VERSION "Mid5CANFD"

NS_ :

BS_:

BU_: ETC SSM VIM

BO_ 1285 SsmMid5CanFdCanNmFr: 8 SSM
 SG_ Body_SSM : 21|1@0+ (1,0) [0|0] ""  VIM
 SG_ Brake_SSM : 33|1@0+ (1,0) [0|0] ""  VIM
 SG_ Diesel_SSM : 32|1@0+ (1,0) [0|0] ""  VIM
 SG_ Hazard_SSM : 18|1@0+ (1,0) [0|0] ""  VIM
 SG_ InfotainmentAndHMI_SSM : 22|1@0+ (1,0) [0|0] ""  VIM
 SG_ PNCCharging_SSM : 25|1@0+ (1,0) [0|0] ""  VIM
 SG_ PNCDriverinfo_SSM : 16|1@0+ (1,0) [0|0] ""  VIM
 SG_ PNCDriverinfoPoll_SSM : 31|1@0+ (1,0) [0|0] ""  VIM
 SG_ PNCDriving_SSM : 27|1@0+ (1,0) [0|0] ""  VIM
 SG_ PNCEntrance_SSM : 23|1@0+ (1,0) [0|0] ""  VIM
 SG_ PNCGlobal_SSM : 29|1@0+ (1,0) [0|0] ""  VIM
 SG_ PNCGSD_SSM : 30|1@0+ (1,0) [0|0] ""  VIM
 SG_ PNCHVEnergyStorage_SSM : 35|1@0+ (1,0) [0|0] ""  VIM
 SG_ PNCLocking_SSM : 17|1@0+ (1,0) [0|0] ""  VIM
 SG_ PNCPreClimatization_SSM : 26|1@0+ (1,0) [0|0] ""  VIM
 SG_ PNCSpare1_SSM : 39|1@0+ (1,0) [0|0] ""  VIM
 SG_ PNCSpare2_SSM : 38|1@0+ (1,0) [0|0] ""  VIM
 SG_ PNCSpare3_SSM : 37|1@0+ (1,0) [0|0] ""  VIM
 SG_ PNCSpare4_SSM : 36|1@0+ (1,0) [0|0] ""  VIM
 SG_ PNCStart_SSM : 24|1@0+ (1,0) [0|0] ""  VIM
 SG_ PNCTrailerCaravan_SSM : 28|1@0+ (1,0) [0|0] ""  VIM
 SG_ VehicleAPI_SSM : 34|1@0+ (1,0) [0|0] ""  VIM
 SG_ Visibility_SSM : 20|1@0+ (1,0) [0|0] ""  VIM
 SG_ WarningSounds_SSM : 19|1@0+ (1,0) [0|0] ""  VIM
 SG_ NM_PNI_SSM : 14|1@0+ (1,0) [0|0] ""  VIM
 SG_ NM_AW_SSM : 12|1@0+ (1,0) [0|0] ""  VIM
 SG_ NM_CS_SSM : 11|1@0+ (1,0) [0|0] ""  VIM
 SG_ NM_RMR_SSM : 8|1@0+ (1,0) [0|0] ""  VIM
 SG_ NM_NodeID_SSM : 7|8@0+ (1,0) [0|0] ""  VIM

BO_ 20 SSMMid5CanFdFr01: 20 SSM
 SG_ PinionSteerAg1 : 14|15@0- (0.0009765625,0) [-14.5|14.5] "rad"  VIM
 SG_ PinionSteerAg1Group_UB : 2|1@0+ (1,0) [0|1] ""  VIM
 SG_ PinionSteerAg1Qf : 1|2@0+ (1,0) [0|3] ""  VIM
 SG_ PinionSteerAgSpd1 : 29|14@0- (0.0078125,0) [-50|50] "rad/s"  VIM
 SG_ PinionSteerAgSpd1Group_UB : 3|1@0+ (1,0) [0|1] ""  VIM
 SG_ PinionSteerAgSpd1Qf : 31|2@0+ (1,0) [0|3] ""  VIM

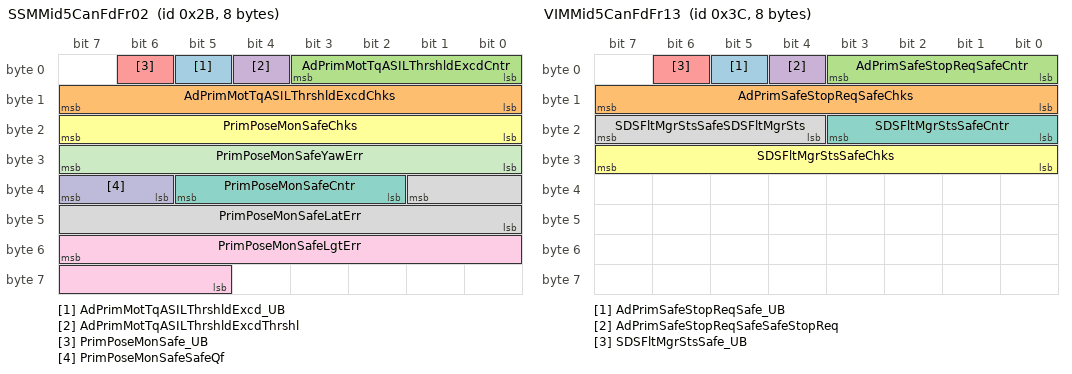
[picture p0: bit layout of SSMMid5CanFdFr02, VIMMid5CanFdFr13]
BO_ 43 SSMMid5CanFdFr02: 8 SSM
 SG_ AdPrimMotTqASILThrshldExcd_UB : 5|1@0+ (1,0) [0|1] ""  VIM
 SG_ AdPrimMotTqASILThrshldExcdChks : 15|8@0+ (1,0) [0|255] "Unitless"  VIM
 SG_ AdPrimMotTqASILThrshldExcdCntr : 3|4@0+ (1,0) [0|15] "Unitless"  VIM
 SG_ AdPrimMotTqASILThrshldExcdThrshl : 4|1@0+ (1,0) [0|1] ""  VIM
 SG_ PrimPoseMonSafe_UB : 6|1@0+ (1,0) [0|1] ""  VIM
 SG_ PrimPoseMonSafeChks : 23|8@0+ (1,0) [0|255] "Unitless"  VIM
 SG_ PrimPoseMonSafeCntr : 37|4@0+ (1,0) [0|15] "Unitless"  VIM
 SG_ PrimPoseMonSafeLatErr : 33|10@0- (0.005,0) [-2.56|2.555] "m"  VIM
 SG_ PrimPoseMonSafeLgtErr : 55|11@0- (0.005,0) [-5.12|5.115] "m"  VIM
 SG_ PrimPoseMonSafeSafeQf : 39|2@0+ (1,0) [0|3] ""  VIM
 SG_ PrimPoseMonSafeYawErr : 31|8@0- (0.001,0) [-0.128|0.127] "rad"  VIM

BO_ 32 SSMMid5CanFdFr03: 64 SSM
 SG_ AdPrimWhlAgEstimdGroupSafe_UB : 4|1@0+ (1,0) [0|1] ""  VIM
 SG_ AdPrimWhlAgEstimdGroupSafeChks : 15|8@0+ (1,0) [0|255] "Unitless"  VIM
 SG_ AdPrimWhlAgEstimdGroupSafeCntr : 3|4@0+ (1,0) [0|15] "Unitless"  VIM
 SG_ AdPrimWhlAgEstimdGroupSafeQf1 : 55|2@0+ (1,0) [0|3] ""  VIM
 SG_ AdPrimWhlAgEstimdGroupSafeWhlAg : 22|15@0+ (5.249E-005,-0.85) [-0.85|0.85004612] "rad"  VIM
 SG_ AdPrimWhlAgEstimdGroupSafeWhlAgR : 38|15@0+ (5E-005,-0.7) [-0.7|0.7] "rad/s"  VIM
 SG_ PrimALatDataRawSafe_UB : 5|1@0+ (1,0) [0|1] ""  VIM
 SG_ PrimALatDataRawSafeChks : 63|8@0+ (1,0) [0|255] "Unitless"  VIM
 SG_ PrimALatDataRawSafeCntr : 51|4@0+ (1,0) [0|15] "Unitless"  VIM
 SG_ PrimALatDataRawSafeMax : 71|15@0+ (0.001,-16.384) [-16.384|16.383] "m/s^2"  VIM
 SG_ PrimALatDataRawSafeMin : 87|15@0+ (0.001,-16.384) [-16.384|16.383] "m/s^2"  VIM
 SG_ PrimALatDataRawSafeMinMaxQf : 119|2@0+ (1,0) [0|3] ""  VIM
 SG_ PrimALatDataRawSafeNom : 103|15@0+ (0.001,-16.384) [-16.384|16.383] "m/s^2"  VIM
 SG_ PrimALatDataRawSafeNomQf : 53|2@0+ (1,0) [0|3] ""  VIM
 SG_ PrimAxleSlipStsAndRelAg_UB : 116|1@0+ (1,0) [0|1] ""  VIM
 SG_ PrimAxleSlipStsAndRelAgFrntAxle : 183|2@0+ (1,0) [0|3] ""  VIM
 SG_ PrimAxleSlipStsAndRelAgIntvSts : 223|2@0+ (1,0) [0|3] ""  VIM
 SG_ PrimAxleSlipStsAndRelAgReAxle : 181|2@0+ (1,0) [0|3] ""  VIM
 SG_ PrimAxleSlipStsAndRelAgRelPitch : 191|16@0- (5E-005,0) [-1.6384|1.6383] "rad"  VIM
 SG_ PrimAxleSlipStsAndRelAgRelPitchQ : 179|2@0+ (1,0) [0|3] ""  VIM
 SG_ PrimAxleSlipStsAndRelAgRelRoll : 207|16@0- (5E-005,0) [-1.6384|1.6383] "rad"  VIM
 SG_ PrimAxleSlipStsAndRelAgRelRolQf : 177|2@0+ (1,0) [0|3] ""  VIM
 SG_ PrimVLatSafe_UB : 396|1@0+ (1,0) [0|1] ""  VIM
 SG_ PrimVLatSafeChks : 415|8@0+ (1,0) [0|255] "Unitless"  VIM
 SG_ PrimVLatSafeCntr : 395|4@0+ (1,0) [0|15] "Unitless"  VIM
 SG_ PrimVLatSafeMax : 422|15@0- (0.001,0) [-16.384|16.383] "m/s"  VIM
 SG_ PrimVLatSafeMin : 438|15@0- (0.001,0) [-16.384|16.383] "m/s"  VIM
 SG_ PrimVLatSafeMinMaxQf : 402|2@0+ (1,0) [0|3] ""  VIM
 SG_ PrimVLatSafeNom : 454|15@0- (0.001,0) [-16.384|16.383] "m/s"  VIM
 SG_ PrimVLatSafeNomQf : 404|2@0+ (1,0) [0|3] ""  VIM
 SG_ PrimWhlRotDirReSafe1_UB : 300|1@0+ (1,0) [0|1] ""  VIM
 SG_ PrimWhlRotDirReSafe1Chks : 319|8@0+ (1,0) [0|255] "Unitless"  VIM
 SG_ PrimWhlRotDirReSafe1Cntr : 299|4@0+ (1,0) [0|15] "Unitless"  VIM
 SG_ PrimWhlRotDirReSafe1Le : 311|2@0+ (1,0) [0|3] ""  VIM
 SG_ PrimWhlRotDirReSafe1LeQf : 309|2@0+ (1,0) [0|3] ""  VIM
 SG_ PrimWhlRotDirReSafe1Ri : 307|2@0+ (1,0) [0|3] ""  VIM
 SG_ PrimWhlRotDirReSafe1RiQf : 305|2@0+ (1,0) [0|3] ""  VIM
 SG_ PrimWhlRotToothCntr_UB : 301|1@0+ (1,0) [0|1] ""  VIM
 SG_ PrimWhlRotToothCntrChks : 335|8@0+ (1,0) [0|255] "Unitless"  VIM
 SG_ PrimWhlRotToothCntrCntr : 323|4@0+ (1,0) [0|15] "Unitless"  VIM
 SG_ PrimWhlRotToothCntrWhlRotToothCn : 343|8@0+ (1,0) [0|255] "Unitless"  VIM
 SG_ PrimWhlRotToothCntrWhlRotTo_0000 : 351|2@0+ (1,0) [0|3] ""  VIM
 SG_ PrimWhlRotToothCntrWhlRotTo_0001 : 359|8@0+ (1,0) [0|255] "Unitless"  VIM
 SG_ PrimWhlRotToothCntrWhlRotTo_0002 : 349|2@0+ (1,0) [0|3] ""  VIM
 SG_ PrimWhlRotToothCntrWhlRotTo_0003 : 367|8@0+ (1,0) [0|255] "Unitless"  VIM
 SG_ PrimWhlRotToothCntrWhlRotTo_0004 : 347|2@0+ (1,0) [0|3] ""  VIM
 SG_ PrimWhlRotToothCntrWhlRotTo_0005 : 375|8@0+ (1,0) [0|255] "Unitless"  VIM
 SG_ PrimWhlRotToothCntrWhlRotTo_0006 : 345|2@0+ (1,0) [0|3] ""  VIM
 SG_ PrimYawRateSafe_UB : 302|1@0+ (1,0) [0|1] ""  VIM
 SG_ PrimYawRateSafeChks : 239|8@0+ (1,0) [0|255] "Unitless"  VIM
 SG_ PrimYawRateSafeCntr : 219|4@0+ (1,0) [0|15] "Unitless"  VIM
 SG_ PrimYawRateSafeMax : 246|15@0- (0.0002,0) [-3.2768|3.2766] "rad/s"  VIM
 SG_ PrimYawRateSafeMin : 262|15@0- (0.0002,0) [-3.2768|3.2766] "rad/s"  VIM
 SG_ PrimYawRateSafeMinMaxQf : 228|2@0+ (1,0) [0|3] ""  VIM
 SG_ PrimYawRateSafeNom : 278|15@0- (0.0002,0) [-3.2768|3.2766] "rad/s"  VIM
 SG_ PrimYawRateSafeNomQf : 225|2@0+ (1,0) [0|3] ""  VIM

BO_ 21 SSMMid5CanFdFr04: 20 SSM
 SG_ PrimVehMSafe_UB : 141|1@0+ (1,0) [0|1] ""  VIM
 SG_ PrimVehMSafeChks : 111|8@0+ (1,0) [0|255] "Unitless"  VIM
 SG_ PrimVehMSafeCntr : 99|4@0+ (1,0) [0|15] "Unitless"  VIM
 SG_ PrimVehMSafeNomQf : 101|2@0+ (1,0) [0|3] ""  VIM
 SG_ PrimVehMSafeSafeQf : 143|2@0+ (1,0) [0|3] ""  VIM
 SG_ PrimVehMSafeVehMMax : 119|8@0+ (5,2400) [2400|3675] "kg"  VIM
 SG_ PrimVehMSafeVehMMin : 127|8@0+ (5,2400) [2400|3675] "kg"  VIM
 SG_ PrimVehMSafeVehMNom : 135|8@0+ (5,2400) [2400|3675] "kg"  VIM
 SG_ PrimWhlAgSpdFrntSafe_UB : 103|1@0+ (1,0) [0|1] ""  VIM
 SG_ PrimWhlAgSpdFrntSafeChks : 15|8@0+ (1,0) [0|255] "Unitless"  VIM
 SG_ PrimWhlAgSpdFrntSafeCntr : 3|4@0+ (1,0) [0|15] "Unitless"  VIM
 SG_ PrimWhlAgSpdFrntSafeLe : 23|16@0- (0.0078125,0) [-255|255] "rad/s"  VIM
 SG_ PrimWhlAgSpdFrntSafeLeQf : 5|2@0+ (1,0) [0|3] ""  VIM
 SG_ PrimWhlAgSpdFrntSafeRi : 39|16@0- (0.0078125,0) [-255|255] "rad/s"  VIM
 SG_ PrimWhlAgSpdFrntSafeRiQf : 7|2@0+ (1,0) [0|3] ""  VIM
 SG_ PrimWhlAgSpdReSafe_UB : 102|1@0+ (1,0) [0|1] ""  VIM
 SG_ PrimWhlAgSpdReSafeChks : 63|8@0+ (1,0) [0|255] "Unitless"  VIM
 SG_ PrimWhlAgSpdReSafeCntr : 51|4@0+ (1,0) [0|15] "Unitless"  VIM
 SG_ PrimWhlAgSpdReSafeLe : 71|16@0- (0.0078125,0) [-255|255] "rad/s"  VIM
 SG_ PrimWhlAgSpdReSafeLeQf : 53|2@0+ (1,0) [0|3] ""  VIM
 SG_ PrimWhlAgSpdReSafeRi : 87|16@0- (0.0078125,0) [-255|255] "rad/s"  VIM
 SG_ PrimWhlAgSpdReSafeRiQf : 55|2@0+ (1,0) [0|3] ""  VIM

BO_ 52 SSMMid5CanFdFr05: 16 SSM
 SG_ AdPrimWhlAgRateLimEstimdSafe_UB : 52|1@0+ (1,0) [0|1] ""  VIM
 SG_ AdPrimWhlAgRateLimEstimdSafeAdWh : 70|15@0+ (5E-005,-0.7) [-0.7|0.7] "rad/s"  VIM
 SG_ AdPrimWhlAgRateLimEstimdSafeChks : 63|8@0+ (1,0) [0|255] "Unitless"  VIM
 SG_ AdPrimWhlAgRateLimEstimdSafeCntr : 51|4@0+ (1,0) [0|15] "Unitless"  VIM
 SG_ PrimMaxALatEstimdGroup_UB : 23|1@0+ (1,0) [0|1] ""  VIM
 SG_ PrimMaxALatEstimdGroupAccelerati : 22|15@0- (0.0085,0) [-138.992|139.0005] "m/s^2"  VIM
 SG_ PrimMaxALatEstimdGroupJerk : 38|15@0- (0.000244140625,0) [-4|3.999755859375] "Unitless"  VIM

BO_ 58 SSMMid5CanFdFr06: 20 SSM
 SG_ AdPrimSafeStopActvGroupSafe_UB : 5|1@0+ (1,0) [0|1] ""  VIM
 SG_ AdPrimSafeStopActvGroupSafeChks : 15|8@0+ (1,0) [0|255] "Unitless"  VIM
 SG_ AdPrimSafeStopActvGroupSafeCntr : 3|4@0+ (1,0) [0|15] "Unitless"  VIM
 SG_ AdPrimSafeStopActvGroupSafePlatf : 4|1@0+ (1,0) [0|1] ""  VIM
 SG_ SSMDegraded_UB : 7|1@0+ (1,0) [0|1] ""  VIM
 SG_ SSMDegradedchks : 79|8@0+ (1,0) [0|255] "Unitless"  VIM
 SG_ SSMDegradedcntr : 67|4@0+ (1,0) [0|15] "Unitless"  VIM
 SG_ SSMDegradedssmdegraded : 71|4@0+ (1,0) [0|15] ""  VIM

BO_ 257 SSMMid5CanFdFr07: 8 SSM
 SG_ SteerMechMonSts : 6|2@0+ (1,0) [0|3] ""  VIM
 SG_ SteerMechMonSts_UB : 7|1@0+ (1,0) [0|1] ""  VIM

BO_ 1286 VimMid5CanFdCanNmFr: 8 VIM
 SG_ Body_VIM : 21|1@0+ (1,0) [0|0] ""  SSM
 SG_ Brake_VIM : 33|1@0+ (1,0) [0|0] ""  SSM
 SG_ Diesel_VIM : 32|1@0+ (1,0) [0|0] ""  SSM
 SG_ Hazard_VIM : 18|1@0+ (1,0) [0|0] ""  SSM
 SG_ InfotainmentAndHMI_VIM : 22|1@0+ (1,0) [0|0] ""  SSM
 SG_ PNCCharging_VIM : 25|1@0+ (1,0) [0|0] ""  SSM
 SG_ PNCDriverinfo_VIM : 16|1@0+ (1,0) [0|0] ""  SSM
 SG_ PNCDriverinfoPoll_VIM : 31|1@0+ (1,0) [0|0] ""  SSM
 SG_ PNCDriving_VIM : 27|1@0+ (1,0) [0|0] ""  SSM
 SG_ PNCEntrance_VIM : 23|1@0+ (1,0) [0|0] ""  SSM
 SG_ PNCGlobal_VIM : 29|1@0+ (1,0) [0|0] ""  SSM
 SG_ PNCGSD_VIM : 30|1@0+ (1,0) [0|0] ""  SSM
 SG_ PNCHVEnergyStorage_VIM : 35|1@0+ (1,0) [0|0] ""  SSM
 SG_ PNCLocking_VIM : 17|1@0+ (1,0) [0|0] ""  SSM
 SG_ PNCPreClimatization_VIM : 26|1@0+ (1,0) [0|0] ""  SSM
 SG_ PNCSpare1_VIM : 39|1@0+ (1,0) [0|0] ""  SSM
 SG_ PNCSpare2_VIM : 38|1@0+ (1,0) [0|0] ""  SSM
 SG_ PNCSpare3_VIM : 37|1@0+ (1,0) [0|0] ""  SSM
 SG_ PNCSpare4_VIM : 36|1@0+ (1,0) [0|0] ""  SSM
 SG_ PNCStart_VIM : 24|1@0+ (1,0) [0|0] ""  SSM
 SG_ PNCTrailerCaravan_VIM : 28|1@0+ (1,0) [0|0] ""  SSM
 SG_ VehicleAPI_VIM : 34|1@0+ (1,0) [0|0] ""  SSM
 SG_ Visibility_VIM : 20|1@0+ (1,0) [0|0] ""  SSM
 SG_ WarningSounds_VIM : 19|1@0+ (1,0) [0|0] ""  SSM
 SG_ NM_PNI_VIM : 14|1@0+ (1,0) [0|0] ""  SSM
 SG_ NM_AW_VIM : 12|1@0+ (1,0) [0|0] ""  SSM
 SG_ NM_CS_VIM : 11|1@0+ (1,0) [0|0] ""  SSM
 SG_ NM_RMR_VIM : 8|1@0+ (1,0) [0|0] ""  SSM
 SG_ NM_NodeID_VIM : 7|8@0+ (1,0) [0|0] ""  SSM

BO_ 33 VIMMid5CanFdFr02: 64 VIM
 SG_ AdPrimPose_UB : 511|1@0+ (1,0) [0|1] ""  SSM
 SG_ AdPrimPoseAX : 24|20@1+ (0.0001,-52.429) [-52.429|52.4285] "m/s^2"  SSM
 SG_ AdPrimPoseAXConf : 400|3@1+ (1,0) [0|7] "Unitless"  SSM
 SG_ AdPrimPoseAY : 48|20@1+ (0.0001,-52.429) [-52.429|52.4285] "m/s^2"  SSM
 SG_ AdPrimPoseAYConf : 408|3@1+ (1,0) [0|7] "Unitless"  SSM
 SG_ AdPrimPoseAZ : 72|20@1+ (0.0001,-52.429) [-52.429|52.4285] "m/s^2"  SSM
 SG_ AdPrimPoseAZConf : 416|3@1+ (1,0) [0|7] "Unitless"  SSM
 SG_ AdPrimPoseChks : 0|16@1+ (1,0) [0|65535] "Unitless"  SSM
 SG_ AdPrimPoseCntr : 16|8@1+ (1,0) [0|255] "Unitless"  SSM
 SG_ AdPrimPoseDataID : 96|16@1+ (1,0) [0|65535] "Unitless"  SSM
 SG_ AdPrimPosePitch : 112|16@1+ (5E-005,-1.638) [-1.638|1.638] "rad"  SSM
 SG_ AdPrimPosePitchConf : 424|3@1+ (1,0) [0|7] "Unitless"  SSM
 SG_ AdPrimPosePitchRate : 128|20@1+ (1E-005,-5.243) [-5.243|5.24275] "rad/s"  SSM
 SG_ AdPrimPosePitchRateConf : 432|3@1+ (1,0) [0|7] "Unitless"  SSM
 SG_ AdPrimPosePosX : 152|32@1- (1,0) [-2147483648|2147483647] "5mm"  SSM
 SG_ AdPrimPosePosXConf : 440|3@1+ (1,0) [0|7] "Unitless"  SSM
 SG_ AdPrimPosePosY : 184|32@1- (1,0) [-2147483648|2147483647] "5mm"  SSM
 SG_ AdPrimPosePosYConf : 448|3@1+ (1,0) [0|7] "Unitless"  SSM
 SG_ AdPrimPoseRoll : 216|16@1+ (5E-005,-1.638) [-1.638|1.638] "rad"  SSM
 SG_ AdPrimPoseRollConf : 456|3@1+ (1,0) [0|7] "Unitless"  SSM
 SG_ AdPrimPoseRollRate : 232|20@1+ (1E-005,-5.243) [-5.243|5.24275] "rad/s"  SSM
 SG_ AdPrimPoseRollRateConf : 464|3@1+ (1,0) [0|7] "Unitless"  SSM
 SG_ AdPrimPoseTiStampNanoSec : 256|32@1+ (1,0) [0|4294967295] "ns"  SSM
 SG_ AdPrimPoseTiStampSec : 288|32@1+ (1,0) [0|4294967295] "s"  SSM
 SG_ AdPrimPoseVX : 320|16@1+ (0.001,-12.768) [-12.768|52.767] "m/s"  SSM
 SG_ AdPrimPoseVXConf : 472|3@1+ (1,0) [0|7] "Unitless"  SSM
 SG_ AdPrimPoseVY : 336|14@1+ (0.001,-8.192) [-8.192|8.191] "m/s"  SSM
 SG_ AdPrimPoseVYConf : 480|3@1+ (1,0) [0|7] "Unitless"  SSM
 SG_ AdPrimPoseYaw : 352|24@1+ (5E-007,-4.194) [-4.194|4.194] "rad"  SSM
 SG_ AdPrimPoseYawConf : 488|3@1+ (1,0) [0|7] "Unitless"  SSM
 SG_ AdPrimPoseYawRate : 376|22@1+ (1E-006,-2.097) [-2.097|2.097] "rad/s"  SSM
 SG_ AdPrimPoseYawRateConf : 496|3@1+ (1,0) [0|7] "Unitless"  SSM

BO_ 65 VIMMid5CanFdFr03: 48 VIM
 SG_ AdPrimPSSGroupSafe0_UB : 375|1@0+ (1,0) [0|1] ""  SSM
 SG_ AdPrimPSSGroupSafe0Chks : 0|16@1+ (1,0) [0|65535] "Unitless"  SSM
 SG_ AdPrimPSSGroupSafe0Cntr : 16|8@1+ (1,0) [0|255] "Unitless"  SSM
 SG_ AdPrimPSSGroupSafe0DataID : 24|16@1+ (1,0) [0|65535] "Unitless"  SSM
 SG_ AdPrimPSSGroupSafe0DeltaTPos1 : 48|18@1+ (1E-006,0) [0|0.262] "s"  SSM
 SG_ AdPrimPSSGroupSafe0DeltaTPos2 : 72|18@1+ (1E-006,0) [0|0.262] "s"  SSM
 SG_ AdPrimPSSGroupSafe0DeltaXPos1 : 96|18@1+ (0.0001,-13.107) [-13.107|13.107] "m"  SSM
 SG_ AdPrimPSSGroupSafe0DeltaXPos2 : 120|18@1+ (0.0001,-13.107) [-13.107|13.107] "m"  SSM
 SG_ AdPrimPSSGroupSafe0DeltaYPos1 : 144|18@1+ (0.0001,-13.107) [-13.107|13.107] "m"  SSM
 SG_ AdPrimPSSGroupSafe0DeltaYPos2 : 168|18@1+ (0.0001,-13.107) [-13.107|13.107] "m"  SSM
 SG_ AdPrimPSSGroupSafe0HeadingPos1 : 192|16@1+ (0.0001,-3.2767) [-3.2767|3.2768] "rad"  SSM
 SG_ AdPrimPSSGroupSafe0HeadingPos2 : 208|16@1+ (0.0001,-3.2767) [-3.2767|3.2768] "rad"  SSM
 SG_ AdPrimPSSGroupSafe0InitHeading : 224|16@1+ (0.0001,-3.2767) [-3.2767|3.2768] "rad"  SSM
 SG_ AdPrimPSSGroupSafe0InitPosX : 240|32@1- (1,0) [-2147483648|2147483647] "m"  SSM
 SG_ AdPrimPSSGroupSafe0InitPosY : 272|32@1- (1,0) [-2147483648|2147483647] "m"  SSM
 SG_ AdPrimPSSGroupSafe0TiStampNanoSe : 304|32@1+ (1,0) [0|4294967295] "Unitless"  SSM
 SG_ AdPrimPSSGroupSafe0TiStampSec : 336|32@1+ (1,0) [0|4294967295] "Unitless"  SSM
 SG_ AdPrimPSSGroupSafe0TrajectID : 40|4@1+ (1,0) [0|15] "Unitless"  SSM

BO_ 68 VIMMid5CanFdFr04: 64 VIM
 SG_ AdPrimPSSGroupSafe1_UB : 511|1@0+ (1,0) [0|1] ""  SSM
 SG_ AdPrimPSSGroupSafe1Chks : 0|16@1+ (1,0) [0|65535] "Unitless"  SSM
 SG_ AdPrimPSSGroupSafe1Cntr : 16|8@1+ (1,0) [0|255] "Unitless"  SSM
 SG_ AdPrimPSSGroupSafe1DataID : 24|16@1+ (1,0) [0|65535] "Unitless"  SSM
 SG_ AdPrimPSSGroupSafe1DeltaTPos1 : 40|18@1+ (1E-006,0) [0|0.262] "s"  SSM
 SG_ AdPrimPSSGroupSafe1DeltaTPos2 : 64|18@1+ (1E-006,0) [0|0.262] "s"  SSM
 SG_ AdPrimPSSGroupSafe1DeltaTPos3 : 88|18@1+ (1E-006,0) [0|0.262] "s"  SSM
 SG_ AdPrimPSSGroupSafe1DeltaTPos4 : 112|18@1+ (1E-006,0) [0|0.262] "s"  SSM
 SG_ AdPrimPSSGroupSafe1DeltaTPos5 : 136|18@1+ (1E-006,0) [0|0.262] "s"  SSM
 SG_ AdPrimPSSGroupSafe1DeltaTPos6 : 160|18@1+ (1E-006,0) [0|0.262] "s"  SSM
 SG_ AdPrimPSSGroupSafe1DeltaXPos1 : 184|18@1+ (0.0001,-13.107) [-13.107|13.107] "m"  SSM
 SG_ AdPrimPSSGroupSafe1DeltaXPos2 : 202|18@1+ (0.0001,-13.107) [-13.107|13.107] "m"  SSM
 SG_ AdPrimPSSGroupSafe1DeltaXPos3 : 220|18@1+ (0.0001,-13.107) [-13.107|13.107] "m"  SSM
 SG_ AdPrimPSSGroupSafe1DeltaXPos4 : 238|18@1+ (0.0001,-13.107) [-13.107|13.107] "m"  SSM
 SG_ AdPrimPSSGroupSafe1DeltaXPos5 : 256|18@1+ (0.0001,-13.107) [-13.107|13.107] "m"  SSM
 SG_ AdPrimPSSGroupSafe1DeltaXPos6 : 274|18@1+ (0.0001,-13.107) [-13.107|13.107] "m"  SSM
 SG_ AdPrimPSSGroupSafe1DeltaYPos1 : 292|18@1+ (0.0001,-13.107) [-13.107|13.107] "m"  SSM
 SG_ AdPrimPSSGroupSafe1DeltaYPos2 : 310|18@1+ (0.0001,-13.107) [-13.107|13.107] "m"  SSM
 SG_ AdPrimPSSGroupSafe1DeltaYPos3 : 328|18@1+ (0.0001,-13.107) [-13.107|13.107] "m"  SSM
 SG_ AdPrimPSSGroupSafe1DeltaYPos4 : 346|18@1+ (0.0001,-13.107) [-13.107|13.107] "m"  SSM
 SG_ AdPrimPSSGroupSafe1DeltaYPos5 : 364|18@1+ (0.0001,-13.107) [-13.107|13.107] "m"  SSM
 SG_ AdPrimPSSGroupSafe1DeltaYPos6 : 382|18@1+ (0.0001,-13.107) [-13.107|13.107] "m"  SSM
 SG_ AdPrimPSSGroupSafe1HeadingPos1 : 400|16@1+ (0.0001,-3.2767) [-3.2767|3.2768] "rad"  SSM
 SG_ AdPrimPSSGroupSafe1HeadingPos2 : 416|16@1+ (0.0001,-3.2767) [-3.2767|3.2768] "rad"  SSM
 SG_ AdPrimPSSGroupSafe1HeadingPos3 : 432|16@1+ (0.0001,-3.2767) [-3.2767|3.2768] "rad"  SSM
 SG_ AdPrimPSSGroupSafe1HeadingPos4 : 448|16@1+ (0.0001,-3.2767) [-3.2767|3.2768] "rad"  SSM
 SG_ AdPrimPSSGroupSafe1HeadingPos5 : 464|16@1+ (0.0001,-3.2767) [-3.2767|3.2768] "rad"  SSM
 SG_ AdPrimPSSGroupSafe1HeadingPos6 : 480|16@1+ (0.0001,-3.2767) [-3.2767|3.2768] "rad"  SSM
 SG_ AdPrimPSSGroupSafe1TrajectID : 496|4@1+ (1,0) [0|15] "Unitless"  SSM

BO_ 72 VIMMid5CanFdFr05: 64 VIM
 SG_ AdPrimPSSGroupSafe2_UB : 511|1@0+ (1,0) [0|1] ""  SSM
 SG_ AdPrimPSSGroupSafe2Chks : 0|16@1+ (1,0) [0|65535] "Unitless"  SSM
 SG_ AdPrimPSSGroupSafe2Cntr : 16|8@1+ (1,0) [0|255] "Unitless"  SSM
 SG_ AdPrimPSSGroupSafe2DataID : 24|16@1+ (1,0) [0|65535] "Unitless"  SSM
 SG_ AdPrimPSSGroupSafe2DeltaTPos1 : 40|18@1+ (1E-006,0) [0|0.262] "s"  SSM
 SG_ AdPrimPSSGroupSafe2DeltaTPos2 : 64|18@1+ (1E-006,0) [0|0.262] "s"  SSM
 SG_ AdPrimPSSGroupSafe2DeltaTPos3 : 88|18@1+ (1E-006,0) [0|0.262] "s"  SSM
 SG_ AdPrimPSSGroupSafe2DeltaTPos4 : 112|18@1+ (1E-006,0) [0|0.262] "s"  SSM
 SG_ AdPrimPSSGroupSafe2DeltaTPos5 : 136|18@1+ (1E-006,0) [0|0.262] "s"  SSM
 SG_ AdPrimPSSGroupSafe2DeltaTPos6 : 160|18@1+ (1E-006,0) [0|0.262] "s"  SSM
 SG_ AdPrimPSSGroupSafe2DeltaXPos1 : 184|18@1+ (0.0001,-13.107) [-13.107|13.107] "m"  SSM
 SG_ AdPrimPSSGroupSafe2DeltaXPos2 : 202|18@1+ (0.0001,-13.107) [-13.107|13.107] "m"  SSM
 SG_ AdPrimPSSGroupSafe2DeltaXPos3 : 220|18@1+ (0.0001,-13.107) [-13.107|13.107] "m"  SSM
 SG_ AdPrimPSSGroupSafe2DeltaXPos4 : 238|18@1+ (0.0001,-13.107) [-13.107|13.107] "m"  SSM
 SG_ AdPrimPSSGroupSafe2DeltaXPos5 : 256|18@1+ (0.0001,-13.107) [-13.107|13.107] "m"  SSM
 SG_ AdPrimPSSGroupSafe2DeltaXPos6 : 274|18@1+ (0.0001,-13.107) [-13.107|13.107] "m"  SSM
 SG_ AdPrimPSSGroupSafe2DeltaYPos1 : 292|18@1+ (0.0001,-13.107) [-13.107|13.107] "m"  SSM
 SG_ AdPrimPSSGroupSafe2DeltaYPos2 : 310|18@1+ (0.0001,-13.107) [-13.107|13.107] "m"  SSM
 SG_ AdPrimPSSGroupSafe2DeltaYPos3 : 328|18@1+ (0.0001,-13.107) [-13.107|13.107] "m"  SSM
 SG_ AdPrimPSSGroupSafe2DeltaYPos4 : 346|18@1+ (0.0001,-13.107) [-13.107|13.107] "m"  SSM
 SG_ AdPrimPSSGroupSafe2DeltaYPos5 : 364|18@1+ (0.0001,-13.107) [-13.107|13.107] "m"  SSM
 SG_ AdPrimPSSGroupSafe2DeltaYPos6 : 382|18@1+ (0.0001,-13.107) [-13.107|13.107] "m"  SSM
 SG_ AdPrimPSSGroupSafe2HeadingPos1 : 400|16@1+ (0.0001,-3.2767) [-3.2767|3.2768] "rad"  SSM
 SG_ AdPrimPSSGroupSafe2HeadingPos2 : 416|16@1+ (0.0001,-3.2767) [-3.2767|3.2768] "rad"  SSM
 SG_ AdPrimPSSGroupSafe2HeadingPos3 : 432|16@1+ (0.0001,-3.2767) [-3.2767|3.2768] "rad"  SSM
 SG_ AdPrimPSSGroupSafe2HeadingPos4 : 448|16@1+ (0.0001,-3.2767) [-3.2767|3.2768] "rad"  SSM
 SG_ AdPrimPSSGroupSafe2HeadingPos5 : 464|16@1+ (0.0001,-3.2767) [-3.2767|3.2768] "rad"  SSM
 SG_ AdPrimPSSGroupSafe2HeadingPos6 : 480|16@1+ (0.0001,-3.2767) [-3.2767|3.2768] "rad"  SSM
 SG_ AdPrimPSSGroupSafe2TrajectID : 496|4@1+ (1,0) [0|15] "Unitless"  SSM

BO_ 82 VIMMid5CanFdFr06: 64 VIM
 SG_ AdPrimPSSGroupSafe3_UB : 511|1@0+ (1,0) [0|1] ""  SSM
 SG_ AdPrimPSSGroupSafe3Chks : 0|16@1+ (1,0) [0|65535] "Unitless"  SSM
 SG_ AdPrimPSSGroupSafe3Cntr : 16|8@1+ (1,0) [0|255] "Unitless"  SSM
 SG_ AdPrimPSSGroupSafe3DataID : 24|16@1+ (1,0) [0|65535] "Unitless"  SSM
 SG_ AdPrimPSSGroupSafe3DeltaTPos1 : 40|18@1+ (1E-006,0) [0|0.262] "s"  SSM
 SG_ AdPrimPSSGroupSafe3DeltaTPos2 : 64|18@1+ (1E-006,0) [0|0.262] "s"  SSM
 SG_ AdPrimPSSGroupSafe3DeltaTPos3 : 88|18@1+ (1E-006,0) [0|0.262] "s"  SSM
 SG_ AdPrimPSSGroupSafe3DeltaTPos4 : 112|18@1+ (1E-006,0) [0|0.262] "s"  SSM
 SG_ AdPrimPSSGroupSafe3DeltaTPos5 : 136|18@1+ (1E-006,0) [0|0.262] "s"  SSM
 SG_ AdPrimPSSGroupSafe3DeltaTPos6 : 160|18@1+ (1E-006,0) [0|0.262] "s"  SSM
 SG_ AdPrimPSSGroupSafe3DeltaXPos1 : 184|18@1+ (0.0001,-13.107) [-13.107|13.107] "m"  SSM
 SG_ AdPrimPSSGroupSafe3DeltaXPos2 : 202|18@1+ (0.0001,-13.107) [-13.107|13.107] "m"  SSM
 SG_ AdPrimPSSGroupSafe3DeltaXPos3 : 220|18@1+ (0.0001,-13.107) [-13.107|13.107] "m"  SSM
 SG_ AdPrimPSSGroupSafe3DeltaXPos4 : 238|18@1+ (0.0001,-13.107) [-13.107|13.107] "m"  SSM
 SG_ AdPrimPSSGroupSafe3DeltaXPos5 : 256|18@1+ (0.0001,-13.107) [-13.107|13.107] "m"  SSM
 SG_ AdPrimPSSGroupSafe3DeltaXPos6 : 274|18@1+ (0.0001,-13.107) [-13.107|13.107] "m"  SSM
 SG_ AdPrimPSSGroupSafe3DeltaYPos1 : 292|18@1+ (0.0001,-13.107) [-13.107|13.107] "m"  SSM
 SG_ AdPrimPSSGroupSafe3DeltaYPos2 : 310|18@1+ (0.0001,-13.107) [-13.107|13.107] "m"  SSM
 SG_ AdPrimPSSGroupSafe3DeltaYPos3 : 328|18@1+ (0.0001,-13.107) [-13.107|13.107] "m"  SSM
 SG_ AdPrimPSSGroupSafe3DeltaYPos4 : 346|18@1+ (0.0001,-13.107) [-13.107|13.107] "m"  SSM
 SG_ AdPrimPSSGroupSafe3DeltaYPos5 : 364|18@1+ (0.0001,-13.107) [-13.107|13.107] "m"  SSM
 SG_ AdPrimPSSGroupSafe3DeltaYPos6 : 382|18@1+ (0.0001,-13.107) [-13.107|13.107] "m"  SSM
 SG_ AdPrimPSSGroupSafe3HeadingPos1 : 400|16@1+ (0.0001,-3.2767) [-3.2767|3.2768] "rad"  SSM
 SG_ AdPrimPSSGroupSafe3HeadingPos2 : 416|16@1+ (0.0001,-3.2767) [-3.2767|3.2768] "rad"  SSM
 SG_ AdPrimPSSGroupSafe3HeadingPos3 : 432|16@1+ (0.0001,-3.2767) [-3.2767|3.2768] "rad"  SSM
 SG_ AdPrimPSSGroupSafe3HeadingPos4 : 448|16@1+ (0.0001,-3.2767) [-3.2767|3.2768] "rad"  SSM
 SG_ AdPrimPSSGroupSafe3HeadingPos5 : 464|16@1+ (0.0001,-3.2767) [-3.2767|3.2768] "rad"  SSM
 SG_ AdPrimPSSGroupSafe3HeadingPos6 : 480|16@1+ (0.0001,-3.2767) [-3.2767|3.2768] "rad"  SSM
 SG_ AdPrimPSSGroupSafe3TrajectID : 496|4@1+ (1,0) [0|15] "Unitless"  SSM

BO_ 84 VIMMid5CanFdFr07: 64 VIM
 SG_ AdPrimPSSGroupSafe4_UB : 511|1@0+ (1,0) [0|1] ""  SSM
 SG_ AdPrimPSSGroupSafe4Chks : 0|16@1+ (1,0) [0|65535] "Unitless"  SSM
 SG_ AdPrimPSSGroupSafe4Cntr : 16|8@1+ (1,0) [0|255] "Unitless"  SSM
 SG_ AdPrimPSSGroupSafe4DataID : 24|16@1+ (1,0) [0|65535] "Unitless"  SSM
 SG_ AdPrimPSSGroupSafe4DeltaTPos1 : 40|18@1+ (1E-006,0) [0|0.262] "s"  SSM
 SG_ AdPrimPSSGroupSafe4DeltaTPos2 : 64|18@1+ (1E-006,0) [0|0.262] "s"  SSM
 SG_ AdPrimPSSGroupSafe4DeltaTPos3 : 88|18@1+ (1E-006,0) [0|0.262] "s"  SSM
 SG_ AdPrimPSSGroupSafe4DeltaTPos4 : 112|18@1+ (1E-006,0) [0|0.262] "s"  SSM
 SG_ AdPrimPSSGroupSafe4DeltaTPos5 : 136|18@1+ (1E-006,0) [0|0.262] "s"  SSM
 SG_ AdPrimPSSGroupSafe4DeltaTPos6 : 160|18@1+ (1E-006,0) [0|0.262] "s"  SSM
 SG_ AdPrimPSSGroupSafe4DeltaXPos1 : 184|18@1+ (0.0001,-13.107) [-13.107|13.107] "m"  SSM
 SG_ AdPrimPSSGroupSafe4DeltaXPos2 : 202|18@1+ (0.0001,-13.107) [-13.107|13.107] "m"  SSM
 SG_ AdPrimPSSGroupSafe4DeltaXPos3 : 220|18@1+ (0.0001,-13.107) [-13.107|13.107] "m"  SSM
 SG_ AdPrimPSSGroupSafe4DeltaXPos4 : 238|18@1+ (0.0001,-13.107) [-13.107|13.107] "m"  SSM
 SG_ AdPrimPSSGroupSafe4DeltaXPos5 : 256|18@1+ (0.0001,-13.107) [-13.107|13.107] "m"  SSM
 SG_ AdPrimPSSGroupSafe4DeltaXPos6 : 274|18@1+ (0.0001,-13.107) [-13.107|13.107] "m"  SSM
 SG_ AdPrimPSSGroupSafe4DeltaYPos1 : 292|18@1+ (0.0001,-13.107) [-13.107|13.107] "m"  SSM
 SG_ AdPrimPSSGroupSafe4DeltaYPos2 : 310|18@1+ (0.0001,-13.107) [-13.107|13.107] "m"  SSM
 SG_ AdPrimPSSGroupSafe4DeltaYPos3 : 328|18@1+ (0.0001,-13.107) [-13.107|13.107] "m"  SSM
 SG_ AdPrimPSSGroupSafe4DeltaYPos4 : 346|18@1+ (0.0001,-13.107) [-13.107|13.107] "m"  SSM
 SG_ AdPrimPSSGroupSafe4DeltaYPos5 : 364|18@1+ (0.0001,-13.107) [-13.107|13.107] "m"  SSM
 SG_ AdPrimPSSGroupSafe4DeltaYPos6 : 382|18@1+ (0.0001,-13.107) [-13.107|13.107] "m"  SSM
 SG_ AdPrimPSSGroupSafe4HeadingPos1 : 400|16@1+ (0.0001,-3.2767) [-3.2767|3.2768] "rad"  SSM
 SG_ AdPrimPSSGroupSafe4HeadingPos2 : 416|16@1+ (0.0001,-3.2767) [-3.2767|3.2768] "rad"  SSM
 SG_ AdPrimPSSGroupSafe4HeadingPos3 : 432|16@1+ (0.0001,-3.2767) [-3.2767|3.2768] "rad"  SSM
 SG_ AdPrimPSSGroupSafe4HeadingPos4 : 448|16@1+ (0.0001,-3.2767) [-3.2767|3.2768] "rad"  SSM
 SG_ AdPrimPSSGroupSafe4HeadingPos5 : 464|16@1+ (0.0001,-3.2767) [-3.2767|3.2768] "rad"  SSM
 SG_ AdPrimPSSGroupSafe4HeadingPos6 : 480|16@1+ (0.0001,-3.2767) [-3.2767|3.2768] "rad"  SSM
 SG_ AdPrimPSSGroupSafe4TrajectID : 496|4@1+ (1,0) [0|15] "Unitless"  SSM

BO_ 88 VIMMid5CanFdFr08: 64 VIM
 SG_ AdPrimPSSGroupSafe5_UB : 511|1@0+ (1,0) [0|1] ""  SSM
 SG_ AdPrimPSSGroupSafe5Chks : 0|16@1+ (1,0) [0|65535] "Unitless"  SSM
 SG_ AdPrimPSSGroupSafe5Cntr : 16|8@1+ (1,0) [0|255] "Unitless"  SSM
 SG_ AdPrimPSSGroupSafe5DataID : 24|16@1+ (1,0) [0|65535] "Unitless"  SSM
 SG_ AdPrimPSSGroupSafe5DeltaTPos1 : 40|18@1+ (1E-006,0) [0|0.262] "s"  SSM
 SG_ AdPrimPSSGroupSafe5DeltaTPos2 : 64|18@1+ (1E-006,0) [0|0.262] "s"  SSM
 SG_ AdPrimPSSGroupSafe5DeltaTPos3 : 88|18@1+ (1E-006,0) [0|0.262] "s"  SSM
 SG_ AdPrimPSSGroupSafe5DeltaTPos4 : 112|18@1+ (1E-006,0) [0|0.262] "s"  SSM
 SG_ AdPrimPSSGroupSafe5DeltaTPos5 : 136|18@1+ (1E-006,0) [0|0.262] "s"  SSM
 SG_ AdPrimPSSGroupSafe5DeltaTPos6 : 160|18@1+ (1E-006,0) [0|0.262] "s"  SSM
 SG_ AdPrimPSSGroupSafe5DeltaXPos1 : 184|18@1+ (0.0001,-13.107) [-13.107|13.107] "m"  SSM
 SG_ AdPrimPSSGroupSafe5DeltaXPos2 : 202|18@1+ (0.0001,-13.107) [-13.107|13.107] "m"  SSM
 SG_ AdPrimPSSGroupSafe5DeltaXPos3 : 220|18@1+ (0.0001,-13.107) [-13.107|13.107] "m"  SSM
 SG_ AdPrimPSSGroupSafe5DeltaXPos4 : 238|18@1+ (0.0001,-13.107) [-13.107|13.107] "m"  SSM
 SG_ AdPrimPSSGroupSafe5DeltaXPos5 : 256|18@1+ (0.0001,-13.107) [-13.107|13.107] "m"  SSM
 SG_ AdPrimPSSGroupSafe5DeltaXPos6 : 274|18@1+ (0.0001,-13.107) [-13.107|13.107] "m"  SSM
 SG_ AdPrimPSSGroupSafe5DeltaYPos1 : 292|18@1+ (0.0001,-13.107) [-13.107|13.107] "m"  SSM
 SG_ AdPrimPSSGroupSafe5DeltaYPos2 : 310|18@1+ (0.0001,-13.107) [-13.107|13.107] "m"  SSM
 SG_ AdPrimPSSGroupSafe5DeltaYPos3 : 328|18@1+ (0.0001,-13.107) [-13.107|13.107] "m"  SSM
 SG_ AdPrimPSSGroupSafe5DeltaYPos4 : 346|18@1+ (0.0001,-13.107) [-13.107|13.107] "m"  SSM
 SG_ AdPrimPSSGroupSafe5DeltaYPos5 : 364|18@1+ (0.0001,-13.107) [-13.107|13.107] "m"  SSM
 SG_ AdPrimPSSGroupSafe5DeltaYPos6 : 382|18@1+ (0.0001,-13.107) [-13.107|13.107] "m"  SSM
 SG_ AdPrimPSSGroupSafe5HeadingPos1 : 400|16@1+ (0.0001,-3.2767) [-3.2767|3.2768] "rad"  SSM
 SG_ AdPrimPSSGroupSafe5HeadingPos2 : 416|16@1+ (0.0001,-3.2767) [-3.2767|3.2768] "rad"  SSM
 SG_ AdPrimPSSGroupSafe5HeadingPos3 : 432|16@1+ (0.0001,-3.2767) [-3.2767|3.2768] "rad"  SSM
 SG_ AdPrimPSSGroupSafe5HeadingPos4 : 448|16@1+ (0.0001,-3.2767) [-3.2767|3.2768] "rad"  SSM
 SG_ AdPrimPSSGroupSafe5HeadingPos5 : 464|16@1+ (0.0001,-3.2767) [-3.2767|3.2768] "rad"  SSM
 SG_ AdPrimPSSGroupSafe5HeadingPos6 : 480|16@1+ (0.0001,-3.2767) [-3.2767|3.2768] "rad"  SSM
 SG_ AdPrimPSSGroupSafe5TrajectID : 496|4@1+ (1,0) [0|15] "Unitless"  SSM

BO_ 98 VIMMid5CanFdFr09: 64 VIM
 SG_ AdPrimPSSGroupSafe6_UB : 511|1@0+ (1,0) [0|1] ""  SSM
 SG_ AdPrimPSSGroupSafe6Chks : 0|16@1+ (1,0) [0|65535] "Unitless"  SSM
 SG_ AdPrimPSSGroupSafe6Cntr : 16|8@1+ (1,0) [0|255] "Unitless"  SSM
 SG_ AdPrimPSSGroupSafe6DataID : 24|16@1+ (1,0) [0|65535] "Unitless"  SSM
 SG_ AdPrimPSSGroupSafe6DeltaTPos1 : 40|18@1+ (1E-006,0) [0|0.262] "s"  SSM
 SG_ AdPrimPSSGroupSafe6DeltaTPos2 : 64|18@1+ (1E-006,0) [0|0.262] "s"  SSM
 SG_ AdPrimPSSGroupSafe6DeltaTPos3 : 88|18@1+ (1E-006,0) [0|0.262] "s"  SSM
 SG_ AdPrimPSSGroupSafe6DeltaTPos4 : 112|18@1+ (1E-006,0) [0|0.262] "s"  SSM
 SG_ AdPrimPSSGroupSafe6DeltaTPos5 : 136|18@1+ (1E-006,0) [0|0.262] "s"  SSM
 SG_ AdPrimPSSGroupSafe6DeltaTPos6 : 160|18@1+ (1E-006,0) [0|0.262] "s"  SSM
 SG_ AdPrimPSSGroupSafe6DeltaXPos1 : 184|18@1+ (0.0001,-13.107) [-13.107|13.107] "m"  SSM
 SG_ AdPrimPSSGroupSafe6DeltaXPos2 : 202|18@1+ (0.0001,-13.107) [-13.107|13.107] "m"  SSM
 SG_ AdPrimPSSGroupSafe6DeltaXPos3 : 220|18@1+ (0.0001,-13.107) [-13.107|13.107] "m"  SSM
 SG_ AdPrimPSSGroupSafe6DeltaXPos4 : 238|18@1+ (0.0001,-13.107) [-13.107|13.107] "m"  SSM
 SG_ AdPrimPSSGroupSafe6DeltaXPos5 : 256|18@1+ (0.0001,-13.107) [-13.107|13.107] "m"  SSM
 SG_ AdPrimPSSGroupSafe6DeltaXPos6 : 274|18@1+ (0.0001,-13.107) [-13.107|13.107] "m"  SSM
 SG_ AdPrimPSSGroupSafe6DeltaYPos1 : 292|18@1+ (0.0001,-13.107) [-13.107|13.107] "m"  SSM
 SG_ AdPrimPSSGroupSafe6DeltaYPos2 : 310|18@1+ (0.0001,-13.107) [-13.107|13.107] "m"  SSM
 SG_ AdPrimPSSGroupSafe6DeltaYPos3 : 328|18@1+ (0.0001,-13.107) [-13.107|13.107] "m"  SSM
 SG_ AdPrimPSSGroupSafe6DeltaYPos4 : 346|18@1+ (0.0001,-13.107) [-13.107|13.107] "m"  SSM
 SG_ AdPrimPSSGroupSafe6DeltaYPos5 : 364|18@1+ (0.0001,-13.107) [-13.107|13.107] "m"  SSM
 SG_ AdPrimPSSGroupSafe6DeltaYPos6 : 382|18@1+ (0.0001,-13.107) [-13.107|13.107] "m"  SSM
 SG_ AdPrimPSSGroupSafe6HeadingPos1 : 400|16@1+ (0.0001,-3.2767) [-3.2767|3.2768] "rad"  SSM
 SG_ AdPrimPSSGroupSafe6HeadingPos2 : 416|16@1+ (0.0001,-3.2767) [-3.2767|3.2768] "rad"  SSM
 SG_ AdPrimPSSGroupSafe6HeadingPos3 : 432|16@1+ (0.0001,-3.2767) [-3.2767|3.2768] "rad"  SSM
 SG_ AdPrimPSSGroupSafe6HeadingPos4 : 448|16@1+ (0.0001,-3.2767) [-3.2767|3.2768] "rad"  SSM
 SG_ AdPrimPSSGroupSafe6HeadingPos5 : 464|16@1+ (0.0001,-3.2767) [-3.2767|3.2768] "rad"  SSM
 SG_ AdPrimPSSGroupSafe6HeadingPos6 : 480|16@1+ (0.0001,-3.2767) [-3.2767|3.2768] "rad"  SSM
 SG_ AdPrimPSSGroupSafe6TrajectID : 496|4@1+ (1,0) [0|15] "Unitless"  SSM

BO_ 100 VIMMid5CanFdFr10: 64 VIM
 SG_ AdPrimPSSGroupSafe7_UB : 511|1@0+ (1,0) [0|1] ""  SSM
 SG_ AdPrimPSSGroupSafe7Chks : 0|16@1+ (1,0) [0|65535] "Unitless"  SSM
 SG_ AdPrimPSSGroupSafe7Cntr : 16|8@1+ (1,0) [0|255] "Unitless"  SSM
 SG_ AdPrimPSSGroupSafe7DataID : 24|16@1+ (1,0) [0|65535] "Unitless"  SSM
 SG_ AdPrimPSSGroupSafe7DeltaTPos1 : 40|18@1+ (1E-006,0) [0|0.262] "s"  SSM
 SG_ AdPrimPSSGroupSafe7DeltaTPos2 : 64|18@1+ (1E-006,0) [0|0.262] "s"  SSM
 SG_ AdPrimPSSGroupSafe7DeltaTPos3 : 88|18@1+ (1E-006,0) [0|0.262] "s"  SSM
 SG_ AdPrimPSSGroupSafe7DeltaTPos4 : 112|18@1+ (1E-006,0) [0|0.262] "s"  SSM
 SG_ AdPrimPSSGroupSafe7DeltaTPos5 : 136|18@1+ (1E-006,0) [0|0.262] "s"  SSM
 SG_ AdPrimPSSGroupSafe7DeltaTPos6 : 160|18@1+ (1E-006,0) [0|0.262] "s"  SSM
 SG_ AdPrimPSSGroupSafe7DeltaXPos1 : 184|18@1+ (0.0001,-13.107) [-13.107|13.107] "m"  SSM
 SG_ AdPrimPSSGroupSafe7DeltaXPos2 : 202|18@1+ (0.0001,-13.107) [-13.107|13.107] "m"  SSM
 SG_ AdPrimPSSGroupSafe7DeltaXPos3 : 220|18@1+ (0.0001,-13.107) [-13.107|13.107] "m"  SSM
 SG_ AdPrimPSSGroupSafe7DeltaXPos4 : 238|18@1+ (0.0001,-13.107) [-13.107|13.107] "m"  SSM
 SG_ AdPrimPSSGroupSafe7DeltaXPos5 : 256|18@1+ (0.0001,-13.107) [-13.107|13.107] "m"  SSM
 SG_ AdPrimPSSGroupSafe7DeltaXPos6 : 274|18@1+ (0.0001,-13.107) [-13.107|13.107] "m"  SSM
 SG_ AdPrimPSSGroupSafe7DeltaYPos1 : 292|18@1+ (0.0001,-13.107) [-13.107|13.107] "m"  SSM
 SG_ AdPrimPSSGroupSafe7DeltaYPos2 : 310|18@1+ (0.0001,-13.107) [-13.107|13.107] "m"  SSM
 SG_ AdPrimPSSGroupSafe7DeltaYPos3 : 328|18@1+ (0.0001,-13.107) [-13.107|13.107] "m"  SSM
 SG_ AdPrimPSSGroupSafe7DeltaYPos4 : 346|18@1+ (0.0001,-13.107) [-13.107|13.107] "m"  SSM
 SG_ AdPrimPSSGroupSafe7DeltaYPos5 : 364|18@1+ (0.0001,-13.107) [-13.107|13.107] "m"  SSM
 SG_ AdPrimPSSGroupSafe7DeltaYPos6 : 382|18@1+ (0.0001,-13.107) [-13.107|13.107] "m"  SSM
 SG_ AdPrimPSSGroupSafe7HeadingPos1 : 400|16@1+ (0.0001,-3.2767) [-3.2767|3.2768] "rad"  SSM
 SG_ AdPrimPSSGroupSafe7HeadingPos2 : 416|16@1+ (0.0001,-3.2767) [-3.2767|3.2768] "rad"  SSM
 SG_ AdPrimPSSGroupSafe7HeadingPos3 : 432|16@1+ (0.0001,-3.2767) [-3.2767|3.2768] "rad"  SSM
 SG_ AdPrimPSSGroupSafe7HeadingPos4 : 448|16@1+ (0.0001,-3.2767) [-3.2767|3.2768] "rad"  SSM
 SG_ AdPrimPSSGroupSafe7HeadingPos5 : 464|16@1+ (0.0001,-3.2767) [-3.2767|3.2768] "rad"  SSM
 SG_ AdPrimPSSGroupSafe7HeadingPos6 : 480|16@1+ (0.0001,-3.2767) [-3.2767|3.2768] "rad"  SSM
 SG_ AdPrimPSSGroupSafe7TrajectID : 496|4@1+ (1,0) [0|15] "Unitless"  SSM

BO_ 104 VIMMid5CanFdFr11: 64 VIM
 SG_ AdPrimPSSGroupSafe8_UB : 511|1@0+ (1,0) [0|1] ""  SSM
 SG_ AdPrimPSSGroupSafe8Chks : 0|16@1+ (1,0) [0|65535] "Unitless"  SSM
 SG_ AdPrimPSSGroupSafe8Cntr : 16|8@1+ (1,0) [0|255] "Unitless"  SSM
 SG_ AdPrimPSSGroupSafe8DataID : 24|16@1+ (1,0) [0|65535] "Unitless"  SSM
 SG_ AdPrimPSSGroupSafe8DeltaTPos1 : 40|18@1+ (1E-006,0) [0|0.262] "s"  SSM
 SG_ AdPrimPSSGroupSafe8DeltaTPos2 : 64|18@1+ (1E-006,0) [0|0.262] "s"  SSM
 SG_ AdPrimPSSGroupSafe8DeltaTPos3 : 88|18@1+ (1E-006,0) [0|0.262] "s"  SSM
 SG_ AdPrimPSSGroupSafe8DeltaTPos4 : 112|18@1+ (1E-006,0) [0|0.262] "s"  SSM
 SG_ AdPrimPSSGroupSafe8DeltaTPos5 : 136|18@1+ (1E-006,0) [0|0.262] "s"  SSM
 SG_ AdPrimPSSGroupSafe8DeltaTPos6 : 160|18@1+ (1E-006,0) [0|0.262] "s"  SSM
 SG_ AdPrimPSSGroupSafe8DeltaXPos1 : 184|18@1+ (0.0001,-13.107) [-13.107|13.107] "m"  SSM
 SG_ AdPrimPSSGroupSafe8DeltaXPos2 : 202|18@1+ (0.0001,-13.107) [-13.107|13.107] "m"  SSM
 SG_ AdPrimPSSGroupSafe8DeltaXPos3 : 220|18@1+ (0.0001,-13.107) [-13.107|13.107] "m"  SSM
 SG_ AdPrimPSSGroupSafe8DeltaXPos4 : 238|18@1+ (0.0001,-13.107) [-13.107|13.107] "m"  SSM
 SG_ AdPrimPSSGroupSafe8DeltaXPos5 : 256|18@1+ (0.0001,-13.107) [-13.107|13.107] "m"  SSM
 SG_ AdPrimPSSGroupSafe8DeltaXPos6 : 274|18@1+ (0.0001,-13.107) [-13.107|13.107] "m"  SSM
 SG_ AdPrimPSSGroupSafe8DeltaYPos1 : 292|18@1+ (0.0001,-13.107) [-13.107|13.107] "m"  SSM
 SG_ AdPrimPSSGroupSafe8DeltaYPos2 : 310|18@1+ (0.0001,-13.107) [-13.107|13.107] "m"  SSM
 SG_ AdPrimPSSGroupSafe8DeltaYPos3 : 328|18@1+ (0.0001,-13.107) [-13.107|13.107] "m"  SSM
 SG_ AdPrimPSSGroupSafe8DeltaYPos4 : 346|18@1+ (0.0001,-13.107) [-13.107|13.107] "m"  SSM
 SG_ AdPrimPSSGroupSafe8DeltaYPos5 : 364|18@1+ (0.0001,-13.107) [-13.107|13.107] "m"  SSM
 SG_ AdPrimPSSGroupSafe8DeltaYPos6 : 382|18@1+ (0.0001,-13.107) [-13.107|13.107] "m"  SSM
 SG_ AdPrimPSSGroupSafe8HeadingPos1 : 400|16@1+ (0.0001,-3.2767) [-3.2767|3.2768] "rad"  SSM
 SG_ AdPrimPSSGroupSafe8HeadingPos2 : 416|16@1+ (0.0001,-3.2767) [-3.2767|3.2768] "rad"  SSM
 SG_ AdPrimPSSGroupSafe8HeadingPos3 : 432|16@1+ (0.0001,-3.2767) [-3.2767|3.2768] "rad"  SSM
 SG_ AdPrimPSSGroupSafe8HeadingPos4 : 448|16@1+ (0.0001,-3.2767) [-3.2767|3.2768] "rad"  SSM
 SG_ AdPrimPSSGroupSafe8HeadingPos5 : 464|16@1+ (0.0001,-3.2767) [-3.2767|3.2768] "rad"  SSM
 SG_ AdPrimPSSGroupSafe8HeadingPos6 : 480|16@1+ (0.0001,-3.2767) [-3.2767|3.2768] "rad"  SSM
 SG_ AdPrimPSSGroupSafe8TrajectID : 496|4@1+ (1,0) [0|15] "Unitless"  SSM

BO_ 34 VIMMid5CanFdFr12: 20 VIM
 SG_ AdPrimWhlAgReqGroupSafe_UB : 7|1@0+ (1,0) [0|1] ""  SSM
 SG_ AdPrimWhlAgReqGroupSafeChks : 15|8@0+ (1,0) [0|255] "Unitless"  SSM
 SG_ AdPrimWhlAgReqGroupSafeCntr : 3|4@0+ (1,0) [0|15] "Unitless"  SSM
 SG_ AdPrimWhlAgReqGroupSafeWhlAgReq : 22|15@0+ (5.249E-005,-0.85) [-0.85|0.85004612] "rad"  SSM

BO_ 60 VIMMid5CanFdFr13: 8 VIM
 SG_ AdPrimSafeStopReqSafe_UB : 5|1@0+ (1,0) [0|1] ""  SSM
 SG_ AdPrimSafeStopReqSafeChks : 15|8@0+ (1,0) [0|255] "Unitless"  SSM
 SG_ AdPrimSafeStopReqSafeCntr : 3|4@0+ (1,0) [0|15] "Unitless"  SSM
 SG_ AdPrimSafeStopReqSafeSafeStopReq : 4|1@0+ (1,0) [0|1] ""  SSM
 SG_ SDSFltMgrStsSafe_UB : 6|1@0+ (1,0) [0|1] ""  SSM
 SG_ SDSFltMgrStsSafeChks : 31|8@0+ (1,0) [0|255] "Unitless"  SSM
 SG_ SDSFltMgrStsSafeCntr : 19|4@0+ (1,0) [0|15] "Unitless"  SSM
 SG_ SDSFltMgrStsSafeSDSFltMgrSts : 23|4@0+ (1,0) [0|15] ""  SSM

BO_ 53 VimMid5CanFdTimeSynchFr: 8 VIM

BO_ 40 VIMPrototypeMid5CanFdFr13: 12 VIM
 SG_ PrimMonTiSyncMsg_UB : 75|1@0+ (1,0) [0|1] ""  SSM
 SG_ PrimMonTiSyncMsgChks : 71|8@0+ (1,0) [0|255] "Unitless"  SSM
 SG_ PrimMonTiSyncMsgCntr : 79|4@0+ (1,0) [0|15] "Unitless"  SSM
 SG_ PrimMonTiSyncMsgTiStampNanoSec : 7|32@0+ (1,0) [0|4294967295] "Unitless"  SSM
 SG_ PrimMonTiSyncMsgTiStampSec : 39|32@0+ (1,0) [0|4294967295] "Unitless"  SSM

CM_ BU_ ETC "External Tester Connector";
CM_ SG_ 20 PinionSteerAg1 "Calculated pinion steer angle at the front steering device Calculated pinion steer angle at the front steering device";
CM_ SG_ 20 PinionSteerAg1Qf "Calculated pinion steer angle at the front steering device Quality factor for PinionSteerAg1";
CM_ SG_ 20 PinionSteerAgSpd1 "Calculated pinion steer angle speed at the front steering device Calculated pinion steer angle speed at the front steering device";
CM_ SG_ 20 PinionSteerAgSpd1Qf "Calculated pinion steer angle speed at the front steering device Quality factor for PinionSteerAgSpd1";
CM_ SG_ 43 AdPrimMotTqASILThrshldExcdChks " E2E protection";
CM_ SG_ 43 AdPrimMotTqASILThrshldExcdCntr " E2E protection";
CM_ SG_ 43 AdPrimMotTqASILThrshldExcdThrshl " Boolean stating if the current operation is within the ASIL-D area of the steering system.";
CM_ SG_ 43 PrimPoseMonSafeChks "Primary Pose monitoring Checksum";
CM_ SG_ 43 PrimPoseMonSafeCntr "Primary Pose monitoring Counter";
CM_ SG_ 43 PrimPoseMonSafeLatErr "Primary Pose monitoring Lateral Error";
CM_ SG_ 43 PrimPoseMonSafeLgtErr "Primary Pose monitoring Longitudinal Error";
CM_ SG_ 43 PrimPoseMonSafeSafeQf "Primary Pose monitoring Quality factor for Longitudinal, Lateral and Yaw Error";
CM_ SG_ 43 PrimPoseMonSafeYawErr "Primary Pose monitoring Yaw Error";
CM_ SG_ 32 AdPrimWhlAgEstimdGroupSafeChks "AD Wheel angle feedback E2E Checksum";
CM_ SG_ 32 AdPrimWhlAgEstimdGroupSafeCntr "AD Wheel angle feedback E2E Counter";
CM_ SG_ 32 AdPrimWhlAgEstimdGroupSafeQf1 "AD Wheel angle feedback Quality Factor of the rack position¨";
CM_ SG_ 32 AdPrimWhlAgEstimdGroupSafeWhlAg "AD Wheel angle feedback Wheel angle estimate";
CM_ SG_ 32 AdPrimWhlAgEstimdGroupSafeWhlAgR "AD Wheel angle feedback Wheel angle rate estimate.";
CM_ SG_ 32 PrimALatDataRawSafeChks "Lateral acceleration estimation (Primary) Checksum";
CM_ SG_ 32 PrimALatDataRawSafeCntr "Lateral acceleration estimation (Primary) Counter";
CM_ SG_ 32 PrimALatDataRawSafeMax "Lateral acceleration estimation (Primary) Maximum Lateral Acceleration";
CM_ SG_ 32 PrimALatDataRawSafeMin "Lateral acceleration estimation (Primary) Minimum Lateral Acceleration";
CM_ SG_ 32 PrimALatDataRawSafeMinMaxQf "Lateral acceleration estimation (Primary) Quality factor for Min and Max signals";
CM_ SG_ 32 PrimALatDataRawSafeNom "Lateral acceleration estimation (Primary) Nominal Lateral Acceleration";
CM_ SG_ 32 PrimALatDataRawSafeNomQf "Lateral acceleration estimation (Primary) Quality factor for Nom signal";
CM_ SG_ 32 PrimAxleSlipStsAndRelAgFrntAxle "Primary:
---------
It contains Front and Rear Axle Slip status, Intervention Status and Relative Roll & Pitch informations. Front axle slip status";
CM_ SG_ 32 PrimAxleSlipStsAndRelAgIntvSts "Primary:
---------
It contains Front and Rear Axle Slip status, Intervention Status and Relative Roll & Pitch informations. Intervention status";
CM_ SG_ 32 PrimAxleSlipStsAndRelAgReAxle "Primary:
---------
It contains Front and Rear Axle Slip status, Intervention Status and Relative Roll & Pitch informations. Rear axle slip status";
CM_ SG_ 32 PrimAxleSlipStsAndRelAgRelPitch "Primary:
---------
It contains Front and Rear Axle Slip status, Intervention Status and Relative Roll & Pitch informations. Relative Pitch";
CM_ SG_ 32 PrimAxleSlipStsAndRelAgRelPitchQ "Primary:
---------
It contains Front and Rear Axle Slip status, Intervention Status and Relative Roll & Pitch informations. Qulality Factor of Relative Pitch";
CM_ SG_ 32 PrimAxleSlipStsAndRelAgRelRoll "Primary:
---------
It contains Front and Rear Axle Slip status, Intervention Status and Relative Roll & Pitch informations. Relative Roll";
CM_ SG_ 32 PrimAxleSlipStsAndRelAgRelRolQf "Primary:
---------
It contains Front and Rear Axle Slip status, Intervention Status and Relative Roll & Pitch informations. Qulality Factor of Relative Roll";
CM_ SG_ 32 PrimVLatSafeChks "Lateral Velocity estimation (Primary) Checksum";
CM_ SG_ 32 PrimVLatSafeCntr "Lateral Velocity estimation (Primary) Counter";
CM_ SG_ 32 PrimVLatSafeMax "Lateral Velocity estimation (Primary) Maximum Lateral Velocity";
CM_ SG_ 32 PrimVLatSafeMin "Lateral Velocity estimation (Primary) Minimum Lateral Velocity";
CM_ SG_ 32 PrimVLatSafeMinMaxQf "Lateral Velocity estimation (Primary) Quality factor for Min and Max signals";
CM_ SG_ 32 PrimVLatSafeNom "Lateral Velocity estimation (Primary) Nominal Lateral Velocity";
CM_ SG_ 32 PrimVLatSafeNomQf "Lateral Velocity estimation (Primary) Quality Factor for Nom signal";
CM_ SG_ 32 PrimWhlRotDirReSafe1Chks "Wheel rotation rear wheel. E2E checksum";
CM_ SG_ 32 PrimWhlRotDirReSafe1Cntr "Wheel rotation rear wheel. E2E Counter";
CM_ SG_ 32 PrimWhlRotDirReSafe1Le "Wheel rotation rear wheel. Left wheel";
CM_ SG_ 32 PrimWhlRotDirReSafe1LeQf "Wheel rotation rear wheel. Qualilty factor of left wheel rotation";
CM_ SG_ 32 PrimWhlRotDirReSafe1Ri "Wheel rotation rear wheel. Right wheel";
CM_ SG_ 32 PrimWhlRotDirReSafe1RiQf "Wheel rotation rear wheel. Quality factor of right wheel rotation";
CM_ SG_ 32 PrimWhlRotToothCntrChks "Added with SCR 515, Vehicle State 519G

WhlRotToothCntrRec signal with Qf. E2E Checksum";
CM_ SG_ 32 PrimWhlRotToothCntrCntr "Added with SCR 515, Vehicle State 519G

WhlRotToothCntrRec signal with Qf. E2E Counter";
CM_ SG_ 32 PrimWhlRotToothCntrWhlRotToothCn "Added with SCR 515, Vehicle State 519G

WhlRotToothCntrRec signal with Qf. Wheel rotation impulse counter front left. For one complete wheel revolution the counter will increase by 96 (with 48 magnetic pole-pairs)";
CM_ SG_ 32 PrimWhlRotToothCntrWhlRotTo_0000 "Added with SCR 515, Vehicle State 519G

WhlRotToothCntrRec signal with Qf. Quality factor for front left wheel";
CM_ SG_ 32 PrimWhlRotToothCntrWhlRotTo_0001 "Added with SCR 515, Vehicle State 519G

WhlRotToothCntrRec signal with Qf. Wheel rotation impulse counter front right. For one complete wheel revolution the counter will increase by 96 (with 48 magnetic pole-pairs)";
CM_ SG_ 32 PrimWhlRotToothCntrWhlRotTo_0002 "Added with SCR 515, Vehicle State 519G

WhlRotToothCntrRec signal with Qf. Quality factor for front right wheel";
CM_ SG_ 32 PrimWhlRotToothCntrWhlRotTo_0003 "Added with SCR 515, Vehicle State 519G

WhlRotToothCntrRec signal with Qf. Wheel rotation impulse counter rear left. For one complete wheel revolution the counter will increase by 96 (with 48 magnetic pole-pairs)";
CM_ SG_ 32 PrimWhlRotToothCntrWhlRotTo_0004 "Added with SCR 515, Vehicle State 519G

WhlRotToothCntrRec signal with Qf. Quality factor for rear left wheel";
CM_ SG_ 32 PrimWhlRotToothCntrWhlRotTo_0005 "Added with SCR 515, Vehicle State 519G

WhlRotToothCntrRec signal with Qf. Wheel rotation impulse counter Rear right. For one complete wheel revolution the counter will increase by 96 (with 48 magnetic pole-pairs)";
CM_ SG_ 32 PrimWhlRotToothCntrWhlRotTo_0006 "Added with SCR 515, Vehicle State 519G

WhlRotToothCntrRec signal with Qf. Quality factor for rear right wheel";
CM_ SG_ 32 PrimYawRateSafeChks "Yaw Rate Estimation (Primary) Checksum";
CM_ SG_ 32 PrimYawRateSafeCntr "Yaw Rate Estimation (Primary) Counter";
CM_ SG_ 32 PrimYawRateSafeMax "Yaw Rate Estimation (Primary) Maximum Yaw Rate";
CM_ SG_ 32 PrimYawRateSafeMin "Yaw Rate Estimation (Primary) Minimum Yaw Rate";
CM_ SG_ 32 PrimYawRateSafeMinMaxQf "Yaw Rate Estimation (Primary) Quality factor for Min and Max signals";
CM_ SG_ 32 PrimYawRateSafeNom "Yaw Rate Estimation (Primary) Nominal Yaw Rate";
CM_ SG_ 32 PrimYawRateSafeNomQf "Yaw Rate Estimation (Primary) Quality factor for Nom signal";
CM_ SG_ 21 PrimVehMSafeChks "Vehicle Mass estimation E2E Checksum";
CM_ SG_ 21 PrimVehMSafeCntr "Vehicle Mass estimation E2E Conter";
CM_ SG_ 21 PrimVehMSafeNomQf "Vehicle Mass estimation Vehicle Mass Nominal Quality factor ";
CM_ SG_ 21 PrimVehMSafeSafeQf "Vehicle Mass estimation Vehicle Mass Min Max Quality factor ";
CM_ SG_ 21 PrimVehMSafeVehMMax "Vehicle Mass estimation Vehicle Mass Maximum Value";
CM_ SG_ 21 PrimVehMSafeVehMMin "Vehicle Mass estimation Vehicle Mass Minimum Value";
CM_ SG_ 21 PrimVehMSafeVehMNom "Vehicle Mass estimation Vehicle Mass Nominal Value";
CM_ SG_ 21 PrimWhlAgSpdFrntSafeChks "Wheel angle speed front wheels, primary channel

Added with SCR 1972, Vehicle State 519G Checksum";
CM_ SG_ 21 PrimWhlAgSpdFrntSafeCntr "Wheel angle speed front wheels, primary channel

Added with SCR 1972, Vehicle State 519G Counter";
CM_ SG_ 21 PrimWhlAgSpdFrntSafeLe "Wheel angle speed front wheels, primary channel

Added with SCR 1972, Vehicle State 519G Angular velocity of left wheel.";
CM_ SG_ 21 PrimWhlAgSpdFrntSafeLeQf "Wheel angle speed front wheels, primary channel

Added with SCR 1972, Vehicle State 519G Qf for wheel speed sensor";
CM_ SG_ 21 PrimWhlAgSpdFrntSafeRi "Wheel angle speed front wheels, primary channel

Added with SCR 1972, Vehicle State 519G Angular velocity of right wheel.";
CM_ SG_ 21 PrimWhlAgSpdFrntSafeRiQf "Wheel angle speed front wheels, primary channel

Added with SCR 1972, Vehicle State 519G Qf for wheel speed sensor";
CM_ SG_ 21 PrimWhlAgSpdReSafeChks "Wheel angle speed rear wheels, primary channel

Added with SCR 1972, Vehicle State 519G Checksum";
CM_ SG_ 21 PrimWhlAgSpdReSafeCntr "Wheel angle speed rear wheels, primary channel

Added with SCR 1972, Vehicle State 519G Counter";
CM_ SG_ 21 PrimWhlAgSpdReSafeLe "Wheel angle speed rear wheels, primary channel

Added with SCR 1972, Vehicle State 519G Angular velocity of left wheel.";
CM_ SG_ 21 PrimWhlAgSpdReSafeLeQf "Wheel angle speed rear wheels, primary channel

Added with SCR 1972, Vehicle State 519G Qf for wheel speed sensor";
CM_ SG_ 21 PrimWhlAgSpdReSafeRi "Wheel angle speed rear wheels, primary channel

Added with SCR 1972, Vehicle State 519G Angular velocity of right wheel.";
CM_ SG_ 21 PrimWhlAgSpdReSafeRiQf "Wheel angle speed rear wheels, primary channel

Added with SCR 1972, Vehicle State 519G Qf for wheel speed sensor";
CM_ SG_ 52 AdPrimWhlAgRateLimEstimdSafeAdWh " Maximum wheel angle rate calculated from limited rack position rate";
CM_ SG_ 52 AdPrimWhlAgRateLimEstimdSafeChks " Checksum";
CM_ SG_ 52 AdPrimWhlAgRateLimEstimdSafeCntr " Counter";
CM_ SG_ 52 PrimMaxALatEstimdGroupAccelerati " Maximum lateral acceleration";
CM_ SG_ 52 PrimMaxALatEstimdGroupJerk " Maximum lateral acceleration rate";
CM_ SG_ 58 AdPrimSafeStopActvGroupSafeChks "Safe stop active E2E checksum";
CM_ SG_ 58 AdPrimSafeStopActvGroupSafeCntr "Safe stop active E2E counter";
CM_ SG_ 58 AdPrimSafeStopActvGroupSafePlatf "Safe stop active Safe stop active";
CM_ SG_ 58 SSMDegradedchks "The signal shall introduce the SSM Status Message via CAN FD 5/6 to the VIM.  checksome";
CM_ SG_ 58 SSMDegradedcntr "The signal shall introduce the SSM Status Message via CAN FD 5/6 to the VIM.  Counter";
CM_ SG_ 58 SSMDegradedssmdegraded "The signal shall introduce the SSM Status Message via CAN FD 5/6 to the VIM.  degradedsignal";
CM_ SG_ 257 SteerMechMonSts "The DATA-ELEM aims to inform relevant system information about the mechnical status of the steering system.
This is done by detecting different levels of offset of the nominal performance.";
CM_ SG_ 33 AdPrimPoseAX "AD POSE information Acceleration X";
CM_ SG_ 33 AdPrimPoseAXConf "AD POSE information Confidence for acceleration X";
CM_ SG_ 33 AdPrimPoseAY "AD POSE information Acceleration Y";
CM_ SG_ 33 AdPrimPoseAYConf "AD POSE information Confidence for acceleration Y";
CM_ SG_ 33 AdPrimPoseAZ "AD POSE information Acceleration Z";
CM_ SG_ 33 AdPrimPoseAZConf "AD POSE information Confidence for acceleration Z";
CM_ SG_ 33 AdPrimPoseChks "AD POSE information E2E profile 5 Check Sum";
CM_ SG_ 33 AdPrimPoseCntr "AD POSE information E2E profile 5 counter";
CM_ SG_ 33 AdPrimPoseDataID "AD POSE information E2E profile 5 Data ID";
CM_ SG_ 33 AdPrimPosePitch "AD POSE information Pitch";
CM_ SG_ 33 AdPrimPosePitchConf "AD POSE information Confidence for pitch";
CM_ SG_ 33 AdPrimPosePitchRate "AD POSE information Pitch rate";
CM_ SG_ 33 AdPrimPosePitchRateConf "AD POSE information Confidence for Pitch rate";
CM_ SG_ 33 AdPrimPosePosX "AD POSE information Position X";
CM_ SG_ 33 AdPrimPosePosXConf "AD POSE information Confidence for position X";
CM_ SG_ 33 AdPrimPosePosY "AD POSE information Position Y";
CM_ SG_ 33 AdPrimPosePosYConf "AD POSE information Confidence for position Y";
CM_ SG_ 33 AdPrimPoseRoll "AD POSE information Roll";
CM_ SG_ 33 AdPrimPoseRollConf "AD POSE information Confidence for Roll";
CM_ SG_ 33 AdPrimPoseRollRate "AD POSE information Roll rate";
CM_ SG_ 33 AdPrimPoseRollRateConf "AD POSE information Confidence for roll rate";
CM_ SG_ 33 AdPrimPoseTiStampNanoSec "AD POSE information Time Stamp Nano Second";
CM_ SG_ 33 AdPrimPoseTiStampSec "AD POSE information Time stampSecond";
CM_ SG_ 33 AdPrimPoseVX "AD POSE information Velocity X";
CM_ SG_ 33 AdPrimPoseVXConf "AD POSE information Confidence for velocity X";
CM_ SG_ 33 AdPrimPoseVY "AD POSE information Velocity Y";
CM_ SG_ 33 AdPrimPoseVYConf "AD POSE information Confidence for velocity Y";
CM_ SG_ 33 AdPrimPoseYaw "AD POSE information Yaw";
CM_ SG_ 33 AdPrimPoseYawConf "AD POSE information Confidence for yaw";
CM_ SG_ 33 AdPrimPoseYawRate "AD POSE information Yaw rate";
CM_ SG_ 33 AdPrimPoseYawRateConf "AD POSE information Confidence for yaw rate";
CM_ SG_ 65 AdPrimPSSGroupSafe0Chks "Platform Safe Stop buffer paths. 

All signalgroups cover 50 points + 1 initial point. Each point has delta X, Y, time and heading. All signal groups are tied together with a trajectory id. 
All signalgroups include signals for E2E protection using profile 5 according to Autosar 4.2.2.

Signal group 0 includes:
* Initial point
* PSS point 1 and 2 E2E checksum, profile 5";
CM_ SG_ 65 AdPrimPSSGroupSafe0Cntr "Platform Safe Stop buffer paths. 

All signalgroups cover 50 points + 1 initial point. Each point has delta X, Y, time and heading. All signal groups are tied together with a trajectory id. 
All signalgroups include signals for E2E protection using profile 5 according to Autosar 4.2.2.

Signal group 0 includes:
* Initial point
* PSS point 1 and 2 E2E Counter, profile 5";
CM_ SG_ 65 AdPrimPSSGroupSafe0DataID "Platform Safe Stop buffer paths. 

All signalgroups cover 50 points + 1 initial point. Each point has delta X, Y, time and heading. All signal groups are tied together with a trajectory id. 
All signalgroups include signals for E2E protection using profile 5 according to Autosar 4.2.2.

Signal group 0 includes:
* Initial point
* PSS point 1 and 2 E2E Data ID, profile 5";
CM_ SG_ 65 AdPrimPSSGroupSafe0DeltaTPos1 "Platform Safe Stop buffer paths. 

All signalgroups cover 50 points + 1 initial point. Each point has delta X, Y, time and heading. All signal groups are tied together with a trajectory id. 
All signalgroups include signals for E2E protection using profile 5 according to Autosar 4.2.2.

Signal group 0 includes:
* Initial point
* PSS point 1 and 2 Delta time position 1";
CM_ SG_ 65 AdPrimPSSGroupSafe0DeltaTPos2 "Platform Safe Stop buffer paths. 

All signalgroups cover 50 points + 1 initial point. Each point has delta X, Y, time and heading. All signal groups are tied together with a trajectory id. 
All signalgroups include signals for E2E protection using profile 5 according to Autosar 4.2.2.

Signal group 0 includes:
* Initial point
* PSS point 1 and 2 Delta time position 2";
CM_ SG_ 65 AdPrimPSSGroupSafe0DeltaXPos1 "Platform Safe Stop buffer paths. 

All signalgroups cover 50 points + 1 initial point. Each point has delta X, Y, time and heading. All signal groups are tied together with a trajectory id. 
All signalgroups include signals for E2E protection using profile 5 according to Autosar 4.2.2.

Signal group 0 includes:
* Initial point
* PSS point 1 and 2 Delta X position 1";
CM_ SG_ 65 AdPrimPSSGroupSafe0DeltaXPos2 "Platform Safe Stop buffer paths. 

All signalgroups cover 50 points + 1 initial point. Each point has delta X, Y, time and heading. All signal groups are tied together with a trajectory id. 
All signalgroups include signals for E2E protection using profile 5 according to Autosar 4.2.2.

Signal group 0 includes:
* Initial point
* PSS point 1 and 2 Delta X position 2";
CM_ SG_ 65 AdPrimPSSGroupSafe0DeltaYPos1 "Platform Safe Stop buffer paths. 

All signalgroups cover 50 points + 1 initial point. Each point has delta X, Y, time and heading. All signal groups are tied together with a trajectory id. 
All signalgroups include signals for E2E protection using profile 5 according to Autosar 4.2.2.

Signal group 0 includes:
* Initial point
* PSS point 1 and 2 Delta Y position 1";
CM_ SG_ 65 AdPrimPSSGroupSafe0DeltaYPos2 "Platform Safe Stop buffer paths. 

All signalgroups cover 50 points + 1 initial point. Each point has delta X, Y, time and heading. All signal groups are tied together with a trajectory id. 
All signalgroups include signals for E2E protection using profile 5 according to Autosar 4.2.2.

Signal group 0 includes:
* Initial point
* PSS point 1 and 2 Delta Y position 2";
CM_ SG_ 65 AdPrimPSSGroupSafe0HeadingPos1 "Platform Safe Stop buffer paths. 

All signalgroups cover 50 points + 1 initial point. Each point has delta X, Y, time and heading. All signal groups are tied together with a trajectory id. 
All signalgroups include signals for E2E protection using profile 5 according to Autosar 4.2.2.

Signal group 0 includes:
* Initial point
* PSS point 1 and 2 Heading position 1";
CM_ SG_ 65 AdPrimPSSGroupSafe0HeadingPos2 "Platform Safe Stop buffer paths. 

All signalgroups cover 50 points + 1 initial point. Each point has delta X, Y, time and heading. All signal groups are tied together with a trajectory id. 
All signalgroups include signals for E2E protection using profile 5 according to Autosar 4.2.2.

Signal group 0 includes:
* Initial point
* PSS point 1 and 2 Heading position 2";
CM_ SG_ 65 AdPrimPSSGroupSafe0InitHeading "Platform Safe Stop buffer paths. 

All signalgroups cover 50 points + 1 initial point. Each point has delta X, Y, time and heading. All signal groups are tied together with a trajectory id. 
All signalgroups include signals for E2E protection using profile 5 according to Autosar 4.2.2.

Signal group 0 includes:
* Initial point
* PSS point 1 and 2 Init heading";
CM_ SG_ 65 AdPrimPSSGroupSafe0InitPosX "Platform Safe Stop buffer paths. 

All signalgroups cover 50 points + 1 initial point. Each point has delta X, Y, time and heading. All signal groups are tied together with a trajectory id. 
All signalgroups include signals for E2E protection using profile 5 according to Autosar 4.2.2.

Signal group 0 includes:
* Initial point
* PSS point 1 and 2 Init position X";
CM_ SG_ 65 AdPrimPSSGroupSafe0InitPosY "Platform Safe Stop buffer paths. 

All signalgroups cover 50 points + 1 initial point. Each point has delta X, Y, time and heading. All signal groups are tied together with a trajectory id. 
All signalgroups include signals for E2E protection using profile 5 according to Autosar 4.2.2.

Signal group 0 includes:
* Initial point
* PSS point 1 and 2 Init position Y";
CM_ SG_ 65 AdPrimPSSGroupSafe0TiStampNanoSe "Platform Safe Stop buffer paths. 

All signalgroups cover 50 points + 1 initial point. Each point has delta X, Y, time and heading. All signal groups are tied together with a trajectory id. 
All signalgroups include signals for E2E protection using profile 5 according to Autosar 4.2.2.

Signal group 0 includes:
* Initial point
* PSS point 1 and 2 Time stamp, nano seconds";
CM_ SG_ 65 AdPrimPSSGroupSafe0TiStampSec "Platform Safe Stop buffer paths. 

All signalgroups cover 50 points + 1 initial point. Each point has delta X, Y, time and heading. All signal groups are tied together with a trajectory id. 
All signalgroups include signals for E2E protection using profile 5 according to Autosar 4.2.2.

Signal group 0 includes:
* Initial point
* PSS point 1 and 2 Time stamp, seconds";
CM_ SG_ 65 AdPrimPSSGroupSafe0TrajectID "Platform Safe Stop buffer paths. 

All signalgroups cover 50 points + 1 initial point. Each point has delta X, Y, time and heading. All signal groups are tied together with a trajectory id. 
All signalgroups include signals for E2E protection using profile 5 according to Autosar 4.2.2.

Signal group 0 includes:
* Initial point
* PSS point 1 and 2 Trajectory ID";
CM_ SG_ 68 AdPrimPSSGroupSafe1Chks "Platform Safe Stop buffer paths. 

All signalgroups cover 50 points + 1 initial point. Each point has delta X, Y, time and heading. All signal groups are tied together with a trajectory id. 
All signalgroups include signals for E2E protection using profile 5 according to Autosar 4.2.2.

Signal group 1 includes:
* 6 PSS points, with overall sequence 3-8
 E2E checksum, profile 5";
CM_ SG_ 68 AdPrimPSSGroupSafe1Cntr "Platform Safe Stop buffer paths. 

All signalgroups cover 50 points + 1 initial point. Each point has delta X, Y, time and heading. All signal groups are tied together with a trajectory id. 
All signalgroups include signals for E2E protection using profile 5 according to Autosar 4.2.2.

Signal group 1 includes:
* 6 PSS points, with overall sequence 3-8
 E2E counter, profile 5";
CM_ SG_ 68 AdPrimPSSGroupSafe1DataID "Platform Safe Stop buffer paths. 

All signalgroups cover 50 points + 1 initial point. Each point has delta X, Y, time and heading. All signal groups are tied together with a trajectory id. 
All signalgroups include signals for E2E protection using profile 5 according to Autosar 4.2.2.

Signal group 1 includes:
* 6 PSS points, with overall sequence 3-8
 E2E Data ID, profile 5";
CM_ SG_ 68 AdPrimPSSGroupSafe1DeltaTPos1 "Platform Safe Stop buffer paths. 

All signalgroups cover 50 points + 1 initial point. Each point has delta X, Y, time and heading. All signal groups are tied together with a trajectory id. 
All signalgroups include signals for E2E protection using profile 5 according to Autosar 4.2.2.

Signal group 1 includes:
* 6 PSS points, with overall sequence 3-8
 Delta time position 1";
CM_ SG_ 68 AdPrimPSSGroupSafe1DeltaTPos2 "Platform Safe Stop buffer paths. 

All signalgroups cover 50 points + 1 initial point. Each point has delta X, Y, time and heading. All signal groups are tied together with a trajectory id. 
All signalgroups include signals for E2E protection using profile 5 according to Autosar 4.2.2.

Signal group 1 includes:
* 6 PSS points, with overall sequence 3-8
 Delta time position 2";
CM_ SG_ 68 AdPrimPSSGroupSafe1DeltaTPos3 "Platform Safe Stop buffer paths. 

All signalgroups cover 50 points + 1 initial point. Each point has delta X, Y, time and heading. All signal groups are tied together with a trajectory id. 
All signalgroups include signals for E2E protection using profile 5 according to Autosar 4.2.2.

Signal group 1 includes:
* 6 PSS points, with overall sequence 3-8
 Delta time position 3";
CM_ SG_ 68 AdPrimPSSGroupSafe1DeltaTPos4 "Platform Safe Stop buffer paths. 

All signalgroups cover 50 points + 1 initial point. Each point has delta X, Y, time and heading. All signal groups are tied together with a trajectory id. 
All signalgroups include signals for E2E protection using profile 5 according to Autosar 4.2.2.

Signal group 1 includes:
* 6 PSS points, with overall sequence 3-8
 Delta time position 4";
CM_ SG_ 68 AdPrimPSSGroupSafe1DeltaTPos5 "Platform Safe Stop buffer paths. 

All signalgroups cover 50 points + 1 initial point. Each point has delta X, Y, time and heading. All signal groups are tied together with a trajectory id. 
All signalgroups include signals for E2E protection using profile 5 according to Autosar 4.2.2.

Signal group 1 includes:
* 6 PSS points, with overall sequence 3-8
 Delta time position 5";
CM_ SG_ 68 AdPrimPSSGroupSafe1DeltaTPos6 "Platform Safe Stop buffer paths. 

All signalgroups cover 50 points + 1 initial point. Each point has delta X, Y, time and heading. All signal groups are tied together with a trajectory id. 
All signalgroups include signals for E2E protection using profile 5 according to Autosar 4.2.2.

Signal group 1 includes:
* 6 PSS points, with overall sequence 3-8
 Delta time position 6";
CM_ SG_ 68 AdPrimPSSGroupSafe1DeltaXPos1 "Platform Safe Stop buffer paths. 

All signalgroups cover 50 points + 1 initial point. Each point has delta X, Y, time and heading. All signal groups are tied together with a trajectory id. 
All signalgroups include signals for E2E protection using profile 5 according to Autosar 4.2.2.

Signal group 1 includes:
* 6 PSS points, with overall sequence 3-8
 Delta X position 1";
CM_ SG_ 68 AdPrimPSSGroupSafe1DeltaXPos2 "Platform Safe Stop buffer paths. 

All signalgroups cover 50 points + 1 initial point. Each point has delta X, Y, time and heading. All signal groups are tied together with a trajectory id. 
All signalgroups include signals for E2E protection using profile 5 according to Autosar 4.2.2.

Signal group 1 includes:
* 6 PSS points, with overall sequence 3-8
 Delta X position 2";
CM_ SG_ 68 AdPrimPSSGroupSafe1DeltaXPos3 "Platform Safe Stop buffer paths. 

All signalgroups cover 50 points + 1 initial point. Each point has delta X, Y, time and heading. All signal groups are tied together with a trajectory id. 
All signalgroups include signals for E2E protection using profile 5 according to Autosar 4.2.2.

Signal group 1 includes:
* 6 PSS points, with overall sequence 3-8
 Delta X position 3";
CM_ SG_ 68 AdPrimPSSGroupSafe1DeltaXPos4 "Platform Safe Stop buffer paths. 

All signalgroups cover 50 points + 1 initial point. Each point has delta X, Y, time and heading. All signal groups are tied together with a trajectory id. 
All signalgroups include signals for E2E protection using profile 5 according to Autosar 4.2.2.

Signal group 1 includes:
* 6 PSS points, with overall sequence 3-8
 Delta X position 4";
CM_ SG_ 68 AdPrimPSSGroupSafe1DeltaXPos5 "Platform Safe Stop buffer paths. 

All signalgroups cover 50 points + 1 initial point. Each point has delta X, Y, time and heading. All signal groups are tied together with a trajectory id. 
All signalgroups include signals for E2E protection using profile 5 according to Autosar 4.2.2.

Signal group 1 includes:
* 6 PSS points, with overall sequence 3-8
 Delta X position 5";
CM_ SG_ 68 AdPrimPSSGroupSafe1DeltaXPos6 "Platform Safe Stop buffer paths. 

All signalgroups cover 50 points + 1 initial point. Each point has delta X, Y, time and heading. All signal groups are tied together with a trajectory id. 
All signalgroups include signals for E2E protection using profile 5 according to Autosar 4.2.2.

Signal group 1 includes:
* 6 PSS points, with overall sequence 3-8
 Delta X position 6";
CM_ SG_ 68 AdPrimPSSGroupSafe1DeltaYPos1 "Platform Safe Stop buffer paths. 

All signalgroups cover 50 points + 1 initial point. Each point has delta X, Y, time and heading. All signal groups are tied together with a trajectory id. 
All signalgroups include signals for E2E protection using profile 5 according to Autosar 4.2.2.

Signal group 1 includes:
* 6 PSS points, with overall sequence 3-8
 Delta Y position 1";
CM_ SG_ 68 AdPrimPSSGroupSafe1DeltaYPos2 "Platform Safe Stop buffer paths. 

All signalgroups cover 50 points + 1 initial point. Each point has delta X, Y, time and heading. All signal groups are tied together with a trajectory id. 
All signalgroups include signals for E2E protection using profile 5 according to Autosar 4.2.2.

Signal group 1 includes:
* 6 PSS points, with overall sequence 3-8
 Delta Y position 2";
CM_ SG_ 68 AdPrimPSSGroupSafe1DeltaYPos3 "Platform Safe Stop buffer paths. 

All signalgroups cover 50 points + 1 initial point. Each point has delta X, Y, time and heading. All signal groups are tied together with a trajectory id. 
All signalgroups include signals for E2E protection using profile 5 according to Autosar 4.2.2.

Signal group 1 includes:
* 6 PSS points, with overall sequence 3-8
 Delta Y position 3";
CM_ SG_ 68 AdPrimPSSGroupSafe1DeltaYPos4 "Platform Safe Stop buffer paths. 

All signalgroups cover 50 points + 1 initial point. Each point has delta X, Y, time and heading. All signal groups are tied together with a trajectory id. 
All signalgroups include signals for E2E protection using profile 5 according to Autosar 4.2.2.

Signal group 1 includes:
* 6 PSS points, with overall sequence 3-8
 Delta Y position 4";
CM_ SG_ 68 AdPrimPSSGroupSafe1DeltaYPos5 "Platform Safe Stop buffer paths. 

All signalgroups cover 50 points + 1 initial point. Each point has delta X, Y, time and heading. All signal groups are tied together with a trajectory id. 
All signalgroups include signals for E2E protection using profile 5 according to Autosar 4.2.2.

Signal group 1 includes:
* 6 PSS points, with overall sequence 3-8
 Delta Y position 5";
CM_ SG_ 68 AdPrimPSSGroupSafe1DeltaYPos6 "Platform Safe Stop buffer paths. 

All signalgroups cover 50 points + 1 initial point. Each point has delta X, Y, time and heading. All signal groups are tied together with a trajectory id. 
All signalgroups include signals for E2E protection using profile 5 according to Autosar 4.2.2.

Signal group 1 includes:
* 6 PSS points, with overall sequence 3-8
 Delta Y position 6";
CM_ SG_ 68 AdPrimPSSGroupSafe1HeadingPos1 "Platform Safe Stop buffer paths. 

All signalgroups cover 50 points + 1 initial point. Each point has delta X, Y, time and heading. All signal groups are tied together with a trajectory id. 
All signalgroups include signals for E2E protection using profile 5 according to Autosar 4.2.2.

Signal group 1 includes:
* 6 PSS points, with overall sequence 3-8
 Heading position 1";
CM_ SG_ 68 AdPrimPSSGroupSafe1HeadingPos2 "Platform Safe Stop buffer paths. 

All signalgroups cover 50 points + 1 initial point. Each point has delta X, Y, time and heading. All signal groups are tied together with a trajectory id. 
All signalgroups include signals for E2E protection using profile 5 according to Autosar 4.2.2.

Signal group 1 includes:
* 6 PSS points, with overall sequence 3-8
 Heading position 2";
CM_ SG_ 68 AdPrimPSSGroupSafe1HeadingPos3 "Platform Safe Stop buffer paths. 

All signalgroups cover 50 points + 1 initial point. Each point has delta X, Y, time and heading. All signal groups are tied together with a trajectory id. 
All signalgroups include signals for E2E protection using profile 5 according to Autosar 4.2.2.

Signal group 1 includes:
* 6 PSS points, with overall sequence 3-8
 Heading position 3";
CM_ SG_ 68 AdPrimPSSGroupSafe1HeadingPos4 "Platform Safe Stop buffer paths. 

All signalgroups cover 50 points + 1 initial point. Each point has delta X, Y, time and heading. All signal groups are tied together with a trajectory id. 
All signalgroups include signals for E2E protection using profile 5 according to Autosar 4.2.2.

Signal group 1 includes:
* 6 PSS points, with overall sequence 3-8
 Heading position 4";
CM_ SG_ 68 AdPrimPSSGroupSafe1HeadingPos5 "Platform Safe Stop buffer paths. 

All signalgroups cover 50 points + 1 initial point. Each point has delta X, Y, time and heading. All signal groups are tied together with a trajectory id. 
All signalgroups include signals for E2E protection using profile 5 according to Autosar 4.2.2.

Signal group 1 includes:
* 6 PSS points, with overall sequence 3-8
 Heading position 5";
CM_ SG_ 68 AdPrimPSSGroupSafe1HeadingPos6 "Platform Safe Stop buffer paths. 

All signalgroups cover 50 points + 1 initial point. Each point has delta X, Y, time and heading. All signal groups are tied together with a trajectory id. 
All signalgroups include signals for E2E protection using profile 5 according to Autosar 4.2.2.

Signal group 1 includes:
* 6 PSS points, with overall sequence 3-8
 Heading position 6";
CM_ SG_ 68 AdPrimPSSGroupSafe1TrajectID "Platform Safe Stop buffer paths. 

All signalgroups cover 50 points + 1 initial point. Each point has delta X, Y, time and heading. All signal groups are tied together with a trajectory id. 
All signalgroups include signals for E2E protection using profile 5 according to Autosar 4.2.2.

Signal group 1 includes:
* 6 PSS points, with overall sequence 3-8
 Trajectory ID";
CM_ SG_ 72 AdPrimPSSGroupSafe2Chks "Platform Safe Stop buffer paths. 

All signalgroups cover 50 points + 1 initial point. Each point has delta X, Y, time and heading. All signal groups are tied together with a trajectory id. 
All signalgroups include signals for E2E protection using profile 5 according to Autosar 4.2.2.

Signal group 2 includes:
* 6 PSS points, with overall sequence 9-14
 E2E checksum, profile 5";
CM_ SG_ 72 AdPrimPSSGroupSafe2Cntr "Platform Safe Stop buffer paths. 

All signalgroups cover 50 points + 1 initial point. Each point has delta X, Y, time and heading. All signal groups are tied together with a trajectory id. 
All signalgroups include signals for E2E protection using profile 5 according to Autosar 4.2.2.

Signal group 2 includes:
* 6 PSS points, with overall sequence 9-14
 E2E counter, profile 5";
CM_ SG_ 72 AdPrimPSSGroupSafe2DataID "Platform Safe Stop buffer paths. 

All signalgroups cover 50 points + 1 initial point. Each point has delta X, Y, time and heading. All signal groups are tied together with a trajectory id. 
All signalgroups include signals for E2E protection using profile 5 according to Autosar 4.2.2.

Signal group 2 includes:
* 6 PSS points, with overall sequence 9-14
 E2E Data ID, profile 5";
CM_ SG_ 72 AdPrimPSSGroupSafe2DeltaTPos1 "Platform Safe Stop buffer paths. 

All signalgroups cover 50 points + 1 initial point. Each point has delta X, Y, time and heading. All signal groups are tied together with a trajectory id. 
All signalgroups include signals for E2E protection using profile 5 according to Autosar 4.2.2.

Signal group 2 includes:
* 6 PSS points, with overall sequence 9-14
 Delta time position 1";
CM_ SG_ 72 AdPrimPSSGroupSafe2DeltaTPos2 "Platform Safe Stop buffer paths. 

All signalgroups cover 50 points + 1 initial point. Each point has delta X, Y, time and heading. All signal groups are tied together with a trajectory id. 
All signalgroups include signals for E2E protection using profile 5 according to Autosar 4.2.2.

Signal group 2 includes:
* 6 PSS points, with overall sequence 9-14
 Delta time position 2";
CM_ SG_ 72 AdPrimPSSGroupSafe2DeltaTPos3 "Platform Safe Stop buffer paths. 

All signalgroups cover 50 points + 1 initial point. Each point has delta X, Y, time and heading. All signal groups are tied together with a trajectory id. 
All signalgroups include signals for E2E protection using profile 5 according to Autosar 4.2.2.

Signal group 2 includes:
* 6 PSS points, with overall sequence 9-14
 Delta time position 3";
CM_ SG_ 72 AdPrimPSSGroupSafe2DeltaTPos4 "Platform Safe Stop buffer paths. 

All signalgroups cover 50 points + 1 initial point. Each point has delta X, Y, time and heading. All signal groups are tied together with a trajectory id. 
All signalgroups include signals for E2E protection using profile 5 according to Autosar 4.2.2.

Signal group 2 includes:
* 6 PSS points, with overall sequence 9-14
 Delta time position 4";
CM_ SG_ 72 AdPrimPSSGroupSafe2DeltaTPos5 "Platform Safe Stop buffer paths. 

All signalgroups cover 50 points + 1 initial point. Each point has delta X, Y, time and heading. All signal groups are tied together with a trajectory id. 
All signalgroups include signals for E2E protection using profile 5 according to Autosar 4.2.2.

Signal group 2 includes:
* 6 PSS points, with overall sequence 9-14
 Delta time position 5";
CM_ SG_ 72 AdPrimPSSGroupSafe2DeltaTPos6 "Platform Safe Stop buffer paths. 

All signalgroups cover 50 points + 1 initial point. Each point has delta X, Y, time and heading. All signal groups are tied together with a trajectory id. 
All signalgroups include signals for E2E protection using profile 5 according to Autosar 4.2.2.

Signal group 2 includes:
* 6 PSS points, with overall sequence 9-14
 Delta time position 6";
CM_ SG_ 72 AdPrimPSSGroupSafe2DeltaXPos1 "Platform Safe Stop buffer paths. 

All signalgroups cover 50 points + 1 initial point. Each point has delta X, Y, time and heading. All signal groups are tied together with a trajectory id. 
All signalgroups include signals for E2E protection using profile 5 according to Autosar 4.2.2.

Signal group 2 includes:
* 6 PSS points, with overall sequence 9-14
 Delta X position 1";
CM_ SG_ 72 AdPrimPSSGroupSafe2DeltaXPos2 "Platform Safe Stop buffer paths. 

All signalgroups cover 50 points + 1 initial point. Each point has delta X, Y, time and heading. All signal groups are tied together with a trajectory id. 
All signalgroups include signals for E2E protection using profile 5 according to Autosar 4.2.2.

Signal group 2 includes:
* 6 PSS points, with overall sequence 9-14
 Delta X position 2";
CM_ SG_ 72 AdPrimPSSGroupSafe2DeltaXPos3 "Platform Safe Stop buffer paths. 

All signalgroups cover 50 points + 1 initial point. Each point has delta X, Y, time and heading. All signal groups are tied together with a trajectory id. 
All signalgroups include signals for E2E protection using profile 5 according to Autosar 4.2.2.

Signal group 2 includes:
* 6 PSS points, with overall sequence 9-14
 Delta X position 3";
CM_ SG_ 72 AdPrimPSSGroupSafe2DeltaXPos4 "Platform Safe Stop buffer paths. 

All signalgroups cover 50 points + 1 initial point. Each point has delta X, Y, time and heading. All signal groups are tied together with a trajectory id. 
All signalgroups include signals for E2E protection using profile 5 according to Autosar 4.2.2.

Signal group 2 includes:
* 6 PSS points, with overall sequence 9-14
 Delta X position 4";
CM_ SG_ 72 AdPrimPSSGroupSafe2DeltaXPos5 "Platform Safe Stop buffer paths. 

All signalgroups cover 50 points + 1 initial point. Each point has delta X, Y, time and heading. All signal groups are tied together with a trajectory id. 
All signalgroups include signals for E2E protection using profile 5 according to Autosar 4.2.2.

Signal group 2 includes:
* 6 PSS points, with overall sequence 9-14
 Delta X position 5";
CM_ SG_ 72 AdPrimPSSGroupSafe2DeltaXPos6 "Platform Safe Stop buffer paths. 

All signalgroups cover 50 points + 1 initial point. Each point has delta X, Y, time and heading. All signal groups are tied together with a trajectory id. 
All signalgroups include signals for E2E protection using profile 5 according to Autosar 4.2.2.

Signal group 2 includes:
* 6 PSS points, with overall sequence 9-14
 Delta X position 6";
CM_ SG_ 72 AdPrimPSSGroupSafe2DeltaYPos1 "Platform Safe Stop buffer paths. 

All signalgroups cover 50 points + 1 initial point. Each point has delta X, Y, time and heading. All signal groups are tied together with a trajectory id. 
All signalgroups include signals for E2E protection using profile 5 according to Autosar 4.2.2.

Signal group 2 includes:
* 6 PSS points, with overall sequence 9-14
 Delta Y position 1";
CM_ SG_ 72 AdPrimPSSGroupSafe2DeltaYPos2 "Platform Safe Stop buffer paths. 

All signalgroups cover 50 points + 1 initial point. Each point has delta X, Y, time and heading. All signal groups are tied together with a trajectory id. 
All signalgroups include signals for E2E protection using profile 5 according to Autosar 4.2.2.

Signal group 2 includes:
* 6 PSS points, with overall sequence 9-14
 Delta Y position 2";
CM_ SG_ 72 AdPrimPSSGroupSafe2DeltaYPos3 "Platform Safe Stop buffer paths. 

All signalgroups cover 50 points + 1 initial point. Each point has delta X, Y, time and heading. All signal groups are tied together with a trajectory id. 
All signalgroups include signals for E2E protection using profile 5 according to Autosar 4.2.2.

Signal group 2 includes:
* 6 PSS points, with overall sequence 9-14
 Delta Y position 3";
CM_ SG_ 72 AdPrimPSSGroupSafe2DeltaYPos4 "Platform Safe Stop buffer paths. 

All signalgroups cover 50 points + 1 initial point. Each point has delta X, Y, time and heading. All signal groups are tied together with a trajectory id. 
All signalgroups include signals for E2E protection using profile 5 according to Autosar 4.2.2.

Signal group 2 includes:
* 6 PSS points, with overall sequence 9-14
 Delta Y position 4";
CM_ SG_ 72 AdPrimPSSGroupSafe2DeltaYPos5 "Platform Safe Stop buffer paths. 

All signalgroups cover 50 points + 1 initial point. Each point has delta X, Y, time and heading. All signal groups are tied together with a trajectory id. 
All signalgroups include signals for E2E protection using profile 5 according to Autosar 4.2.2.

Signal group 2 includes:
* 6 PSS points, with overall sequence 9-14
 Delta Y position 5";
CM_ SG_ 72 AdPrimPSSGroupSafe2DeltaYPos6 "Platform Safe Stop buffer paths. 

All signalgroups cover 50 points + 1 initial point. Each point has delta X, Y, time and heading. All signal groups are tied together with a trajectory id. 
All signalgroups include signals for E2E protection using profile 5 according to Autosar 4.2.2.

Signal group 2 includes:
* 6 PSS points, with overall sequence 9-14
 Delta Y position 6";
CM_ SG_ 72 AdPrimPSSGroupSafe2HeadingPos1 "Platform Safe Stop buffer paths. 

All signalgroups cover 50 points + 1 initial point. Each point has delta X, Y, time and heading. All signal groups are tied together with a trajectory id. 
All signalgroups include signals for E2E protection using profile 5 according to Autosar 4.2.2.

Signal group 2 includes:
* 6 PSS points, with overall sequence 9-14
 Heading position 1";
CM_ SG_ 72 AdPrimPSSGroupSafe2HeadingPos2 "Platform Safe Stop buffer paths. 

All signalgroups cover 50 points + 1 initial point. Each point has delta X, Y, time and heading. All signal groups are tied together with a trajectory id. 
All signalgroups include signals for E2E protection using profile 5 according to Autosar 4.2.2.

Signal group 2 includes:
* 6 PSS points, with overall sequence 9-14
 Heading position 2";
CM_ SG_ 72 AdPrimPSSGroupSafe2HeadingPos3 "Platform Safe Stop buffer paths. 

All signalgroups cover 50 points + 1 initial point. Each point has delta X, Y, time and heading. All signal groups are tied together with a trajectory id. 
All signalgroups include signals for E2E protection using profile 5 according to Autosar 4.2.2.

Signal group 2 includes:
* 6 PSS points, with overall sequence 9-14
 Heading position 3";
CM_ SG_ 72 AdPrimPSSGroupSafe2HeadingPos4 "Platform Safe Stop buffer paths. 

All signalgroups cover 50 points + 1 initial point. Each point has delta X, Y, time and heading. All signal groups are tied together with a trajectory id. 
All signalgroups include signals for E2E protection using profile 5 according to Autosar 4.2.2.

Signal group 2 includes:
* 6 PSS points, with overall sequence 9-14
 Heading position 4";
CM_ SG_ 72 AdPrimPSSGroupSafe2HeadingPos5 "Platform Safe Stop buffer paths. 

All signalgroups cover 50 points + 1 initial point. Each point has delta X, Y, time and heading. All signal groups are tied together with a trajectory id. 
All signalgroups include signals for E2E protection using profile 5 according to Autosar 4.2.2.

Signal group 2 includes:
* 6 PSS points, with overall sequence 9-14
 Heading position 5";
CM_ SG_ 72 AdPrimPSSGroupSafe2HeadingPos6 "Platform Safe Stop buffer paths. 

All signalgroups cover 50 points + 1 initial point. Each point has delta X, Y, time and heading. All signal groups are tied together with a trajectory id. 
All signalgroups include signals for E2E protection using profile 5 according to Autosar 4.2.2.

Signal group 2 includes:
* 6 PSS points, with overall sequence 9-14
 Heading position 6";
CM_ SG_ 72 AdPrimPSSGroupSafe2TrajectID "Platform Safe Stop buffer paths. 

All signalgroups cover 50 points + 1 initial point. Each point has delta X, Y, time and heading. All signal groups are tied together with a trajectory id. 
All signalgroups include signals for E2E protection using profile 5 according to Autosar 4.2.2.

Signal group 2 includes:
* 6 PSS points, with overall sequence 9-14
 Trajectory ID";
CM_ SG_ 82 AdPrimPSSGroupSafe3Chks "Platform Safe Stop buffer paths. 

All signalgroups cover 50 points + 1 initial point. Each point has delta X, Y, time and heading. All signal groups are tied together with a trajectory id. 
All signalgroups include signals for E2E protection using profile 5 according to Autosar 4.2.2.

Signal group 3 includes:
* 6 PSS points, with overall sequence 15-20
 E2E checksum, profile 5";
CM_ SG_ 82 AdPrimPSSGroupSafe3Cntr "Platform Safe Stop buffer paths. 

All signalgroups cover 50 points + 1 initial point. Each point has delta X, Y, time and heading. All signal groups are tied together with a trajectory id. 
All signalgroups include signals for E2E protection using profile 5 according to Autosar 4.2.2.

Signal group 3 includes:
* 6 PSS points, with overall sequence 15-20
 E2E counter, profile 5";
CM_ SG_ 82 AdPrimPSSGroupSafe3DataID "Platform Safe Stop buffer paths. 

All signalgroups cover 50 points + 1 initial point. Each point has delta X, Y, time and heading. All signal groups are tied together with a trajectory id. 
All signalgroups include signals for E2E protection using profile 5 according to Autosar 4.2.2.

Signal group 3 includes:
* 6 PSS points, with overall sequence 15-20
 E2E Data ID, profile 5";
CM_ SG_ 82 AdPrimPSSGroupSafe3DeltaTPos1 "Platform Safe Stop buffer paths. 

All signalgroups cover 50 points + 1 initial point. Each point has delta X, Y, time and heading. All signal groups are tied together with a trajectory id. 
All signalgroups include signals for E2E protection using profile 5 according to Autosar 4.2.2.

Signal group 3 includes:
* 6 PSS points, with overall sequence 15-20
 Delta time position 1";
CM_ SG_ 82 AdPrimPSSGroupSafe3DeltaTPos2 "Platform Safe Stop buffer paths. 

All signalgroups cover 50 points + 1 initial point. Each point has delta X, Y, time and heading. All signal groups are tied together with a trajectory id. 
All signalgroups include signals for E2E protection using profile 5 according to Autosar 4.2.2.

Signal group 3 includes:
* 6 PSS points, with overall sequence 15-20
 Delta time position 2";
CM_ SG_ 82 AdPrimPSSGroupSafe3DeltaTPos3 "Platform Safe Stop buffer paths. 

All signalgroups cover 50 points + 1 initial point. Each point has delta X, Y, time and heading. All signal groups are tied together with a trajectory id. 
All signalgroups include signals for E2E protection using profile 5 according to Autosar 4.2.2.

Signal group 3 includes:
* 6 PSS points, with overall sequence 15-20
 Delta time position 3";
CM_ SG_ 82 AdPrimPSSGroupSafe3DeltaTPos4 "Platform Safe Stop buffer paths. 

All signalgroups cover 50 points + 1 initial point. Each point has delta X, Y, time and heading. All signal groups are tied together with a trajectory id. 
All signalgroups include signals for E2E protection using profile 5 according to Autosar 4.2.2.

Signal group 3 includes:
* 6 PSS points, with overall sequence 15-20
 Delta time position 4";
CM_ SG_ 82 AdPrimPSSGroupSafe3DeltaTPos5 "Platform Safe Stop buffer paths. 

All signalgroups cover 50 points + 1 initial point. Each point has delta X, Y, time and heading. All signal groups are tied together with a trajectory id. 
All signalgroups include signals for E2E protection using profile 5 according to Autosar 4.2.2.

Signal group 3 includes:
* 6 PSS points, with overall sequence 15-20
 Delta time position 5";
CM_ SG_ 82 AdPrimPSSGroupSafe3DeltaTPos6 "Platform Safe Stop buffer paths. 

All signalgroups cover 50 points + 1 initial point. Each point has delta X, Y, time and heading. All signal groups are tied together with a trajectory id. 
All signalgroups include signals for E2E protection using profile 5 according to Autosar 4.2.2.

Signal group 3 includes:
* 6 PSS points, with overall sequence 15-20
 Delta time position 6";
CM_ SG_ 82 AdPrimPSSGroupSafe3DeltaXPos1 "Platform Safe Stop buffer paths. 

All signalgroups cover 50 points + 1 initial point. Each point has delta X, Y, time and heading. All signal groups are tied together with a trajectory id. 
All signalgroups include signals for E2E protection using profile 5 according to Autosar 4.2.2.

Signal group 3 includes:
* 6 PSS points, with overall sequence 15-20
 Delta X position 1";
CM_ SG_ 82 AdPrimPSSGroupSafe3DeltaXPos2 "Platform Safe Stop buffer paths. 

All signalgroups cover 50 points + 1 initial point. Each point has delta X, Y, time and heading. All signal groups are tied together with a trajectory id. 
All signalgroups include signals for E2E protection using profile 5 according to Autosar 4.2.2.

Signal group 3 includes:
* 6 PSS points, with overall sequence 15-20
 Delta X position 2";
CM_ SG_ 82 AdPrimPSSGroupSafe3DeltaXPos3 "Platform Safe Stop buffer paths. 

All signalgroups cover 50 points + 1 initial point. Each point has delta X, Y, time and heading. All signal groups are tied together with a trajectory id. 
All signalgroups include signals for E2E protection using profile 5 according to Autosar 4.2.2.

Signal group 3 includes:
* 6 PSS points, with overall sequence 15-20
 Delta X position 3";
CM_ SG_ 82 AdPrimPSSGroupSafe3DeltaXPos4 "Platform Safe Stop buffer paths. 

All signalgroups cover 50 points + 1 initial point. Each point has delta X, Y, time and heading. All signal groups are tied together with a trajectory id. 
All signalgroups include signals for E2E protection using profile 5 according to Autosar 4.2.2.

Signal group 3 includes:
* 6 PSS points, with overall sequence 15-20
 Delta X position 4";
CM_ SG_ 82 AdPrimPSSGroupSafe3DeltaXPos5 "Platform Safe Stop buffer paths. 

All signalgroups cover 50 points + 1 initial point. Each point has delta X, Y, time and heading. All signal groups are tied together with a trajectory id. 
All signalgroups include signals for E2E protection using profile 5 according to Autosar 4.2.2.

Signal group 3 includes:
* 6 PSS points, with overall sequence 15-20
 Delta X position 5";
CM_ SG_ 82 AdPrimPSSGroupSafe3DeltaXPos6 "Platform Safe Stop buffer paths. 

All signalgroups cover 50 points + 1 initial point. Each point has delta X, Y, time and heading. All signal groups are tied together with a trajectory id. 
All signalgroups include signals for E2E protection using profile 5 according to Autosar 4.2.2.

Signal group 3 includes:
* 6 PSS points, with overall sequence 15-20
 Delta X position 6";
CM_ SG_ 82 AdPrimPSSGroupSafe3DeltaYPos1 "Platform Safe Stop buffer paths. 

All signalgroups cover 50 points + 1 initial point. Each point has delta X, Y, time and heading. All signal groups are tied together with a trajectory id. 
All signalgroups include signals for E2E protection using profile 5 according to Autosar 4.2.2.

Signal group 3 includes:
* 6 PSS points, with overall sequence 15-20
 Delta Y position 1";
CM_ SG_ 82 AdPrimPSSGroupSafe3DeltaYPos2 "Platform Safe Stop buffer paths. 

All signalgroups cover 50 points + 1 initial point. Each point has delta X, Y, time and heading. All signal groups are tied together with a trajectory id. 
All signalgroups include signals for E2E protection using profile 5 according to Autosar 4.2.2.

Signal group 3 includes:
* 6 PSS points, with overall sequence 15-20
 Delta Y position 2";
CM_ SG_ 82 AdPrimPSSGroupSafe3DeltaYPos3 "Platform Safe Stop buffer paths. 

All signalgroups cover 50 points + 1 initial point. Each point has delta X, Y, time and heading. All signal groups are tied together with a trajectory id. 
All signalgroups include signals for E2E protection using profile 5 according to Autosar 4.2.2.

Signal group 3 includes:
* 6 PSS points, with overall sequence 15-20
 Delta Y position 3";
CM_ SG_ 82 AdPrimPSSGroupSafe3DeltaYPos4 "Platform Safe Stop buffer paths. 

All signalgroups cover 50 points + 1 initial point. Each point has delta X, Y, time and heading. All signal groups are tied together with a trajectory id. 
All signalgroups include signals for E2E protection using profile 5 according to Autosar 4.2.2.

Signal group 3 includes:
* 6 PSS points, with overall sequence 15-20
 Delta Y position 4";
CM_ SG_ 82 AdPrimPSSGroupSafe3DeltaYPos5 "Platform Safe Stop buffer paths. 

All signalgroups cover 50 points + 1 initial point. Each point has delta X, Y, time and heading. All signal groups are tied together with a trajectory id. 
All signalgroups include signals for E2E protection using profile 5 according to Autosar 4.2.2.

Signal group 3 includes:
* 6 PSS points, with overall sequence 15-20
 Delta Y position 5";
CM_ SG_ 82 AdPrimPSSGroupSafe3DeltaYPos6 "Platform Safe Stop buffer paths. 

All signalgroups cover 50 points + 1 initial point. Each point has delta X, Y, time and heading. All signal groups are tied together with a trajectory id. 
All signalgroups include signals for E2E protection using profile 5 according to Autosar 4.2.2.

Signal group 3 includes:
* 6 PSS points, with overall sequence 15-20
 Delta Y position 6";
CM_ SG_ 82 AdPrimPSSGroupSafe3HeadingPos1 "Platform Safe Stop buffer paths. 

All signalgroups cover 50 points + 1 initial point. Each point has delta X, Y, time and heading. All signal groups are tied together with a trajectory id. 
All signalgroups include signals for E2E protection using profile 5 according to Autosar 4.2.2.

Signal group 3 includes:
* 6 PSS points, with overall sequence 15-20
 Heading position 1";
CM_ SG_ 82 AdPrimPSSGroupSafe3HeadingPos2 "Platform Safe Stop buffer paths. 

All signalgroups cover 50 points + 1 initial point. Each point has delta X, Y, time and heading. All signal groups are tied together with a trajectory id. 
All signalgroups include signals for E2E protection using profile 5 according to Autosar 4.2.2.

Signal group 3 includes:
* 6 PSS points, with overall sequence 15-20
 Heading position 2";
CM_ SG_ 82 AdPrimPSSGroupSafe3HeadingPos3 "Platform Safe Stop buffer paths. 

All signalgroups cover 50 points + 1 initial point. Each point has delta X, Y, time and heading. All signal groups are tied together with a trajectory id. 
All signalgroups include signals for E2E protection using profile 5 according to Autosar 4.2.2.

Signal group 3 includes:
* 6 PSS points, with overall sequence 15-20
 Heading position 3";
CM_ SG_ 82 AdPrimPSSGroupSafe3HeadingPos4 "Platform Safe Stop buffer paths. 

All signalgroups cover 50 points + 1 initial point. Each point has delta X, Y, time and heading. All signal groups are tied together with a trajectory id. 
All signalgroups include signals for E2E protection using profile 5 according to Autosar 4.2.2.

Signal group 3 includes:
* 6 PSS points, with overall sequence 15-20
 Heading position 4";
CM_ SG_ 82 AdPrimPSSGroupSafe3HeadingPos5 "Platform Safe Stop buffer paths. 

All signalgroups cover 50 points + 1 initial point. Each point has delta X, Y, time and heading. All signal groups are tied together with a trajectory id. 
All signalgroups include signals for E2E protection using profile 5 according to Autosar 4.2.2.

Signal group 3 includes:
* 6 PSS points, with overall sequence 15-20
 Heading position 5";
CM_ SG_ 82 AdPrimPSSGroupSafe3HeadingPos6 "Platform Safe Stop buffer paths. 

All signalgroups cover 50 points + 1 initial point. Each point has delta X, Y, time and heading. All signal groups are tied together with a trajectory id. 
All signalgroups include signals for E2E protection using profile 5 according to Autosar 4.2.2.

Signal group 3 includes:
* 6 PSS points, with overall sequence 15-20
 Heading position 6";
CM_ SG_ 82 AdPrimPSSGroupSafe3TrajectID "Platform Safe Stop buffer paths. 

All signalgroups cover 50 points + 1 initial point. Each point has delta X, Y, time and heading. All signal groups are tied together with a trajectory id. 
All signalgroups include signals for E2E protection using profile 5 according to Autosar 4.2.2.

Signal group 3 includes:
* 6 PSS points, with overall sequence 15-20
 Trajectory ID";
CM_ SG_ 84 AdPrimPSSGroupSafe4Chks "Platform Safe Stop buffer paths. 

All signalgroups cover 50 points + 1 initial point. Each point has delta X, Y, time and heading. All signal groups are tied together with a trajectory id. 
All signalgroups include signals for E2E protection using profile 5 according to Autosar 4.2.2.

Signal group 4 includes:
* 6 PSS points, with overall sequence 21-26
 E2E checksum, profile 5";
CM_ SG_ 84 AdPrimPSSGroupSafe4Cntr "Platform Safe Stop buffer paths. 

All signalgroups cover 50 points + 1 initial point. Each point has delta X, Y, time and heading. All signal groups are tied together with a trajectory id. 
All signalgroups include signals for E2E protection using profile 5 according to Autosar 4.2.2.

Signal group 4 includes:
* 6 PSS points, with overall sequence 21-26
 E2E counter, profile 5";
CM_ SG_ 84 AdPrimPSSGroupSafe4DataID "Platform Safe Stop buffer paths. 

All signalgroups cover 50 points + 1 initial point. Each point has delta X, Y, time and heading. All signal groups are tied together with a trajectory id. 
All signalgroups include signals for E2E protection using profile 5 according to Autosar 4.2.2.

Signal group 4 includes:
* 6 PSS points, with overall sequence 21-26
 E2E Data ID, profile 5";
CM_ SG_ 84 AdPrimPSSGroupSafe4DeltaTPos1 "Platform Safe Stop buffer paths. 

All signalgroups cover 50 points + 1 initial point. Each point has delta X, Y, time and heading. All signal groups are tied together with a trajectory id. 
All signalgroups include signals for E2E protection using profile 5 according to Autosar 4.2.2.

Signal group 4 includes:
* 6 PSS points, with overall sequence 21-26
 Delta time position 1";
CM_ SG_ 84 AdPrimPSSGroupSafe4DeltaTPos2 "Platform Safe Stop buffer paths. 

All signalgroups cover 50 points + 1 initial point. Each point has delta X, Y, time and heading. All signal groups are tied together with a trajectory id. 
All signalgroups include signals for E2E protection using profile 5 according to Autosar 4.2.2.

Signal group 4 includes:
* 6 PSS points, with overall sequence 21-26
 Delta time position 2";
CM_ SG_ 84 AdPrimPSSGroupSafe4DeltaTPos3 "Platform Safe Stop buffer paths. 

All signalgroups cover 50 points + 1 initial point. Each point has delta X, Y, time and heading. All signal groups are tied together with a trajectory id. 
All signalgroups include signals for E2E protection using profile 5 according to Autosar 4.2.2.

Signal group 4 includes:
* 6 PSS points, with overall sequence 21-26
 Delta time position 3";
CM_ SG_ 84 AdPrimPSSGroupSafe4DeltaTPos4 "Platform Safe Stop buffer paths. 

All signalgroups cover 50 points + 1 initial point. Each point has delta X, Y, time and heading. All signal groups are tied together with a trajectory id. 
All signalgroups include signals for E2E protection using profile 5 according to Autosar 4.2.2.

Signal group 4 includes:
* 6 PSS points, with overall sequence 21-26
 Delta time position 4";
CM_ SG_ 84 AdPrimPSSGroupSafe4DeltaTPos5 "Platform Safe Stop buffer paths. 

All signalgroups cover 50 points + 1 initial point. Each point has delta X, Y, time and heading. All signal groups are tied together with a trajectory id. 
All signalgroups include signals for E2E protection using profile 5 according to Autosar 4.2.2.

Signal group 4 includes:
* 6 PSS points, with overall sequence 21-26
 Delta time position 5";
CM_ SG_ 84 AdPrimPSSGroupSafe4DeltaTPos6 "Platform Safe Stop buffer paths. 

All signalgroups cover 50 points + 1 initial point. Each point has delta X, Y, time and heading. All signal groups are tied together with a trajectory id. 
All signalgroups include signals for E2E protection using profile 5 according to Autosar 4.2.2.

Signal group 4 includes:
* 6 PSS points, with overall sequence 21-26
 Delta time position 6";
CM_ SG_ 84 AdPrimPSSGroupSafe4DeltaXPos1 "Platform Safe Stop buffer paths. 

All signalgroups cover 50 points + 1 initial point. Each point has delta X, Y, time and heading. All signal groups are tied together with a trajectory id. 
All signalgroups include signals for E2E protection using profile 5 according to Autosar 4.2.2.

Signal group 4 includes:
* 6 PSS points, with overall sequence 21-26
 Delta X position 1";
CM_ SG_ 84 AdPrimPSSGroupSafe4DeltaXPos2 "Platform Safe Stop buffer paths. 

All signalgroups cover 50 points + 1 initial point. Each point has delta X, Y, time and heading. All signal groups are tied together with a trajectory id. 
All signalgroups include signals for E2E protection using profile 5 according to Autosar 4.2.2.

Signal group 4 includes:
* 6 PSS points, with overall sequence 21-26
 Delta X position 2";
CM_ SG_ 84 AdPrimPSSGroupSafe4DeltaXPos3 "Platform Safe Stop buffer paths. 

All signalgroups cover 50 points + 1 initial point. Each point has delta X, Y, time and heading. All signal groups are tied together with a trajectory id. 
All signalgroups include signals for E2E protection using profile 5 according to Autosar 4.2.2.

Signal group 4 includes:
* 6 PSS points, with overall sequence 21-26
 Delta X position 3";
CM_ SG_ 84 AdPrimPSSGroupSafe4DeltaXPos4 "Platform Safe Stop buffer paths. 

All signalgroups cover 50 points + 1 initial point. Each point has delta X, Y, time and heading. All signal groups are tied together with a trajectory id. 
All signalgroups include signals for E2E protection using profile 5 according to Autosar 4.2.2.

Signal group 4 includes:
* 6 PSS points, with overall sequence 21-26
 Delta X position 4";
CM_ SG_ 84 AdPrimPSSGroupSafe4DeltaXPos5 "Platform Safe Stop buffer paths. 

All signalgroups cover 50 points + 1 initial point. Each point has delta X, Y, time and heading. All signal groups are tied together with a trajectory id. 
All signalgroups include signals for E2E protection using profile 5 according to Autosar 4.2.2.

Signal group 4 includes:
* 6 PSS points, with overall sequence 21-26
 Delta X position 5";
CM_ SG_ 84 AdPrimPSSGroupSafe4DeltaXPos6 "Platform Safe Stop buffer paths. 

All signalgroups cover 50 points + 1 initial point. Each point has delta X, Y, time and heading. All signal groups are tied together with a trajectory id. 
All signalgroups include signals for E2E protection using profile 5 according to Autosar 4.2.2.

Signal group 4 includes:
* 6 PSS points, with overall sequence 21-26
 Delta X position 6";
CM_ SG_ 84 AdPrimPSSGroupSafe4DeltaYPos1 "Platform Safe Stop buffer paths. 

All signalgroups cover 50 points + 1 initial point. Each point has delta X, Y, time and heading. All signal groups are tied together with a trajectory id. 
All signalgroups include signals for E2E protection using profile 5 according to Autosar 4.2.2.

Signal group 4 includes:
* 6 PSS points, with overall sequence 21-26
 Delta Y position 1";
CM_ SG_ 84 AdPrimPSSGroupSafe4DeltaYPos2 "Platform Safe Stop buffer paths. 

All signalgroups cover 50 points + 1 initial point. Each point has delta X, Y, time and heading. All signal groups are tied together with a trajectory id. 
All signalgroups include signals for E2E protection using profile 5 according to Autosar 4.2.2.

Signal group 4 includes:
* 6 PSS points, with overall sequence 21-26
 Delta Y position 2";
CM_ SG_ 84 AdPrimPSSGroupSafe4DeltaYPos3 "Platform Safe Stop buffer paths. 

All signalgroups cover 50 points + 1 initial point. Each point has delta X, Y, time and heading. All signal groups are tied together with a trajectory id. 
All signalgroups include signals for E2E protection using profile 5 according to Autosar 4.2.2.

Signal group 4 includes:
* 6 PSS points, with overall sequence 21-26
 Delta Y position 3";
CM_ SG_ 84 AdPrimPSSGroupSafe4DeltaYPos4 "Platform Safe Stop buffer paths. 

All signalgroups cover 50 points + 1 initial point. Each point has delta X, Y, time and heading. All signal groups are tied together with a trajectory id. 
All signalgroups include signals for E2E protection using profile 5 according to Autosar 4.2.2.

Signal group 4 includes:
* 6 PSS points, with overall sequence 21-26
 Delta Y position 4";
CM_ SG_ 84 AdPrimPSSGroupSafe4DeltaYPos5 "Platform Safe Stop buffer paths. 

All signalgroups cover 50 points + 1 initial point. Each point has delta X, Y, time and heading. All signal groups are tied together with a trajectory id. 
All signalgroups include signals for E2E protection using profile 5 according to Autosar 4.2.2.

Signal group 4 includes:
* 6 PSS points, with overall sequence 21-26
 Delta Y position 5";
CM_ SG_ 84 AdPrimPSSGroupSafe4DeltaYPos6 "Platform Safe Stop buffer paths. 

All signalgroups cover 50 points + 1 initial point. Each point has delta X, Y, time and heading. All signal groups are tied together with a trajectory id. 
All signalgroups include signals for E2E protection using profile 5 according to Autosar 4.2.2.

Signal group 4 includes:
* 6 PSS points, with overall sequence 21-26
 Delta Y position 6";
CM_ SG_ 84 AdPrimPSSGroupSafe4HeadingPos1 "Platform Safe Stop buffer paths. 

All signalgroups cover 50 points + 1 initial point. Each point has delta X, Y, time and heading. All signal groups are tied together with a trajectory id. 
All signalgroups include signals for E2E protection using profile 5 according to Autosar 4.2.2.

Signal group 4 includes:
* 6 PSS points, with overall sequence 21-26
 Heading position 1";
CM_ SG_ 84 AdPrimPSSGroupSafe4HeadingPos2 "Platform Safe Stop buffer paths. 

All signalgroups cover 50 points + 1 initial point. Each point has delta X, Y, time and heading. All signal groups are tied together with a trajectory id. 
All signalgroups include signals for E2E protection using profile 5 according to Autosar 4.2.2.

Signal group 4 includes:
* 6 PSS points, with overall sequence 21-26
 Heading position 2";
CM_ SG_ 84 AdPrimPSSGroupSafe4HeadingPos3 "Platform Safe Stop buffer paths. 

All signalgroups cover 50 points + 1 initial point. Each point has delta X, Y, time and heading. All signal groups are tied together with a trajectory id. 
All signalgroups include signals for E2E protection using profile 5 according to Autosar 4.2.2.

Signal group 4 includes:
* 6 PSS points, with overall sequence 21-26
 Heading position 3";
CM_ SG_ 84 AdPrimPSSGroupSafe4HeadingPos4 "Platform Safe Stop buffer paths. 

All signalgroups cover 50 points + 1 initial point. Each point has delta X, Y, time and heading. All signal groups are tied together with a trajectory id. 
All signalgroups include signals for E2E protection using profile 5 according to Autosar 4.2.2.

Signal group 4 includes:
* 6 PSS points, with overall sequence 21-26
 Heading position 4";
CM_ SG_ 84 AdPrimPSSGroupSafe4HeadingPos5 "Platform Safe Stop buffer paths. 

All signalgroups cover 50 points + 1 initial point. Each point has delta X, Y, time and heading. All signal groups are tied together with a trajectory id. 
All signalgroups include signals for E2E protection using profile 5 according to Autosar 4.2.2.

Signal group 4 includes:
* 6 PSS points, with overall sequence 21-26
 Heading position 5";
CM_ SG_ 84 AdPrimPSSGroupSafe4HeadingPos6 "Platform Safe Stop buffer paths. 

All signalgroups cover 50 points + 1 initial point. Each point has delta X, Y, time and heading. All signal groups are tied together with a trajectory id. 
All signalgroups include signals for E2E protection using profile 5 according to Autosar 4.2.2.

Signal group 4 includes:
* 6 PSS points, with overall sequence 21-26
 Heading position 6";
CM_ SG_ 84 AdPrimPSSGroupSafe4TrajectID "Platform Safe Stop buffer paths. 

All signalgroups cover 50 points + 1 initial point. Each point has delta X, Y, time and heading. All signal groups are tied together with a trajectory id. 
All signalgroups include signals for E2E protection using profile 5 according to Autosar 4.2.2.

Signal group 4 includes:
* 6 PSS points, with overall sequence 21-26
 Trajectory ID";
CM_ SG_ 88 AdPrimPSSGroupSafe5Chks "Platform Safe Stop buffer paths. 

All signalgroups cover 50 points + 1 initial point. Each point has delta X, Y, time and heading. All signal groups are tied together with a trajectory id. 
All signalgroups include signals for E2E protection using profile 5 according to Autosar 4.2.2.

Signal group 5 includes:
* 6 PSS points, with overall sequence 27-32
 E2E checksum, profile 5";
CM_ SG_ 88 AdPrimPSSGroupSafe5Cntr "Platform Safe Stop buffer paths. 

All signalgroups cover 50 points + 1 initial point. Each point has delta X, Y, time and heading. All signal groups are tied together with a trajectory id. 
All signalgroups include signals for E2E protection using profile 5 according to Autosar 4.2.2.

Signal group 5 includes:
* 6 PSS points, with overall sequence 27-32
 E2E counter, profile 5";
CM_ SG_ 88 AdPrimPSSGroupSafe5DataID "Platform Safe Stop buffer paths. 

All signalgroups cover 50 points + 1 initial point. Each point has delta X, Y, time and heading. All signal groups are tied together with a trajectory id. 
All signalgroups include signals for E2E protection using profile 5 according to Autosar 4.2.2.

Signal group 5 includes:
* 6 PSS points, with overall sequence 27-32
 E2E Data ID, profile 5";
CM_ SG_ 88 AdPrimPSSGroupSafe5DeltaTPos1 "Platform Safe Stop buffer paths. 

All signalgroups cover 50 points + 1 initial point. Each point has delta X, Y, time and heading. All signal groups are tied together with a trajectory id. 
All signalgroups include signals for E2E protection using profile 5 according to Autosar 4.2.2.

Signal group 5 includes:
* 6 PSS points, with overall sequence 27-32
 Delta time position 1";
CM_ SG_ 88 AdPrimPSSGroupSafe5DeltaTPos2 "Platform Safe Stop buffer paths. 

All signalgroups cover 50 points + 1 initial point. Each point has delta X, Y, time and heading. All signal groups are tied together with a trajectory id. 
All signalgroups include signals for E2E protection using profile 5 according to Autosar 4.2.2.

Signal group 5 includes:
* 6 PSS points, with overall sequence 27-32
 Delta time position 2";
CM_ SG_ 88 AdPrimPSSGroupSafe5DeltaTPos3 "Platform Safe Stop buffer paths. 

All signalgroups cover 50 points + 1 initial point. Each point has delta X, Y, time and heading. All signal groups are tied together with a trajectory id. 
All signalgroups include signals for E2E protection using profile 5 according to Autosar 4.2.2.

Signal group 5 includes:
* 6 PSS points, with overall sequence 27-32
 Delta time position 3";
CM_ SG_ 88 AdPrimPSSGroupSafe5DeltaTPos4 "Platform Safe Stop buffer paths. 

All signalgroups cover 50 points + 1 initial point. Each point has delta X, Y, time and heading. All signal groups are tied together with a trajectory id. 
All signalgroups include signals for E2E protection using profile 5 according to Autosar 4.2.2.

Signal group 5 includes:
* 6 PSS points, with overall sequence 27-32
 Delta time position 4";
CM_ SG_ 88 AdPrimPSSGroupSafe5DeltaTPos5 "Platform Safe Stop buffer paths. 

All signalgroups cover 50 points + 1 initial point. Each point has delta X, Y, time and heading. All signal groups are tied together with a trajectory id. 
All signalgroups include signals for E2E protection using profile 5 according to Autosar 4.2.2.

Signal group 5 includes:
* 6 PSS points, with overall sequence 27-32
 Delta time position 5";
CM_ SG_ 88 AdPrimPSSGroupSafe5DeltaTPos6 "Platform Safe Stop buffer paths. 

All signalgroups cover 50 points + 1 initial point. Each point has delta X, Y, time and heading. All signal groups are tied together with a trajectory id. 
All signalgroups include signals for E2E protection using profile 5 according to Autosar 4.2.2.

Signal group 5 includes:
* 6 PSS points, with overall sequence 27-32
 Delta time position 6";
CM_ SG_ 88 AdPrimPSSGroupSafe5DeltaXPos1 "Platform Safe Stop buffer paths. 

All signalgroups cover 50 points + 1 initial point. Each point has delta X, Y, time and heading. All signal groups are tied together with a trajectory id. 
All signalgroups include signals for E2E protection using profile 5 according to Autosar 4.2.2.

Signal group 5 includes:
* 6 PSS points, with overall sequence 27-32
 Delta X position 1";
CM_ SG_ 88 AdPrimPSSGroupSafe5DeltaXPos2 "Platform Safe Stop buffer paths. 

All signalgroups cover 50 points + 1 initial point. Each point has delta X, Y, time and heading. All signal groups are tied together with a trajectory id. 
All signalgroups include signals for E2E protection using profile 5 according to Autosar 4.2.2.

Signal group 5 includes:
* 6 PSS points, with overall sequence 27-32
 Delta X position 2";
CM_ SG_ 88 AdPrimPSSGroupSafe5DeltaXPos3 "Platform Safe Stop buffer paths. 

All signalgroups cover 50 points + 1 initial point. Each point has delta X, Y, time and heading. All signal groups are tied together with a trajectory id. 
All signalgroups include signals for E2E protection using profile 5 according to Autosar 4.2.2.

Signal group 5 includes:
* 6 PSS points, with overall sequence 27-32
 Delta X position 3";
CM_ SG_ 88 AdPrimPSSGroupSafe5DeltaXPos4 "Platform Safe Stop buffer paths. 

All signalgroups cover 50 points + 1 initial point. Each point has delta X, Y, time and heading. All signal groups are tied together with a trajectory id. 
All signalgroups include signals for E2E protection using profile 5 according to Autosar 4.2.2.

Signal group 5 includes:
* 6 PSS points, with overall sequence 27-32
 Delta X position 4";
CM_ SG_ 88 AdPrimPSSGroupSafe5DeltaXPos5 "Platform Safe Stop buffer paths. 

All signalgroups cover 50 points + 1 initial point. Each point has delta X, Y, time and heading. All signal groups are tied together with a trajectory id. 
All signalgroups include signals for E2E protection using profile 5 according to Autosar 4.2.2.

Signal group 5 includes:
* 6 PSS points, with overall sequence 27-32
 Delta X position 5";
CM_ SG_ 88 AdPrimPSSGroupSafe5DeltaXPos6 "Platform Safe Stop buffer paths. 

All signalgroups cover 50 points + 1 initial point. Each point has delta X, Y, time and heading. All signal groups are tied together with a trajectory id. 
All signalgroups include signals for E2E protection using profile 5 according to Autosar 4.2.2.

Signal group 5 includes:
* 6 PSS points, with overall sequence 27-32
 Delta X position 6";
CM_ SG_ 88 AdPrimPSSGroupSafe5DeltaYPos1 "Platform Safe Stop buffer paths. 

All signalgroups cover 50 points + 1 initial point. Each point has delta X, Y, time and heading. All signal groups are tied together with a trajectory id. 
All signalgroups include signals for E2E protection using profile 5 according to Autosar 4.2.2.

Signal group 5 includes:
* 6 PSS points, with overall sequence 27-32
 Delta Y position 1";
CM_ SG_ 88 AdPrimPSSGroupSafe5DeltaYPos2 "Platform Safe Stop buffer paths. 

All signalgroups cover 50 points + 1 initial point. Each point has delta X, Y, time and heading. All signal groups are tied together with a trajectory id. 
All signalgroups include signals for E2E protection using profile 5 according to Autosar 4.2.2.

Signal group 5 includes:
* 6 PSS points, with overall sequence 27-32
 Delta Y position 2";
CM_ SG_ 88 AdPrimPSSGroupSafe5DeltaYPos3 "Platform Safe Stop buffer paths. 

All signalgroups cover 50 points + 1 initial point. Each point has delta X, Y, time and heading. All signal groups are tied together with a trajectory id. 
All signalgroups include signals for E2E protection using profile 5 according to Autosar 4.2.2.

Signal group 5 includes:
* 6 PSS points, with overall sequence 27-32
 Delta Y position 3";
CM_ SG_ 88 AdPrimPSSGroupSafe5DeltaYPos4 "Platform Safe Stop buffer paths. 

All signalgroups cover 50 points + 1 initial point. Each point has delta X, Y, time and heading. All signal groups are tied together with a trajectory id. 
All signalgroups include signals for E2E protection using profile 5 according to Autosar 4.2.2.

Signal group 5 includes:
* 6 PSS points, with overall sequence 27-32
 Delta Y position 4";
CM_ SG_ 88 AdPrimPSSGroupSafe5DeltaYPos5 "Platform Safe Stop buffer paths. 

All signalgroups cover 50 points + 1 initial point. Each point has delta X, Y, time and heading. All signal groups are tied together with a trajectory id. 
All signalgroups include signals for E2E protection using profile 5 according to Autosar 4.2.2.

Signal group 5 includes:
* 6 PSS points, with overall sequence 27-32
 Delta Y position 5";
CM_ SG_ 88 AdPrimPSSGroupSafe5DeltaYPos6 "Platform Safe Stop buffer paths. 

All signalgroups cover 50 points + 1 initial point. Each point has delta X, Y, time and heading. All signal groups are tied together with a trajectory id. 
All signalgroups include signals for E2E protection using profile 5 according to Autosar 4.2.2.

Signal group 5 includes:
* 6 PSS points, with overall sequence 27-32
 Delta Y position 6";
CM_ SG_ 88 AdPrimPSSGroupSafe5HeadingPos1 "Platform Safe Stop buffer paths. 

All signalgroups cover 50 points + 1 initial point. Each point has delta X, Y, time and heading. All signal groups are tied together with a trajectory id. 
All signalgroups include signals for E2E protection using profile 5 according to Autosar 4.2.2.

Signal group 5 includes:
* 6 PSS points, with overall sequence 27-32
 Heading position 1";
CM_ SG_ 88 AdPrimPSSGroupSafe5HeadingPos2 "Platform Safe Stop buffer paths. 

All signalgroups cover 50 points + 1 initial point. Each point has delta X, Y, time and heading. All signal groups are tied together with a trajectory id. 
All signalgroups include signals for E2E protection using profile 5 according to Autosar 4.2.2.

Signal group 5 includes:
* 6 PSS points, with overall sequence 27-32
 Heading position 2";
CM_ SG_ 88 AdPrimPSSGroupSafe5HeadingPos3 "Platform Safe Stop buffer paths. 

All signalgroups cover 50 points + 1 initial point. Each point has delta X, Y, time and heading. All signal groups are tied together with a trajectory id. 
All signalgroups include signals for E2E protection using profile 5 according to Autosar 4.2.2.

Signal group 5 includes:
* 6 PSS points, with overall sequence 27-32
 Heading position 3";
CM_ SG_ 88 AdPrimPSSGroupSafe5HeadingPos4 "Platform Safe Stop buffer paths. 

All signalgroups cover 50 points + 1 initial point. Each point has delta X, Y, time and heading. All signal groups are tied together with a trajectory id. 
All signalgroups include signals for E2E protection using profile 5 according to Autosar 4.2.2.

Signal group 5 includes:
* 6 PSS points, with overall sequence 27-32
 Heading position 4";
CM_ SG_ 88 AdPrimPSSGroupSafe5HeadingPos5 "Platform Safe Stop buffer paths. 

All signalgroups cover 50 points + 1 initial point. Each point has delta X, Y, time and heading. All signal groups are tied together with a trajectory id. 
All signalgroups include signals for E2E protection using profile 5 according to Autosar 4.2.2.

Signal group 5 includes:
* 6 PSS points, with overall sequence 27-32
 Heading position 5";
CM_ SG_ 88 AdPrimPSSGroupSafe5HeadingPos6 "Platform Safe Stop buffer paths. 

All signalgroups cover 50 points + 1 initial point. Each point has delta X, Y, time and heading. All signal groups are tied together with a trajectory id. 
All signalgroups include signals for E2E protection using profile 5 according to Autosar 4.2.2.

Signal group 5 includes:
* 6 PSS points, with overall sequence 27-32
 Heading position 6";
CM_ SG_ 88 AdPrimPSSGroupSafe5TrajectID "Platform Safe Stop buffer paths. 

All signalgroups cover 50 points + 1 initial point. Each point has delta X, Y, time and heading. All signal groups are tied together with a trajectory id. 
All signalgroups include signals for E2E protection using profile 5 according to Autosar 4.2.2.

Signal group 5 includes:
* 6 PSS points, with overall sequence 27-32
 Trajectory ID";
CM_ SG_ 98 AdPrimPSSGroupSafe6Chks "Platform Safe Stop buffer paths. 

All signalgroups cover 50 points + 1 initial point. Each point has delta X, Y, time and heading. All signal groups are tied together with a trajectory id. 
All signalgroups include signals for E2E protection using profile 5 according to Autosar 4.2.2.

Signal group 6 includes:
* 6 PSS points, with overall sequence 33-38

 E2E checksum, profile 5";
CM_ SG_ 98 AdPrimPSSGroupSafe6Cntr "Platform Safe Stop buffer paths. 

All signalgroups cover 50 points + 1 initial point. Each point has delta X, Y, time and heading. All signal groups are tied together with a trajectory id. 
All signalgroups include signals for E2E protection using profile 5 according to Autosar 4.2.2.

Signal group 6 includes:
* 6 PSS points, with overall sequence 33-38

 E2E counter, profile 5";
CM_ SG_ 98 AdPrimPSSGroupSafe6DataID "Platform Safe Stop buffer paths. 

All signalgroups cover 50 points + 1 initial point. Each point has delta X, Y, time and heading. All signal groups are tied together with a trajectory id. 
All signalgroups include signals for E2E protection using profile 5 according to Autosar 4.2.2.

Signal group 6 includes:
* 6 PSS points, with overall sequence 33-38

 E2E Data ID, profile 5";
CM_ SG_ 98 AdPrimPSSGroupSafe6DeltaTPos1 "Platform Safe Stop buffer paths. 

All signalgroups cover 50 points + 1 initial point. Each point has delta X, Y, time and heading. All signal groups are tied together with a trajectory id. 
All signalgroups include signals for E2E protection using profile 5 according to Autosar 4.2.2.

Signal group 6 includes:
* 6 PSS points, with overall sequence 33-38

 Delta time position 1";
CM_ SG_ 98 AdPrimPSSGroupSafe6DeltaTPos2 "Platform Safe Stop buffer paths. 

All signalgroups cover 50 points + 1 initial point. Each point has delta X, Y, time and heading. All signal groups are tied together with a trajectory id. 
All signalgroups include signals for E2E protection using profile 5 according to Autosar 4.2.2.

Signal group 6 includes:
* 6 PSS points, with overall sequence 33-38

 Delta time position 2";
CM_ SG_ 98 AdPrimPSSGroupSafe6DeltaTPos3 "Platform Safe Stop buffer paths. 

All signalgroups cover 50 points + 1 initial point. Each point has delta X, Y, time and heading. All signal groups are tied together with a trajectory id. 
All signalgroups include signals for E2E protection using profile 5 according to Autosar 4.2.2.

Signal group 6 includes:
* 6 PSS points, with overall sequence 33-38

 Delta time position 3";
CM_ SG_ 98 AdPrimPSSGroupSafe6DeltaTPos4 "Platform Safe Stop buffer paths. 

All signalgroups cover 50 points + 1 initial point. Each point has delta X, Y, time and heading. All signal groups are tied together with a trajectory id. 
All signalgroups include signals for E2E protection using profile 5 according to Autosar 4.2.2.

Signal group 6 includes:
* 6 PSS points, with overall sequence 33-38

 Delta time position 4";
CM_ SG_ 98 AdPrimPSSGroupSafe6DeltaTPos5 "Platform Safe Stop buffer paths. 

All signalgroups cover 50 points + 1 initial point. Each point has delta X, Y, time and heading. All signal groups are tied together with a trajectory id. 
All signalgroups include signals for E2E protection using profile 5 according to Autosar 4.2.2.

Signal group 6 includes:
* 6 PSS points, with overall sequence 33-38

 Delta time position 5";
CM_ SG_ 98 AdPrimPSSGroupSafe6DeltaTPos6 "Platform Safe Stop buffer paths. 

All signalgroups cover 50 points + 1 initial point. Each point has delta X, Y, time and heading. All signal groups are tied together with a trajectory id. 
All signalgroups include signals for E2E protection using profile 5 according to Autosar 4.2.2.

Signal group 6 includes:
* 6 PSS points, with overall sequence 33-38

 Delta time position 6";
CM_ SG_ 98 AdPrimPSSGroupSafe6DeltaXPos1 "Platform Safe Stop buffer paths. 

All signalgroups cover 50 points + 1 initial point. Each point has delta X, Y, time and heading. All signal groups are tied together with a trajectory id. 
All signalgroups include signals for E2E protection using profile 5 according to Autosar 4.2.2.

Signal group 6 includes:
* 6 PSS points, with overall sequence 33-38

 Delta X position 1";
CM_ SG_ 98 AdPrimPSSGroupSafe6DeltaXPos2 "Platform Safe Stop buffer paths. 

All signalgroups cover 50 points + 1 initial point. Each point has delta X, Y, time and heading. All signal groups are tied together with a trajectory id. 
All signalgroups include signals for E2E protection using profile 5 according to Autosar 4.2.2.

Signal group 6 includes:
* 6 PSS points, with overall sequence 33-38

 Delta X position 2";
CM_ SG_ 98 AdPrimPSSGroupSafe6DeltaXPos3 "Platform Safe Stop buffer paths. 

All signalgroups cover 50 points + 1 initial point. Each point has delta X, Y, time and heading. All signal groups are tied together with a trajectory id. 
All signalgroups include signals for E2E protection using profile 5 according to Autosar 4.2.2.

Signal group 6 includes:
* 6 PSS points, with overall sequence 33-38

 Delta X position 3";
CM_ SG_ 98 AdPrimPSSGroupSafe6DeltaXPos4 "Platform Safe Stop buffer paths. 

All signalgroups cover 50 points + 1 initial point. Each point has delta X, Y, time and heading. All signal groups are tied together with a trajectory id. 
All signalgroups include signals for E2E protection using profile 5 according to Autosar 4.2.2.

Signal group 6 includes:
* 6 PSS points, with overall sequence 33-38

 Delta X position 4";
CM_ SG_ 98 AdPrimPSSGroupSafe6DeltaXPos5 "Platform Safe Stop buffer paths. 

All signalgroups cover 50 points + 1 initial point. Each point has delta X, Y, time and heading. All signal groups are tied together with a trajectory id. 
All signalgroups include signals for E2E protection using profile 5 according to Autosar 4.2.2.

Signal group 6 includes:
* 6 PSS points, with overall sequence 33-38

 Delta X position 5";
CM_ SG_ 98 AdPrimPSSGroupSafe6DeltaXPos6 "Platform Safe Stop buffer paths. 

All signalgroups cover 50 points + 1 initial point. Each point has delta X, Y, time and heading. All signal groups are tied together with a trajectory id. 
All signalgroups include signals for E2E protection using profile 5 according to Autosar 4.2.2.

Signal group 6 includes:
* 6 PSS points, with overall sequence 33-38

 Delta X position 6";
CM_ SG_ 98 AdPrimPSSGroupSafe6DeltaYPos1 "Platform Safe Stop buffer paths. 

All signalgroups cover 50 points + 1 initial point. Each point has delta X, Y, time and heading. All signal groups are tied together with a trajectory id. 
All signalgroups include signals for E2E protection using profile 5 according to Autosar 4.2.2.

Signal group 6 includes:
* 6 PSS points, with overall sequence 33-38

 Delta Y position 1";
CM_ SG_ 98 AdPrimPSSGroupSafe6DeltaYPos2 "Platform Safe Stop buffer paths. 

All signalgroups cover 50 points + 1 initial point. Each point has delta X, Y, time and heading. All signal groups are tied together with a trajectory id. 
All signalgroups include signals for E2E protection using profile 5 according to Autosar 4.2.2.

Signal group 6 includes:
* 6 PSS points, with overall sequence 33-38

 Delta Y position 2";
CM_ SG_ 98 AdPrimPSSGroupSafe6DeltaYPos3 "Platform Safe Stop buffer paths. 

All signalgroups cover 50 points + 1 initial point. Each point has delta X, Y, time and heading. All signal groups are tied together with a trajectory id. 
All signalgroups include signals for E2E protection using profile 5 according to Autosar 4.2.2.

Signal group 6 includes:
* 6 PSS points, with overall sequence 33-38

 Delta Y position 3";
CM_ SG_ 98 AdPrimPSSGroupSafe6DeltaYPos4 "Platform Safe Stop buffer paths. 

All signalgroups cover 50 points + 1 initial point. Each point has delta X, Y, time and heading. All signal groups are tied together with a trajectory id. 
All signalgroups include signals for E2E protection using profile 5 according to Autosar 4.2.2.

Signal group 6 includes:
* 6 PSS points, with overall sequence 33-38

 Delta Y position 4";
CM_ SG_ 98 AdPrimPSSGroupSafe6DeltaYPos5 "Platform Safe Stop buffer paths. 

All signalgroups cover 50 points + 1 initial point. Each point has delta X, Y, time and heading. All signal groups are tied together with a trajectory id. 
All signalgroups include signals for E2E protection using profile 5 according to Autosar 4.2.2.

Signal group 6 includes:
* 6 PSS points, with overall sequence 33-38

 Delta Y position 5";
CM_ SG_ 98 AdPrimPSSGroupSafe6DeltaYPos6 "Platform Safe Stop buffer paths. 

All signalgroups cover 50 points + 1 initial point. Each point has delta X, Y, time and heading. All signal groups are tied together with a trajectory id. 
All signalgroups include signals for E2E protection using profile 5 according to Autosar 4.2.2.

Signal group 6 includes:
* 6 PSS points, with overall sequence 33-38

 Delta Y position 6";
CM_ SG_ 98 AdPrimPSSGroupSafe6HeadingPos1 "Platform Safe Stop buffer paths. 

All signalgroups cover 50 points + 1 initial point. Each point has delta X, Y, time and heading. All signal groups are tied together with a trajectory id. 
All signalgroups include signals for E2E protection using profile 5 according to Autosar 4.2.2.

Signal group 6 includes:
* 6 PSS points, with overall sequence 33-38

 Heading position 1";
CM_ SG_ 98 AdPrimPSSGroupSafe6HeadingPos2 "Platform Safe Stop buffer paths. 

All signalgroups cover 50 points + 1 initial point. Each point has delta X, Y, time and heading. All signal groups are tied together with a trajectory id. 
All signalgroups include signals for E2E protection using profile 5 according to Autosar 4.2.2.

Signal group 6 includes:
* 6 PSS points, with overall sequence 33-38

 Heading position 2";
CM_ SG_ 98 AdPrimPSSGroupSafe6HeadingPos3 "Platform Safe Stop buffer paths. 

All signalgroups cover 50 points + 1 initial point. Each point has delta X, Y, time and heading. All signal groups are tied together with a trajectory id. 
All signalgroups include signals for E2E protection using profile 5 according to Autosar 4.2.2.

Signal group 6 includes:
* 6 PSS points, with overall sequence 33-38

 Heading position 3";
CM_ SG_ 98 AdPrimPSSGroupSafe6HeadingPos4 "Platform Safe Stop buffer paths. 

All signalgroups cover 50 points + 1 initial point. Each point has delta X, Y, time and heading. All signal groups are tied together with a trajectory id. 
All signalgroups include signals for E2E protection using profile 5 according to Autosar 4.2.2.

Signal group 6 includes:
* 6 PSS points, with overall sequence 33-38

 Heading position 4";
CM_ SG_ 98 AdPrimPSSGroupSafe6HeadingPos5 "Platform Safe Stop buffer paths. 

All signalgroups cover 50 points + 1 initial point. Each point has delta X, Y, time and heading. All signal groups are tied together with a trajectory id. 
All signalgroups include signals for E2E protection using profile 5 according to Autosar 4.2.2.

Signal group 6 includes:
* 6 PSS points, with overall sequence 33-38

 Heading position 5";
CM_ SG_ 98 AdPrimPSSGroupSafe6HeadingPos6 "Platform Safe Stop buffer paths. 

All signalgroups cover 50 points + 1 initial point. Each point has delta X, Y, time and heading. All signal groups are tied together with a trajectory id. 
All signalgroups include signals for E2E protection using profile 5 according to Autosar 4.2.2.

Signal group 6 includes:
* 6 PSS points, with overall sequence 33-38

 Heading position 6";
CM_ SG_ 98 AdPrimPSSGroupSafe6TrajectID "Platform Safe Stop buffer paths. 

All signalgroups cover 50 points + 1 initial point. Each point has delta X, Y, time and heading. All signal groups are tied together with a trajectory id. 
All signalgroups include signals for E2E protection using profile 5 according to Autosar 4.2.2.

Signal group 6 includes:
* 6 PSS points, with overall sequence 33-38

 Trajectory ID";
CM_ SG_ 100 AdPrimPSSGroupSafe7Chks "Platform Safe Stop buffer paths. 

All signalgroups cover 50 points + 1 initial point. Each point has delta X, Y, time and heading. All signal groups are tied together with a trajectory id. 
All signalgroups include signals for E2E protection using profile 5 according to Autosar 4.2.2.

Signal group 7 includes:
* 6 PSS points, with overall sequence 39-44

 E2E checksum, profile 5";
CM_ SG_ 100 AdPrimPSSGroupSafe7Cntr "Platform Safe Stop buffer paths. 

All signalgroups cover 50 points + 1 initial point. Each point has delta X, Y, time and heading. All signal groups are tied together with a trajectory id. 
All signalgroups include signals for E2E protection using profile 5 according to Autosar 4.2.2.

Signal group 7 includes:
* 6 PSS points, with overall sequence 39-44

 E2E counter, profile 5";
CM_ SG_ 100 AdPrimPSSGroupSafe7DataID "Platform Safe Stop buffer paths. 

All signalgroups cover 50 points + 1 initial point. Each point has delta X, Y, time and heading. All signal groups are tied together with a trajectory id. 
All signalgroups include signals for E2E protection using profile 5 according to Autosar 4.2.2.

Signal group 7 includes:
* 6 PSS points, with overall sequence 39-44

 E2E Data ID, profile 5";
CM_ SG_ 100 AdPrimPSSGroupSafe7DeltaTPos1 "Platform Safe Stop buffer paths. 

All signalgroups cover 50 points + 1 initial point. Each point has delta X, Y, time and heading. All signal groups are tied together with a trajectory id. 
All signalgroups include signals for E2E protection using profile 5 according to Autosar 4.2.2.

Signal group 7 includes:
* 6 PSS points, with overall sequence 39-44

 Delta time position 1";
CM_ SG_ 100 AdPrimPSSGroupSafe7DeltaTPos2 "Platform Safe Stop buffer paths. 

All signalgroups cover 50 points + 1 initial point. Each point has delta X, Y, time and heading. All signal groups are tied together with a trajectory id. 
All signalgroups include signals for E2E protection using profile 5 according to Autosar 4.2.2.

Signal group 7 includes:
* 6 PSS points, with overall sequence 39-44

 Delta time position 2";
CM_ SG_ 100 AdPrimPSSGroupSafe7DeltaTPos3 "Platform Safe Stop buffer paths. 

All signalgroups cover 50 points + 1 initial point. Each point has delta X, Y, time and heading. All signal groups are tied together with a trajectory id. 
All signalgroups include signals for E2E protection using profile 5 according to Autosar 4.2.2.

Signal group 7 includes:
* 6 PSS points, with overall sequence 39-44

 Delta time position 3";
CM_ SG_ 100 AdPrimPSSGroupSafe7DeltaTPos4 "Platform Safe Stop buffer paths. 

All signalgroups cover 50 points + 1 initial point. Each point has delta X, Y, time and heading. All signal groups are tied together with a trajectory id. 
All signalgroups include signals for E2E protection using profile 5 according to Autosar 4.2.2.

Signal group 7 includes:
* 6 PSS points, with overall sequence 39-44

 Delta time position 4";
CM_ SG_ 100 AdPrimPSSGroupSafe7DeltaTPos5 "Platform Safe Stop buffer paths. 

All signalgroups cover 50 points + 1 initial point. Each point has delta X, Y, time and heading. All signal groups are tied together with a trajectory id. 
All signalgroups include signals for E2E protection using profile 5 according to Autosar 4.2.2.

Signal group 7 includes:
* 6 PSS points, with overall sequence 39-44

 Delta time position 5";
CM_ SG_ 100 AdPrimPSSGroupSafe7DeltaTPos6 "Platform Safe Stop buffer paths. 

All signalgroups cover 50 points + 1 initial point. Each point has delta X, Y, time and heading. All signal groups are tied together with a trajectory id. 
All signalgroups include signals for E2E protection using profile 5 according to Autosar 4.2.2.

Signal group 7 includes:
* 6 PSS points, with overall sequence 39-44

 Delta time position 6";
CM_ SG_ 100 AdPrimPSSGroupSafe7DeltaXPos1 "Platform Safe Stop buffer paths. 

All signalgroups cover 50 points + 1 initial point. Each point has delta X, Y, time and heading. All signal groups are tied together with a trajectory id. 
All signalgroups include signals for E2E protection using profile 5 according to Autosar 4.2.2.

Signal group 7 includes:
* 6 PSS points, with overall sequence 39-44

 Delta X position 1";
CM_ SG_ 100 AdPrimPSSGroupSafe7DeltaXPos2 "Platform Safe Stop buffer paths. 

All signalgroups cover 50 points + 1 initial point. Each point has delta X, Y, time and heading. All signal groups are tied together with a trajectory id. 
All signalgroups include signals for E2E protection using profile 5 according to Autosar 4.2.2.

Signal group 7 includes:
* 6 PSS points, with overall sequence 39-44

 Delta X position 2";
CM_ SG_ 100 AdPrimPSSGroupSafe7DeltaXPos3 "Platform Safe Stop buffer paths. 

All signalgroups cover 50 points + 1 initial point. Each point has delta X, Y, time and heading. All signal groups are tied together with a trajectory id. 
All signalgroups include signals for E2E protection using profile 5 according to Autosar 4.2.2.

Signal group 7 includes:
* 6 PSS points, with overall sequence 39-44

 Delta X position 3";
CM_ SG_ 100 AdPrimPSSGroupSafe7DeltaXPos4 "Platform Safe Stop buffer paths. 

All signalgroups cover 50 points + 1 initial point. Each point has delta X, Y, time and heading. All signal groups are tied together with a trajectory id. 
All signalgroups include signals for E2E protection using profile 5 according to Autosar 4.2.2.

Signal group 7 includes:
* 6 PSS points, with overall sequence 39-44

 Delta X position 4";
CM_ SG_ 100 AdPrimPSSGroupSafe7DeltaXPos5 "Platform Safe Stop buffer paths. 

All signalgroups cover 50 points + 1 initial point. Each point has delta X, Y, time and heading. All signal groups are tied together with a trajectory id. 
All signalgroups include signals for E2E protection using profile 5 according to Autosar 4.2.2.

Signal group 7 includes:
* 6 PSS points, with overall sequence 39-44

 Delta X position 5";
CM_ SG_ 100 AdPrimPSSGroupSafe7DeltaXPos6 "Platform Safe Stop buffer paths. 

All signalgroups cover 50 points + 1 initial point. Each point has delta X, Y, time and heading. All signal groups are tied together with a trajectory id. 
All signalgroups include signals for E2E protection using profile 5 according to Autosar 4.2.2.

Signal group 7 includes:
* 6 PSS points, with overall sequence 39-44

 Delta X position 6";
CM_ SG_ 100 AdPrimPSSGroupSafe7DeltaYPos1 "Platform Safe Stop buffer paths. 

All signalgroups cover 50 points + 1 initial point. Each point has delta X, Y, time and heading. All signal groups are tied together with a trajectory id. 
All signalgroups include signals for E2E protection using profile 5 according to Autosar 4.2.2.

Signal group 7 includes:
* 6 PSS points, with overall sequence 39-44

 Delta Y position 1";
CM_ SG_ 100 AdPrimPSSGroupSafe7DeltaYPos2 "Platform Safe Stop buffer paths. 

All signalgroups cover 50 points + 1 initial point. Each point has delta X, Y, time and heading. All signal groups are tied together with a trajectory id. 
All signalgroups include signals for E2E protection using profile 5 according to Autosar 4.2.2.

Signal group 7 includes:
* 6 PSS points, with overall sequence 39-44

 Delta Y position 2";
CM_ SG_ 100 AdPrimPSSGroupSafe7DeltaYPos3 "Platform Safe Stop buffer paths. 

All signalgroups cover 50 points + 1 initial point. Each point has delta X, Y, time and heading. All signal groups are tied together with a trajectory id. 
All signalgroups include signals for E2E protection using profile 5 according to Autosar 4.2.2.

Signal group 7 includes:
* 6 PSS points, with overall sequence 39-44

 Delta Y position 3";
CM_ SG_ 100 AdPrimPSSGroupSafe7DeltaYPos4 "Platform Safe Stop buffer paths. 

All signalgroups cover 50 points + 1 initial point. Each point has delta X, Y, time and heading. All signal groups are tied together with a trajectory id. 
All signalgroups include signals for E2E protection using profile 5 according to Autosar 4.2.2.

Signal group 7 includes:
* 6 PSS points, with overall sequence 39-44

 Delta Y position 4";
CM_ SG_ 100 AdPrimPSSGroupSafe7DeltaYPos5 "Platform Safe Stop buffer paths. 

All signalgroups cover 50 points + 1 initial point. Each point has delta X, Y, time and heading. All signal groups are tied together with a trajectory id. 
All signalgroups include signals for E2E protection using profile 5 according to Autosar 4.2.2.

Signal group 7 includes:
* 6 PSS points, with overall sequence 39-44

 Delta Y position 5";
CM_ SG_ 100 AdPrimPSSGroupSafe7DeltaYPos6 "Platform Safe Stop buffer paths. 

All signalgroups cover 50 points + 1 initial point. Each point has delta X, Y, time and heading. All signal groups are tied together with a trajectory id. 
All signalgroups include signals for E2E protection using profile 5 according to Autosar 4.2.2.

Signal group 7 includes:
* 6 PSS points, with overall sequence 39-44

 Delta Y position 6";
CM_ SG_ 100 AdPrimPSSGroupSafe7HeadingPos1 "Platform Safe Stop buffer paths. 

All signalgroups cover 50 points + 1 initial point. Each point has delta X, Y, time and heading. All signal groups are tied together with a trajectory id. 
All signalgroups include signals for E2E protection using profile 5 according to Autosar 4.2.2.

Signal group 7 includes:
* 6 PSS points, with overall sequence 39-44

 Heading position 1";
CM_ SG_ 100 AdPrimPSSGroupSafe7HeadingPos2 "Platform Safe Stop buffer paths. 

All signalgroups cover 50 points + 1 initial point. Each point has delta X, Y, time and heading. All signal groups are tied together with a trajectory id. 
All signalgroups include signals for E2E protection using profile 5 according to Autosar 4.2.2.

Signal group 7 includes:
* 6 PSS points, with overall sequence 39-44

 Heading position 2";
CM_ SG_ 100 AdPrimPSSGroupSafe7HeadingPos3 "Platform Safe Stop buffer paths. 

All signalgroups cover 50 points + 1 initial point. Each point has delta X, Y, time and heading. All signal groups are tied together with a trajectory id. 
All signalgroups include signals for E2E protection using profile 5 according to Autosar 4.2.2.

Signal group 7 includes:
* 6 PSS points, with overall sequence 39-44

 Heading position 3";
CM_ SG_ 100 AdPrimPSSGroupSafe7HeadingPos4 "Platform Safe Stop buffer paths. 

All signalgroups cover 50 points + 1 initial point. Each point has delta X, Y, time and heading. All signal groups are tied together with a trajectory id. 
All signalgroups include signals for E2E protection using profile 5 according to Autosar 4.2.2.

Signal group 7 includes:
* 6 PSS points, with overall sequence 39-44

 Heading position 4";
CM_ SG_ 100 AdPrimPSSGroupSafe7HeadingPos5 "Platform Safe Stop buffer paths. 

All signalgroups cover 50 points + 1 initial point. Each point has delta X, Y, time and heading. All signal groups are tied together with a trajectory id. 
All signalgroups include signals for E2E protection using profile 5 according to Autosar 4.2.2.

Signal group 7 includes:
* 6 PSS points, with overall sequence 39-44

 Heading position 5";
CM_ SG_ 100 AdPrimPSSGroupSafe7HeadingPos6 "Platform Safe Stop buffer paths. 

All signalgroups cover 50 points + 1 initial point. Each point has delta X, Y, time and heading. All signal groups are tied together with a trajectory id. 
All signalgroups include signals for E2E protection using profile 5 according to Autosar 4.2.2.

Signal group 7 includes:
* 6 PSS points, with overall sequence 39-44

 Heading position 6";
CM_ SG_ 100 AdPrimPSSGroupSafe7TrajectID "Platform Safe Stop buffer paths. 

All signalgroups cover 50 points + 1 initial point. Each point has delta X, Y, time and heading. All signal groups are tied together with a trajectory id. 
All signalgroups include signals for E2E protection using profile 5 according to Autosar 4.2.2.

Signal group 7 includes:
* 6 PSS points, with overall sequence 39-44

 Trajectory ID";
CM_ SG_ 104 AdPrimPSSGroupSafe8Chks "Platform Safe Stop buffer paths. 

All signalgroups cover 50 points + 1 initial point. Each point has delta X, Y, time and heading. All signal groups are tied together with a trajectory id. 
All signalgroups include signals for E2E protection using profile 5 according to Autosar 4.2.2.

Signal group 8 includes:
* 6 PSS points, with overall sequence 45-50 E2E checksum, profile 5";
CM_ SG_ 104 AdPrimPSSGroupSafe8Cntr "Platform Safe Stop buffer paths. 

All signalgroups cover 50 points + 1 initial point. Each point has delta X, Y, time and heading. All signal groups are tied together with a trajectory id. 
All signalgroups include signals for E2E protection using profile 5 according to Autosar 4.2.2.

Signal group 8 includes:
* 6 PSS points, with overall sequence 45-50 E2E counter, profile 5";
CM_ SG_ 104 AdPrimPSSGroupSafe8DataID "Platform Safe Stop buffer paths. 

All signalgroups cover 50 points + 1 initial point. Each point has delta X, Y, time and heading. All signal groups are tied together with a trajectory id. 
All signalgroups include signals for E2E protection using profile 5 according to Autosar 4.2.2.

Signal group 8 includes:
* 6 PSS points, with overall sequence 45-50 E2E Data ID, profile 5";
CM_ SG_ 104 AdPrimPSSGroupSafe8DeltaTPos1 "Platform Safe Stop buffer paths. 

All signalgroups cover 50 points + 1 initial point. Each point has delta X, Y, time and heading. All signal groups are tied together with a trajectory id. 
All signalgroups include signals for E2E protection using profile 5 according to Autosar 4.2.2.

Signal group 8 includes:
* 6 PSS points, with overall sequence 45-50 Delta time position 1";
CM_ SG_ 104 AdPrimPSSGroupSafe8DeltaTPos2 "Platform Safe Stop buffer paths. 

All signalgroups cover 50 points + 1 initial point. Each point has delta X, Y, time and heading. All signal groups are tied together with a trajectory id. 
All signalgroups include signals for E2E protection using profile 5 according to Autosar 4.2.2.

Signal group 8 includes:
* 6 PSS points, with overall sequence 45-50 Delta time position 2";
CM_ SG_ 104 AdPrimPSSGroupSafe8DeltaTPos3 "Platform Safe Stop buffer paths. 

All signalgroups cover 50 points + 1 initial point. Each point has delta X, Y, time and heading. All signal groups are tied together with a trajectory id. 
All signalgroups include signals for E2E protection using profile 5 according to Autosar 4.2.2.

Signal group 8 includes:
* 6 PSS points, with overall sequence 45-50 Delta time position 3";
CM_ SG_ 104 AdPrimPSSGroupSafe8DeltaTPos4 "Platform Safe Stop buffer paths. 

All signalgroups cover 50 points + 1 initial point. Each point has delta X, Y, time and heading. All signal groups are tied together with a trajectory id. 
All signalgroups include signals for E2E protection using profile 5 according to Autosar 4.2.2.

Signal group 8 includes:
* 6 PSS points, with overall sequence 45-50 Delta time position 4";
CM_ SG_ 104 AdPrimPSSGroupSafe8DeltaTPos5 "Platform Safe Stop buffer paths. 

All signalgroups cover 50 points + 1 initial point. Each point has delta X, Y, time and heading. All signal groups are tied together with a trajectory id. 
All signalgroups include signals for E2E protection using profile 5 according to Autosar 4.2.2.

Signal group 8 includes:
* 6 PSS points, with overall sequence 45-50 Delta time position 5";
CM_ SG_ 104 AdPrimPSSGroupSafe8DeltaTPos6 "Platform Safe Stop buffer paths. 

All signalgroups cover 50 points + 1 initial point. Each point has delta X, Y, time and heading. All signal groups are tied together with a trajectory id. 
All signalgroups include signals for E2E protection using profile 5 according to Autosar 4.2.2.

Signal group 8 includes:
* 6 PSS points, with overall sequence 45-50 Delta time position 6";
CM_ SG_ 104 AdPrimPSSGroupSafe8DeltaXPos1 "Platform Safe Stop buffer paths. 

All signalgroups cover 50 points + 1 initial point. Each point has delta X, Y, time and heading. All signal groups are tied together with a trajectory id. 
All signalgroups include signals for E2E protection using profile 5 according to Autosar 4.2.2.

Signal group 8 includes:
* 6 PSS points, with overall sequence 45-50 Delta X position 1";
CM_ SG_ 104 AdPrimPSSGroupSafe8DeltaXPos2 "Platform Safe Stop buffer paths. 

All signalgroups cover 50 points + 1 initial point. Each point has delta X, Y, time and heading. All signal groups are tied together with a trajectory id. 
All signalgroups include signals for E2E protection using profile 5 according to Autosar 4.2.2.

Signal group 8 includes:
* 6 PSS points, with overall sequence 45-50 Delta X position 2";
CM_ SG_ 104 AdPrimPSSGroupSafe8DeltaXPos3 "Platform Safe Stop buffer paths. 

All signalgroups cover 50 points + 1 initial point. Each point has delta X, Y, time and heading. All signal groups are tied together with a trajectory id. 
All signalgroups include signals for E2E protection using profile 5 according to Autosar 4.2.2.

Signal group 8 includes:
* 6 PSS points, with overall sequence 45-50 Delta X position 3";
CM_ SG_ 104 AdPrimPSSGroupSafe8DeltaXPos4 "Platform Safe Stop buffer paths. 

All signalgroups cover 50 points + 1 initial point. Each point has delta X, Y, time and heading. All signal groups are tied together with a trajectory id. 
All signalgroups include signals for E2E protection using profile 5 according to Autosar 4.2.2.

Signal group 8 includes:
* 6 PSS points, with overall sequence 45-50 Delta X position 4";
CM_ SG_ 104 AdPrimPSSGroupSafe8DeltaXPos5 "Platform Safe Stop buffer paths. 

All signalgroups cover 50 points + 1 initial point. Each point has delta X, Y, time and heading. All signal groups are tied together with a trajectory id. 
All signalgroups include signals for E2E protection using profile 5 according to Autosar 4.2.2.

Signal group 8 includes:
* 6 PSS points, with overall sequence 45-50 Delta X position 5";
CM_ SG_ 104 AdPrimPSSGroupSafe8DeltaXPos6 "Platform Safe Stop buffer paths. 

All signalgroups cover 50 points + 1 initial point. Each point has delta X, Y, time and heading. All signal groups are tied together with a trajectory id. 
All signalgroups include signals for E2E protection using profile 5 according to Autosar 4.2.2.

Signal group 8 includes:
* 6 PSS points, with overall sequence 45-50 Delta X position 6";
CM_ SG_ 104 AdPrimPSSGroupSafe8DeltaYPos1 "Platform Safe Stop buffer paths. 

All signalgroups cover 50 points + 1 initial point. Each point has delta X, Y, time and heading. All signal groups are tied together with a trajectory id. 
All signalgroups include signals for E2E protection using profile 5 according to Autosar 4.2.2.

Signal group 8 includes:
* 6 PSS points, with overall sequence 45-50 Delta Y position 1";
CM_ SG_ 104 AdPrimPSSGroupSafe8DeltaYPos2 "Platform Safe Stop buffer paths. 

All signalgroups cover 50 points + 1 initial point. Each point has delta X, Y, time and heading. All signal groups are tied together with a trajectory id. 
All signalgroups include signals for E2E protection using profile 5 according to Autosar 4.2.2.

Signal group 8 includes:
* 6 PSS points, with overall sequence 45-50 Delta Y position 2";
CM_ SG_ 104 AdPrimPSSGroupSafe8DeltaYPos3 "Platform Safe Stop buffer paths. 

All signalgroups cover 50 points + 1 initial point. Each point has delta X, Y, time and heading. All signal groups are tied together with a trajectory id. 
All signalgroups include signals for E2E protection using profile 5 according to Autosar 4.2.2.

Signal group 8 includes:
* 6 PSS points, with overall sequence 45-50 Delta Y position 3";
CM_ SG_ 104 AdPrimPSSGroupSafe8DeltaYPos4 "Platform Safe Stop buffer paths. 

All signalgroups cover 50 points + 1 initial point. Each point has delta X, Y, time and heading. All signal groups are tied together with a trajectory id. 
All signalgroups include signals for E2E protection using profile 5 according to Autosar 4.2.2.

Signal group 8 includes:
* 6 PSS points, with overall sequence 45-50 Delta Y position 4";
CM_ SG_ 104 AdPrimPSSGroupSafe8DeltaYPos5 "Platform Safe Stop buffer paths. 

All signalgroups cover 50 points + 1 initial point. Each point has delta X, Y, time and heading. All signal groups are tied together with a trajectory id. 
All signalgroups include signals for E2E protection using profile 5 according to Autosar 4.2.2.

Signal group 8 includes:
* 6 PSS points, with overall sequence 45-50 Delta Y position 5";
CM_ SG_ 104 AdPrimPSSGroupSafe8DeltaYPos6 "Platform Safe Stop buffer paths. 

All signalgroups cover 50 points + 1 initial point. Each point has delta X, Y, time and heading. All signal groups are tied together with a trajectory id. 
All signalgroups include signals for E2E protection using profile 5 according to Autosar 4.2.2.

Signal group 8 includes:
* 6 PSS points, with overall sequence 45-50 Delta Y position 6";
CM_ SG_ 104 AdPrimPSSGroupSafe8HeadingPos1 "Platform Safe Stop buffer paths. 

All signalgroups cover 50 points + 1 initial point. Each point has delta X, Y, time and heading. All signal groups are tied together with a trajectory id. 
All signalgroups include signals for E2E protection using profile 5 according to Autosar 4.2.2.

Signal group 8 includes:
* 6 PSS points, with overall sequence 45-50 Heading position 1";
CM_ SG_ 104 AdPrimPSSGroupSafe8HeadingPos2 "Platform Safe Stop buffer paths. 

All signalgroups cover 50 points + 1 initial point. Each point has delta X, Y, time and heading. All signal groups are tied together with a trajectory id. 
All signalgroups include signals for E2E protection using profile 5 according to Autosar 4.2.2.

Signal group 8 includes:
* 6 PSS points, with overall sequence 45-50 Heading position 2";
CM_ SG_ 104 AdPrimPSSGroupSafe8HeadingPos3 "Platform Safe Stop buffer paths. 

All signalgroups cover 50 points + 1 initial point. Each point has delta X, Y, time and heading. All signal groups are tied together with a trajectory id. 
All signalgroups include signals for E2E protection using profile 5 according to Autosar 4.2.2.

Signal group 8 includes:
* 6 PSS points, with overall sequence 45-50 Heading position 3";
CM_ SG_ 104 AdPrimPSSGroupSafe8HeadingPos4 "Platform Safe Stop buffer paths. 

All signalgroups cover 50 points + 1 initial point. Each point has delta X, Y, time and heading. All signal groups are tied together with a trajectory id. 
All signalgroups include signals for E2E protection using profile 5 according to Autosar 4.2.2.

Signal group 8 includes:
* 6 PSS points, with overall sequence 45-50 Heading position 4";
CM_ SG_ 104 AdPrimPSSGroupSafe8HeadingPos5 "Platform Safe Stop buffer paths. 

All signalgroups cover 50 points + 1 initial point. Each point has delta X, Y, time and heading. All signal groups are tied together with a trajectory id. 
All signalgroups include signals for E2E protection using profile 5 according to Autosar 4.2.2.

Signal group 8 includes:
* 6 PSS points, with overall sequence 45-50 Heading position 5";
CM_ SG_ 104 AdPrimPSSGroupSafe8HeadingPos6 "Platform Safe Stop buffer paths. 

All signalgroups cover 50 points + 1 initial point. Each point has delta X, Y, time and heading. All signal groups are tied together with a trajectory id. 
All signalgroups include signals for E2E protection using profile 5 according to Autosar 4.2.2.

Signal group 8 includes:
* 6 PSS points, with overall sequence 45-50 Heading position 6";
CM_ SG_ 104 AdPrimPSSGroupSafe8TrajectID "Platform Safe Stop buffer paths. 

All signalgroups cover 50 points + 1 initial point. Each point has delta X, Y, time and heading. All signal groups are tied together with a trajectory id. 
All signalgroups include signals for E2E protection using profile 5 according to Autosar 4.2.2.

Signal group 8 includes:
* 6 PSS points, with overall sequence 45-50 Trajectory ID";
CM_ SG_ 34 AdPrimWhlAgReqGroupSafeChks "AD Requested wheel angle, primary channel E2E Checksum";
CM_ SG_ 34 AdPrimWhlAgReqGroupSafeCntr "AD Requested wheel angle, primary channel E2E Counter";
CM_ SG_ 34 AdPrimWhlAgReqGroupSafeWhlAgReq "AD Requested wheel angle, primary channel The requested wheel angle. The wheel angle is supervised by the LatCtrl ASIL D supervisory controller before being converted to an ASIL D rack position request.";
CM_ SG_ 60 AdPrimSafeStopReqSafeChks "Safe stop request E2E checksum";
CM_ SG_ 60 AdPrimSafeStopReqSafeCntr "Safe stop request E2E counter";
CM_ SG_ 60 AdPrimSafeStopReqSafeSafeStopReq "Safe stop request Safe stop request";
CM_ SG_ 60 SDSFltMgrStsSafeChks " CRC";
CM_ SG_ 60 SDSFltMgrStsSafeCntr " Counter";
CM_ SG_ 40 PrimMonTiSyncMsgChks "Used for validating Autosar time synchronization mechanism in SSM. Profile VCC checksum";
CM_ SG_ 40 PrimMonTiSyncMsgCntr "Used for validating Autosar time synchronization mechanism in SSM. Profile VCC counter";
CM_ SG_ 40 PrimMonTiSyncMsgTiStampNanoSec "Used for validating Autosar time synchronization mechanism in SSM. Time stamp, nano seconds";
CM_ SG_ 40 PrimMonTiSyncMsgTiStampSec "Used for validating Autosar time synchronization mechanism in SSM. Time stamp, seconds";
BA_DEF_  "BaudRateCANFD" FLOAT 1000 10000000;
BA_DEF_  "Baudrate" INT 1000 1000000;
BA_DEF_  "BusType" STRING ;
BA_DEF_  "DBName" STRING ;
BA_DEF_  "ProtocolType" STRING ;
BA_DEF_ BU_  "NmAsrNode" ENUM  "No","Yes";
BA_DEF_ BU_  "NmAsrNodeIdentifier" INT 0 255;
BA_DEF_ BO_  "CANFD_BRS" ENUM  "0","1";
BA_DEF_ BO_  "GenMsgCycleTime" INT 0 65536;
BA_DEF_ BO_  "GenMsgDelayTime" INT 0 65536;
BA_DEF_ BO_  "GenMsgSendType" ENUM  "cyclic","spontaneous","not-used","not-used","not-used","cyclicAndSpontaneous","not-used","cyclicIfActive","NoMsgSendType";
BA_DEF_ BO_  "GenMsgStartDelayTime" INT 0 65536;
BA_DEF_ BO_  "VFrameFormat" ENUM  "StandardCAN","ExtendedCAN","reserved","J1939PG","reserved","reserved","reserved","reserved","reserved","reserved","reserved","reserved","reserved","reserved","StandardCAN_FD","ExtendedCAN_FD";
BA_DEF_ SG_  "GenSigSendType" ENUM  "Cyclic","OnWrite","OnWriteWithRepetition","OnChange","OnChangeWithRepetition","IfActive","IfActiveWithRepetition","NoSigSendType";
BA_DEF_ SG_  "GenSigStartValue" HEX 0 80000000;
BA_DEF_ BO_  "GenMsgILSupport" ENUM  "No","Yes";
BA_DEF_ BO_  "NmAsrMessage" ENUM  "No","Yes";
BA_DEF_  "NmAsrBaseAddress" HEX 0 536870911;
BA_DEF_  "NmAsrMessageCount" INT 0 255;
BA_DEF_ BU_  "NodeLayerModules" STRING ;
BA_DEF_ BU_  "ILused" ENUM  "No","Yes";
BA_DEF_ SG_  "GenSigFuncType" ENUM  "NoFunction","n/a","n/a","n/a","n/a","n/a","n/a","n/a","n/a","n/a","n/a","n/a","n/a","n/a","n/a","CHK","CNTR","n/a","n/a","n/a","CNTR_AR_01","CRC_AR_01_BOTH","CRC_AR_01_ALT","CRC_AR_01_LOW","CRC_AR_01_NIBBLE","CNTR_AR_04","CRC_AR_04A","CNTR_AR_05","CRC_AR_05";
BA_DEF_ SG_  "GenSigDataID" STRING ;
BA_DEF_ SG_  "SystemSignalLongSymbol" STRING ;
BA_DEF_DEF_  "BaudRateCANFD" 1000;
BA_DEF_DEF_  "Baudrate" 1000;
BA_DEF_DEF_  "BusType" "";
BA_DEF_DEF_  "DBName" "";
BA_DEF_DEF_  "ProtocolType" "";
BA_DEF_DEF_  "NmAsrNode" "No";
BA_DEF_DEF_  "NmAsrNodeIdentifier" 0;
BA_DEF_DEF_  "CANFD_BRS" "1";
BA_DEF_DEF_  "GenMsgCycleTime" 0;
BA_DEF_DEF_  "GenMsgDelayTime" 0;
BA_DEF_DEF_  "GenMsgSendType" "NoMsgSendType";
BA_DEF_DEF_  "GenMsgStartDelayTime" 0;
BA_DEF_DEF_  "VFrameFormat" "J1939PG";
BA_DEF_DEF_  "GenSigSendType" "NoSigSendType";
BA_DEF_DEF_  "GenSigStartValue" 0;
BA_DEF_DEF_  "GenMsgILSupport" "Yes";
BA_DEF_DEF_  "NmAsrMessage" "No";
BA_DEF_DEF_  "NmAsrBaseAddress" 1280;
BA_DEF_DEF_  "NmAsrMessageCount" 64;
BA_DEF_DEF_  "NodeLayerModules" "CANoeILNLSPA.dll";
BA_DEF_DEF_  "ILused" "Yes";
BA_DEF_DEF_  "GenSigFuncType" "NoFunction";
BA_DEF_DEF_  "GenSigDataID" "";
BA_DEF_DEF_  "SystemSignalLongSymbol" "";
BA_ "BaudRateCANFD" 2000000;
BA_ "Baudrate" 500000;
BA_ "BusType" "CAN FD";
BA_ "ProtocolType" "CAN";
BA_ "DBName" "Mid5CANFD";
BA_ "ILused" BU_ ETC 0;
BA_ "NmAsrNode" BU_ SSM 1;
BA_ "NmAsrNodeIdentifier" BU_ SSM 5;
BA_ "NodeLayerModules" BU_ SSM "CANoeILNLSPA.dll,AsrNM33.dll";
BA_ "NmAsrNode" BU_ VIM 1;
BA_ "NmAsrNodeIdentifier" BU_ VIM 6;
BA_ "NodeLayerModules" BU_ VIM "CANoeILNLSPA.dll,AsrNM33.dll";
BA_ "GenMsgDelayTime" BO_ 1285 20;
BA_ "GenMsgSendType" BO_ 1285 1;
BA_ "VFrameFormat" BO_ 1285 0;
BA_ "GenMsgILSupport" BO_ 1285 0;
BA_ "NmAsrMessage" BO_ 1285 1;
BA_ "GenMsgCycleTime" BO_ 20 5;
BA_ "GenMsgSendType" BO_ 20 0;
BA_ "VFrameFormat" BO_ 20 14;
BA_ "GenMsgCycleTime" BO_ 43 10;
BA_ "GenMsgSendType" BO_ 43 0;
BA_ "VFrameFormat" BO_ 43 14;
BA_ "GenMsgCycleTime" BO_ 32 10;
BA_ "GenMsgSendType" BO_ 32 0;
BA_ "VFrameFormat" BO_ 32 14;
BA_ "GenMsgCycleTime" BO_ 21 10;
BA_ "GenMsgSendType" BO_ 21 0;
BA_ "VFrameFormat" BO_ 21 14;
BA_ "GenMsgCycleTime" BO_ 52 20;
BA_ "GenMsgSendType" BO_ 52 0;
BA_ "VFrameFormat" BO_ 52 14;
BA_ "GenMsgCycleTime" BO_ 58 25;
BA_ "GenMsgSendType" BO_ 58 0;
BA_ "VFrameFormat" BO_ 58 14;
BA_ "GenMsgCycleTime" BO_ 257 160;
BA_ "GenMsgSendType" BO_ 257 0;
BA_ "VFrameFormat" BO_ 257 14;
BA_ "GenMsgDelayTime" BO_ 1286 20;
BA_ "GenMsgSendType" BO_ 1286 1;
BA_ "VFrameFormat" BO_ 1286 0;
BA_ "GenMsgILSupport" BO_ 1286 0;
BA_ "NmAsrMessage" BO_ 1286 1;
BA_ "GenMsgCycleTime" BO_ 33 10;
BA_ "GenMsgSendType" BO_ 33 0;
BA_ "VFrameFormat" BO_ 33 14;
BA_ "GenMsgCycleTime" BO_ 65 90;
BA_ "GenMsgSendType" BO_ 65 0;
BA_ "VFrameFormat" BO_ 65 14;
BA_ "GenMsgCycleTime" BO_ 68 90;
BA_ "GenMsgSendType" BO_ 68 0;
BA_ "VFrameFormat" BO_ 68 14;
BA_ "GenMsgCycleTime" BO_ 72 90;
BA_ "GenMsgSendType" BO_ 72 0;
BA_ "VFrameFormat" BO_ 72 14;
BA_ "GenMsgCycleTime" BO_ 82 90;
BA_ "GenMsgSendType" BO_ 82 0;
BA_ "VFrameFormat" BO_ 82 14;
BA_ "GenMsgCycleTime" BO_ 84 90;
BA_ "GenMsgSendType" BO_ 84 0;
BA_ "VFrameFormat" BO_ 84 14;
BA_ "GenMsgCycleTime" BO_ 88 90;
BA_ "GenMsgSendType" BO_ 88 0;
BA_ "VFrameFormat" BO_ 88 14;
BA_ "GenMsgCycleTime" BO_ 98 90;
BA_ "GenMsgSendType" BO_ 98 0;
BA_ "VFrameFormat" BO_ 98 14;
BA_ "GenMsgCycleTime" BO_ 100 90;
BA_ "GenMsgSendType" BO_ 100 0;
BA_ "VFrameFormat" BO_ 100 14;
BA_ "GenMsgCycleTime" BO_ 104 90;
BA_ "GenMsgSendType" BO_ 104 0;
BA_ "VFrameFormat" BO_ 104 14;
BA_ "GenMsgCycleTime" BO_ 34 10;
BA_ "GenMsgSendType" BO_ 34 0;
BA_ "VFrameFormat" BO_ 34 14;
BA_ "GenMsgCycleTime" BO_ 60 60;
BA_ "GenMsgSendType" BO_ 60 0;
BA_ "VFrameFormat" BO_ 60 14;
BA_ "GenMsgDelayTime" BO_ 53 20;
BA_ "GenMsgSendType" BO_ 53 1;
BA_ "VFrameFormat" BO_ 53 14;
BA_ "GenMsgDelayTime" BO_ 40 100;
BA_ "GenMsgSendType" BO_ 40 1;
BA_ "VFrameFormat" BO_ 40 14;
BA_ "GenSigStartValue" SG_ 20 PinionSteerAg1Qf 1;
BA_ "GenSigStartValue" SG_ 20 PinionSteerAgSpd1Qf 1;
BA_ "GenSigDataID" SG_ 43 AdPrimMotTqASILThrshldExcdChks "0x727";
BA_ "GenSigFuncType" SG_ 43 AdPrimMotTqASILThrshldExcdChks 15;
BA_ "GenSigFuncType" SG_ 43 AdPrimMotTqASILThrshldExcdCntr 16;
BA_ "SystemSignalLongSymbol" SG_ 43 AdPrimMotTqASILThrshldExcdThrshl "AdPrimMotTqASILThrshldExcdThrshldExceeded";
BA_ "GenSigDataID" SG_ 43 PrimPoseMonSafeChks "0x80B";
BA_ "GenSigFuncType" SG_ 43 PrimPoseMonSafeChks 15;
BA_ "GenSigFuncType" SG_ 43 PrimPoseMonSafeCntr 16;
BA_ "GenSigDataID" SG_ 32 AdPrimWhlAgEstimdGroupSafeChks "0x1AF";
BA_ "GenSigFuncType" SG_ 32 AdPrimWhlAgEstimdGroupSafeChks 15;
BA_ "GenSigFuncType" SG_ 32 AdPrimWhlAgEstimdGroupSafeCntr 16;
BA_ "GenSigStartValue" SG_ 32 AdPrimWhlAgEstimdGroupSafeWhlAg 16193.5606782;
BA_ "GenSigStartValue" SG_ 32 AdPrimWhlAgEstimdGroupSafeWhlAgR 14000;
BA_ "SystemSignalLongSymbol" SG_ 32 AdPrimWhlAgEstimdGroupSafeWhlAgR "AdPrimWhlAgEstimdGroupSafeWhlAgRate";
BA_ "GenSigDataID" SG_ 32 PrimALatDataRawSafeChks "0x20E";
BA_ "GenSigFuncType" SG_ 32 PrimALatDataRawSafeChks 15;
BA_ "GenSigFuncType" SG_ 32 PrimALatDataRawSafeCntr 16;
BA_ "GenSigStartValue" SG_ 32 PrimALatDataRawSafeMax 16384;
BA_ "GenSigStartValue" SG_ 32 PrimALatDataRawSafeMin 16384;
BA_ "GenSigStartValue" SG_ 32 PrimALatDataRawSafeNom 16384;
BA_ "GenSigStartValue" SG_ 32 PrimALatDataRawSafeNomQf 1;
BA_ "GenSigStartValue" SG_ 32 PrimAxleSlipStsAndRelAgFrntAxle 1;
BA_ "GenSigStartValue" SG_ 32 PrimAxleSlipStsAndRelAgIntvSts 1;
BA_ "GenSigStartValue" SG_ 32 PrimAxleSlipStsAndRelAgReAxle 1;
BA_ "GenSigStartValue" SG_ 32 PrimAxleSlipStsAndRelAgRelPitchQ 1;
BA_ "SystemSignalLongSymbol" SG_ 32 PrimAxleSlipStsAndRelAgRelPitchQ "PrimAxleSlipStsAndRelAgRelPitchQf";
BA_ "GenSigStartValue" SG_ 32 PrimAxleSlipStsAndRelAgRelRolQf 1;
BA_ "GenSigDataID" SG_ 32 PrimVLatSafeChks "0x505";
BA_ "GenSigFuncType" SG_ 32 PrimVLatSafeChks 15;
BA_ "GenSigFuncType" SG_ 32 PrimVLatSafeCntr 16;
BA_ "GenSigStartValue" SG_ 32 PrimVLatSafeNomQf 1;
BA_ "GenSigDataID" SG_ 32 PrimWhlRotDirReSafe1Chks "0x714";
BA_ "GenSigFuncType" SG_ 32 PrimWhlRotDirReSafe1Chks 15;
BA_ "GenSigFuncType" SG_ 32 PrimWhlRotDirReSafe1Cntr 16;
BA_ "GenSigStartValue" SG_ 32 PrimWhlRotDirReSafe1LeQf 1;
BA_ "GenSigStartValue" SG_ 32 PrimWhlRotDirReSafe1RiQf 1;
BA_ "GenSigDataID" SG_ 32 PrimWhlRotToothCntrChks "0x578";
BA_ "GenSigFuncType" SG_ 32 PrimWhlRotToothCntrChks 15;
BA_ "GenSigFuncType" SG_ 32 PrimWhlRotToothCntrCntr 16;
BA_ "SystemSignalLongSymbol" SG_ 32 PrimWhlRotToothCntrWhlRotToothCn "PrimWhlRotToothCntrWhlRotToothCntrFrntLe";
BA_ "GenSigStartValue" SG_ 32 PrimWhlRotToothCntrWhlRotTo_0000 1;
BA_ "SystemSignalLongSymbol" SG_ 32 PrimWhlRotToothCntrWhlRotTo_0000 "PrimWhlRotToothCntrWhlRotToothCntrFrntLeQf";
BA_ "SystemSignalLongSymbol" SG_ 32 PrimWhlRotToothCntrWhlRotTo_0001 "PrimWhlRotToothCntrWhlRotToothCntrFrntRi";
BA_ "GenSigStartValue" SG_ 32 PrimWhlRotToothCntrWhlRotTo_0002 1;
BA_ "SystemSignalLongSymbol" SG_ 32 PrimWhlRotToothCntrWhlRotTo_0002 "PrimWhlRotToothCntrWhlRotToothCntrFrntRiQf";
BA_ "SystemSignalLongSymbol" SG_ 32 PrimWhlRotToothCntrWhlRotTo_0003 "PrimWhlRotToothCntrWhlRotToothCntrReLe";
BA_ "GenSigStartValue" SG_ 32 PrimWhlRotToothCntrWhlRotTo_0004 1;
BA_ "SystemSignalLongSymbol" SG_ 32 PrimWhlRotToothCntrWhlRotTo_0004 "PrimWhlRotToothCntrWhlRotToothCntrReLeQf";
BA_ "SystemSignalLongSymbol" SG_ 32 PrimWhlRotToothCntrWhlRotTo_0005 "PrimWhlRotToothCntrWhlRotToothCntrReRi";
BA_ "GenSigStartValue" SG_ 32 PrimWhlRotToothCntrWhlRotTo_0006 1;
BA_ "SystemSignalLongSymbol" SG_ 32 PrimWhlRotToothCntrWhlRotTo_0006 "PrimWhlRotToothCntrWhlRotToothCntrReRiQf";
BA_ "GenSigDataID" SG_ 32 PrimYawRateSafeChks "0x212";
BA_ "GenSigFuncType" SG_ 32 PrimYawRateSafeChks 15;
BA_ "GenSigFuncType" SG_ 32 PrimYawRateSafeCntr 16;
BA_ "GenSigStartValue" SG_ 32 PrimYawRateSafeNomQf 1;
BA_ "GenSigDataID" SG_ 21 PrimVehMSafeChks "0x725";
BA_ "GenSigFuncType" SG_ 21 PrimVehMSafeChks 15;
BA_ "GenSigFuncType" SG_ 21 PrimVehMSafeCntr 16;
BA_ "GenSigStartValue" SG_ 21 PrimVehMSafeNomQf 1;
BA_ "GenSigDataID" SG_ 21 PrimWhlAgSpdFrntSafeChks "0x1E3";
BA_ "GenSigFuncType" SG_ 21 PrimWhlAgSpdFrntSafeChks 15;
BA_ "GenSigFuncType" SG_ 21 PrimWhlAgSpdFrntSafeCntr 16;
BA_ "GenSigStartValue" SG_ 21 PrimWhlAgSpdFrntSafeLeQf 1;
BA_ "GenSigStartValue" SG_ 21 PrimWhlAgSpdFrntSafeRiQf 1;
BA_ "GenSigDataID" SG_ 21 PrimWhlAgSpdReSafeChks "0x1E4";
BA_ "GenSigFuncType" SG_ 21 PrimWhlAgSpdReSafeChks 15;
BA_ "GenSigFuncType" SG_ 21 PrimWhlAgSpdReSafeCntr 16;
BA_ "GenSigStartValue" SG_ 21 PrimWhlAgSpdReSafeLeQf 1;
BA_ "GenSigStartValue" SG_ 21 PrimWhlAgSpdReSafeRiQf 1;
BA_ "GenSigStartValue" SG_ 52 AdPrimWhlAgRateLimEstimdSafeAdWh 14000;
BA_ "SystemSignalLongSymbol" SG_ 52 AdPrimWhlAgRateLimEstimdSafeAdWh "AdPrimWhlAgRateLimEstimdSafeAdWhlAgRate1";
BA_ "GenSigDataID" SG_ 52 AdPrimWhlAgRateLimEstimdSafeChks "0x434";
BA_ "GenSigFuncType" SG_ 52 AdPrimWhlAgRateLimEstimdSafeChks 15;
BA_ "GenSigFuncType" SG_ 52 AdPrimWhlAgRateLimEstimdSafeCntr 16;
BA_ "SystemSignalLongSymbol" SG_ 52 PrimMaxALatEstimdGroupAccelerati "PrimMaxALatEstimdGroupAcceleration";
BA_ "GenSigDataID" SG_ 58 AdPrimSafeStopActvGroupSafeChks "0x1EB";
BA_ "GenSigFuncType" SG_ 58 AdPrimSafeStopActvGroupSafeChks 15;
BA_ "GenSigFuncType" SG_ 58 AdPrimSafeStopActvGroupSafeCntr 16;
BA_ "SystemSignalLongSymbol" SG_ 58 AdPrimSafeStopActvGroupSafePlatf "AdPrimSafeStopActvGroupSafePlatformSafeStopActv";
BA_ "GenSigStartValue" SG_ 33 AdPrimPoseAX 524290;
BA_ "GenSigStartValue" SG_ 33 AdPrimPoseAY 524290;
BA_ "GenSigStartValue" SG_ 33 AdPrimPoseAZ 524290;
BA_ "GenSigDataID" SG_ 33 AdPrimPoseChks "0x437";
BA_ "GenSigFuncType" SG_ 33 AdPrimPoseChks 28;
BA_ "GenSigFuncType" SG_ 33 AdPrimPoseCntr 27;
BA_ "GenSigStartValue" SG_ 33 AdPrimPosePitch 32760;
BA_ "GenSigStartValue" SG_ 33 AdPrimPosePitchRate 524300;
BA_ "GenSigStartValue" SG_ 33 AdPrimPoseRoll 32760;
BA_ "GenSigStartValue" SG_ 33 AdPrimPoseRollRate 524300;
BA_ "GenSigStartValue" SG_ 33 AdPrimPoseVX 12768;
BA_ "GenSigStartValue" SG_ 33 AdPrimPoseVY 8192;
BA_ "GenSigStartValue" SG_ 33 AdPrimPoseYaw 8388000;
BA_ "GenSigStartValue" SG_ 33 AdPrimPoseYawRate 2097000;
BA_ "GenSigDataID" SG_ 65 AdPrimPSSGroupSafe0Chks "0x2BB";
BA_ "GenSigFuncType" SG_ 65 AdPrimPSSGroupSafe0Chks 28;
BA_ "GenSigFuncType" SG_ 65 AdPrimPSSGroupSafe0Cntr 27;
BA_ "GenSigStartValue" SG_ 65 AdPrimPSSGroupSafe0DeltaXPos1 131070;
BA_ "GenSigStartValue" SG_ 65 AdPrimPSSGroupSafe0DeltaXPos2 131070;
BA_ "GenSigStartValue" SG_ 65 AdPrimPSSGroupSafe0DeltaYPos1 131070;
BA_ "GenSigStartValue" SG_ 65 AdPrimPSSGroupSafe0DeltaYPos2 131070;
BA_ "GenSigStartValue" SG_ 65 AdPrimPSSGroupSafe0HeadingPos1 32767;
BA_ "GenSigStartValue" SG_ 65 AdPrimPSSGroupSafe0HeadingPos2 32767;
BA_ "GenSigStartValue" SG_ 65 AdPrimPSSGroupSafe0InitHeading 32767;
BA_ "SystemSignalLongSymbol" SG_ 65 AdPrimPSSGroupSafe0TiStampNanoSe "AdPrimPSSGroupSafe0TiStampNanoSec";
BA_ "GenSigDataID" SG_ 68 AdPrimPSSGroupSafe1Chks "0x2BC";
BA_ "GenSigFuncType" SG_ 68 AdPrimPSSGroupSafe1Chks 28;
BA_ "GenSigFuncType" SG_ 68 AdPrimPSSGroupSafe1Cntr 27;
BA_ "GenSigStartValue" SG_ 68 AdPrimPSSGroupSafe1DeltaXPos1 131070;
BA_ "GenSigStartValue" SG_ 68 AdPrimPSSGroupSafe1DeltaXPos2 131070;
BA_ "GenSigStartValue" SG_ 68 AdPrimPSSGroupSafe1DeltaXPos3 131070;
BA_ "GenSigStartValue" SG_ 68 AdPrimPSSGroupSafe1DeltaXPos4 131070;
BA_ "GenSigStartValue" SG_ 68 AdPrimPSSGroupSafe1DeltaXPos5 131070;
BA_ "GenSigStartValue" SG_ 68 AdPrimPSSGroupSafe1DeltaXPos6 131070;
BA_ "GenSigStartValue" SG_ 68 AdPrimPSSGroupSafe1DeltaYPos1 131070;
BA_ "GenSigStartValue" SG_ 68 AdPrimPSSGroupSafe1DeltaYPos2 131070;
BA_ "GenSigStartValue" SG_ 68 AdPrimPSSGroupSafe1DeltaYPos3 131070;
BA_ "GenSigStartValue" SG_ 68 AdPrimPSSGroupSafe1DeltaYPos4 131070;
BA_ "GenSigStartValue" SG_ 68 AdPrimPSSGroupSafe1DeltaYPos5 131070;
BA_ "GenSigStartValue" SG_ 68 AdPrimPSSGroupSafe1DeltaYPos6 131070;
BA_ "GenSigStartValue" SG_ 68 AdPrimPSSGroupSafe1HeadingPos1 32767;
BA_ "GenSigStartValue" SG_ 68 AdPrimPSSGroupSafe1HeadingPos2 32767;
BA_ "GenSigStartValue" SG_ 68 AdPrimPSSGroupSafe1HeadingPos3 32767;
BA_ "GenSigStartValue" SG_ 68 AdPrimPSSGroupSafe1HeadingPos4 32767;
BA_ "GenSigStartValue" SG_ 68 AdPrimPSSGroupSafe1HeadingPos5 32767;
BA_ "GenSigStartValue" SG_ 68 AdPrimPSSGroupSafe1HeadingPos6 32767;
BA_ "GenSigDataID" SG_ 72 AdPrimPSSGroupSafe2Chks "0x2BD";
BA_ "GenSigFuncType" SG_ 72 AdPrimPSSGroupSafe2Chks 28;
BA_ "GenSigFuncType" SG_ 72 AdPrimPSSGroupSafe2Cntr 27;
BA_ "GenSigStartValue" SG_ 72 AdPrimPSSGroupSafe2DeltaXPos1 131070;
BA_ "GenSigStartValue" SG_ 72 AdPrimPSSGroupSafe2DeltaXPos2 131070;
BA_ "GenSigStartValue" SG_ 72 AdPrimPSSGroupSafe2DeltaXPos3 131070;
BA_ "GenSigStartValue" SG_ 72 AdPrimPSSGroupSafe2DeltaXPos4 131070;
BA_ "GenSigStartValue" SG_ 72 AdPrimPSSGroupSafe2DeltaXPos5 131070;
BA_ "GenSigStartValue" SG_ 72 AdPrimPSSGroupSafe2DeltaXPos6 131070;
BA_ "GenSigStartValue" SG_ 72 AdPrimPSSGroupSafe2DeltaYPos1 131070;
BA_ "GenSigStartValue" SG_ 72 AdPrimPSSGroupSafe2DeltaYPos2 131070;
BA_ "GenSigStartValue" SG_ 72 AdPrimPSSGroupSafe2DeltaYPos3 131070;
BA_ "GenSigStartValue" SG_ 72 AdPrimPSSGroupSafe2DeltaYPos4 131070;
BA_ "GenSigStartValue" SG_ 72 AdPrimPSSGroupSafe2DeltaYPos5 131070;
BA_ "GenSigStartValue" SG_ 72 AdPrimPSSGroupSafe2DeltaYPos6 131070;
BA_ "GenSigStartValue" SG_ 72 AdPrimPSSGroupSafe2HeadingPos1 32767;
BA_ "GenSigStartValue" SG_ 72 AdPrimPSSGroupSafe2HeadingPos2 32767;
BA_ "GenSigStartValue" SG_ 72 AdPrimPSSGroupSafe2HeadingPos3 32767;
BA_ "GenSigStartValue" SG_ 72 AdPrimPSSGroupSafe2HeadingPos4 32767;
BA_ "GenSigStartValue" SG_ 72 AdPrimPSSGroupSafe2HeadingPos5 32767;
BA_ "GenSigStartValue" SG_ 72 AdPrimPSSGroupSafe2HeadingPos6 32767;
BA_ "GenSigDataID" SG_ 82 AdPrimPSSGroupSafe3Chks "0x2BE";
BA_ "GenSigFuncType" SG_ 82 AdPrimPSSGroupSafe3Chks 28;
BA_ "GenSigFuncType" SG_ 82 AdPrimPSSGroupSafe3Cntr 27;
BA_ "GenSigStartValue" SG_ 82 AdPrimPSSGroupSafe3DeltaXPos1 131070;
BA_ "GenSigStartValue" SG_ 82 AdPrimPSSGroupSafe3DeltaXPos2 131070;
BA_ "GenSigStartValue" SG_ 82 AdPrimPSSGroupSafe3DeltaXPos3 131070;
BA_ "GenSigStartValue" SG_ 82 AdPrimPSSGroupSafe3DeltaXPos4 131070;
BA_ "GenSigStartValue" SG_ 82 AdPrimPSSGroupSafe3DeltaXPos5 131070;
BA_ "GenSigStartValue" SG_ 82 AdPrimPSSGroupSafe3DeltaXPos6 131070;
BA_ "GenSigStartValue" SG_ 82 AdPrimPSSGroupSafe3DeltaYPos1 131070;
BA_ "GenSigStartValue" SG_ 82 AdPrimPSSGroupSafe3DeltaYPos2 131070;
BA_ "GenSigStartValue" SG_ 82 AdPrimPSSGroupSafe3DeltaYPos3 131070;
BA_ "GenSigStartValue" SG_ 82 AdPrimPSSGroupSafe3DeltaYPos4 131070;
BA_ "GenSigStartValue" SG_ 82 AdPrimPSSGroupSafe3DeltaYPos5 131070;
BA_ "GenSigStartValue" SG_ 82 AdPrimPSSGroupSafe3DeltaYPos6 131070;
BA_ "GenSigStartValue" SG_ 82 AdPrimPSSGroupSafe3HeadingPos1 32767;
BA_ "GenSigStartValue" SG_ 82 AdPrimPSSGroupSafe3HeadingPos2 32767;
BA_ "GenSigStartValue" SG_ 82 AdPrimPSSGroupSafe3HeadingPos3 32767;
BA_ "GenSigStartValue" SG_ 82 AdPrimPSSGroupSafe3HeadingPos4 32767;
BA_ "GenSigStartValue" SG_ 82 AdPrimPSSGroupSafe3HeadingPos5 32767;
BA_ "GenSigStartValue" SG_ 82 AdPrimPSSGroupSafe3HeadingPos6 32767;
BA_ "GenSigDataID" SG_ 84 AdPrimPSSGroupSafe4Chks "0x2BF";
BA_ "GenSigFuncType" SG_ 84 AdPrimPSSGroupSafe4Chks 28;
BA_ "GenSigFuncType" SG_ 84 AdPrimPSSGroupSafe4Cntr 27;
BA_ "GenSigStartValue" SG_ 84 AdPrimPSSGroupSafe4DeltaXPos1 131070;
BA_ "GenSigStartValue" SG_ 84 AdPrimPSSGroupSafe4DeltaXPos2 131070;
BA_ "GenSigStartValue" SG_ 84 AdPrimPSSGroupSafe4DeltaXPos3 131070;
BA_ "GenSigStartValue" SG_ 84 AdPrimPSSGroupSafe4DeltaXPos4 131070;
BA_ "GenSigStartValue" SG_ 84 AdPrimPSSGroupSafe4DeltaXPos5 131070;
BA_ "GenSigStartValue" SG_ 84 AdPrimPSSGroupSafe4DeltaXPos6 131070;
BA_ "GenSigStartValue" SG_ 84 AdPrimPSSGroupSafe4DeltaYPos1 131070;
BA_ "GenSigStartValue" SG_ 84 AdPrimPSSGroupSafe4DeltaYPos2 131070;
BA_ "GenSigStartValue" SG_ 84 AdPrimPSSGroupSafe4DeltaYPos3 131070;
BA_ "GenSigStartValue" SG_ 84 AdPrimPSSGroupSafe4DeltaYPos4 131070;
BA_ "GenSigStartValue" SG_ 84 AdPrimPSSGroupSafe4DeltaYPos5 131070;
BA_ "GenSigStartValue" SG_ 84 AdPrimPSSGroupSafe4DeltaYPos6 131070;
BA_ "GenSigStartValue" SG_ 84 AdPrimPSSGroupSafe4HeadingPos1 32767;
BA_ "GenSigStartValue" SG_ 84 AdPrimPSSGroupSafe4HeadingPos2 32767;
BA_ "GenSigStartValue" SG_ 84 AdPrimPSSGroupSafe4HeadingPos3 32767;
BA_ "GenSigStartValue" SG_ 84 AdPrimPSSGroupSafe4HeadingPos4 32767;
BA_ "GenSigStartValue" SG_ 84 AdPrimPSSGroupSafe4HeadingPos5 32767;
BA_ "GenSigStartValue" SG_ 84 AdPrimPSSGroupSafe4HeadingPos6 32767;
BA_ "GenSigDataID" SG_ 88 AdPrimPSSGroupSafe5Chks "0x2C0";
BA_ "GenSigFuncType" SG_ 88 AdPrimPSSGroupSafe5Chks 28;
BA_ "GenSigFuncType" SG_ 88 AdPrimPSSGroupSafe5Cntr 27;
BA_ "GenSigStartValue" SG_ 88 AdPrimPSSGroupSafe5DeltaXPos1 131070;
BA_ "GenSigStartValue" SG_ 88 AdPrimPSSGroupSafe5DeltaXPos2 131070;
BA_ "GenSigStartValue" SG_ 88 AdPrimPSSGroupSafe5DeltaXPos3 131070;
BA_ "GenSigStartValue" SG_ 88 AdPrimPSSGroupSafe5DeltaXPos4 131070;
BA_ "GenSigStartValue" SG_ 88 AdPrimPSSGroupSafe5DeltaXPos5 131070;
BA_ "GenSigStartValue" SG_ 88 AdPrimPSSGroupSafe5DeltaXPos6 131070;
BA_ "GenSigStartValue" SG_ 88 AdPrimPSSGroupSafe5DeltaYPos1 131070;
BA_ "GenSigStartValue" SG_ 88 AdPrimPSSGroupSafe5DeltaYPos2 131070;
BA_ "GenSigStartValue" SG_ 88 AdPrimPSSGroupSafe5DeltaYPos3 131070;
BA_ "GenSigStartValue" SG_ 88 AdPrimPSSGroupSafe5DeltaYPos4 131070;
BA_ "GenSigStartValue" SG_ 88 AdPrimPSSGroupSafe5DeltaYPos5 131070;
BA_ "GenSigStartValue" SG_ 88 AdPrimPSSGroupSafe5DeltaYPos6 131070;
BA_ "GenSigStartValue" SG_ 88 AdPrimPSSGroupSafe5HeadingPos1 32767;
BA_ "GenSigStartValue" SG_ 88 AdPrimPSSGroupSafe5HeadingPos2 32767;
BA_ "GenSigStartValue" SG_ 88 AdPrimPSSGroupSafe5HeadingPos3 32767;
BA_ "GenSigStartValue" SG_ 88 AdPrimPSSGroupSafe5HeadingPos4 32767;
BA_ "GenSigStartValue" SG_ 88 AdPrimPSSGroupSafe5HeadingPos5 32767;
BA_ "GenSigStartValue" SG_ 88 AdPrimPSSGroupSafe5HeadingPos6 32767;
BA_ "GenSigDataID" SG_ 98 AdPrimPSSGroupSafe6Chks "0x2C7";
BA_ "GenSigFuncType" SG_ 98 AdPrimPSSGroupSafe6Chks 28;
BA_ "GenSigFuncType" SG_ 98 AdPrimPSSGroupSafe6Cntr 27;
BA_ "GenSigStartValue" SG_ 98 AdPrimPSSGroupSafe6DeltaXPos1 131070;
BA_ "GenSigStartValue" SG_ 98 AdPrimPSSGroupSafe6DeltaXPos2 131070;
BA_ "GenSigStartValue" SG_ 98 AdPrimPSSGroupSafe6DeltaXPos3 131070;
BA_ "GenSigStartValue" SG_ 98 AdPrimPSSGroupSafe6DeltaXPos4 131070;
BA_ "GenSigStartValue" SG_ 98 AdPrimPSSGroupSafe6DeltaXPos5 131070;
BA_ "GenSigStartValue" SG_ 98 AdPrimPSSGroupSafe6DeltaXPos6 131070;
BA_ "GenSigStartValue" SG_ 98 AdPrimPSSGroupSafe6DeltaYPos1 131070;
BA_ "GenSigStartValue" SG_ 98 AdPrimPSSGroupSafe6DeltaYPos2 131070;
BA_ "GenSigStartValue" SG_ 98 AdPrimPSSGroupSafe6DeltaYPos3 131070;
BA_ "GenSigStartValue" SG_ 98 AdPrimPSSGroupSafe6DeltaYPos4 131070;
BA_ "GenSigStartValue" SG_ 98 AdPrimPSSGroupSafe6DeltaYPos5 131070;
BA_ "GenSigStartValue" SG_ 98 AdPrimPSSGroupSafe6DeltaYPos6 131070;
BA_ "GenSigStartValue" SG_ 98 AdPrimPSSGroupSafe6HeadingPos1 32767;
BA_ "GenSigStartValue" SG_ 98 AdPrimPSSGroupSafe6HeadingPos2 32767;
BA_ "GenSigStartValue" SG_ 98 AdPrimPSSGroupSafe6HeadingPos3 32767;
BA_ "GenSigStartValue" SG_ 98 AdPrimPSSGroupSafe6HeadingPos4 32767;
BA_ "GenSigStartValue" SG_ 98 AdPrimPSSGroupSafe6HeadingPos5 32767;
BA_ "GenSigStartValue" SG_ 98 AdPrimPSSGroupSafe6HeadingPos6 32767;
BA_ "GenSigDataID" SG_ 100 AdPrimPSSGroupSafe7Chks "0x2C8";
BA_ "GenSigFuncType" SG_ 100 AdPrimPSSGroupSafe7Chks 28;
BA_ "GenSigFuncType" SG_ 100 AdPrimPSSGroupSafe7Cntr 27;
BA_ "GenSigStartValue" SG_ 100 AdPrimPSSGroupSafe7DeltaXPos1 131070;
BA_ "GenSigStartValue" SG_ 100 AdPrimPSSGroupSafe7DeltaXPos2 131070;
BA_ "GenSigStartValue" SG_ 100 AdPrimPSSGroupSafe7DeltaXPos3 131070;
BA_ "GenSigStartValue" SG_ 100 AdPrimPSSGroupSafe7DeltaXPos4 131070;
BA_ "GenSigStartValue" SG_ 100 AdPrimPSSGroupSafe7DeltaXPos5 131070;
BA_ "GenSigStartValue" SG_ 100 AdPrimPSSGroupSafe7DeltaXPos6 131070;
BA_ "GenSigStartValue" SG_ 100 AdPrimPSSGroupSafe7DeltaYPos1 131070;
BA_ "GenSigStartValue" SG_ 100 AdPrimPSSGroupSafe7DeltaYPos2 131070;
BA_ "GenSigStartValue" SG_ 100 AdPrimPSSGroupSafe7DeltaYPos3 131070;
BA_ "GenSigStartValue" SG_ 100 AdPrimPSSGroupSafe7DeltaYPos4 131070;
BA_ "GenSigStartValue" SG_ 100 AdPrimPSSGroupSafe7DeltaYPos5 131070;
BA_ "GenSigStartValue" SG_ 100 AdPrimPSSGroupSafe7DeltaYPos6 131070;
BA_ "GenSigStartValue" SG_ 100 AdPrimPSSGroupSafe7HeadingPos1 32767;
BA_ "GenSigStartValue" SG_ 100 AdPrimPSSGroupSafe7HeadingPos2 32767;
BA_ "GenSigStartValue" SG_ 100 AdPrimPSSGroupSafe7HeadingPos3 32767;
BA_ "GenSigStartValue" SG_ 100 AdPrimPSSGroupSafe7HeadingPos4 32767;
BA_ "GenSigStartValue" SG_ 100 AdPrimPSSGroupSafe7HeadingPos5 32767;
BA_ "GenSigStartValue" SG_ 100 AdPrimPSSGroupSafe7HeadingPos6 32767;
BA_ "GenSigDataID" SG_ 104 AdPrimPSSGroupSafe8Chks "0x2CD";
BA_ "GenSigFuncType" SG_ 104 AdPrimPSSGroupSafe8Chks 28;
BA_ "GenSigFuncType" SG_ 104 AdPrimPSSGroupSafe8Cntr 27;
BA_ "GenSigStartValue" SG_ 104 AdPrimPSSGroupSafe8DeltaXPos1 131070;
BA_ "GenSigStartValue" SG_ 104 AdPrimPSSGroupSafe8DeltaXPos2 131070;
BA_ "GenSigStartValue" SG_ 104 AdPrimPSSGroupSafe8DeltaXPos3 131070;
BA_ "GenSigStartValue" SG_ 104 AdPrimPSSGroupSafe8DeltaXPos4 131070;
BA_ "GenSigStartValue" SG_ 104 AdPrimPSSGroupSafe8DeltaXPos5 131070;
BA_ "GenSigStartValue" SG_ 104 AdPrimPSSGroupSafe8DeltaXPos6 131070;
BA_ "GenSigStartValue" SG_ 104 AdPrimPSSGroupSafe8DeltaYPos1 131070;
BA_ "GenSigStartValue" SG_ 104 AdPrimPSSGroupSafe8DeltaYPos2 131070;
BA_ "GenSigStartValue" SG_ 104 AdPrimPSSGroupSafe8DeltaYPos3 131070;
BA_ "GenSigStartValue" SG_ 104 AdPrimPSSGroupSafe8DeltaYPos4 131070;
BA_ "GenSigStartValue" SG_ 104 AdPrimPSSGroupSafe8DeltaYPos5 131070;
BA_ "GenSigStartValue" SG_ 104 AdPrimPSSGroupSafe8DeltaYPos6 131070;
BA_ "GenSigStartValue" SG_ 104 AdPrimPSSGroupSafe8HeadingPos1 32767;
BA_ "GenSigStartValue" SG_ 104 AdPrimPSSGroupSafe8HeadingPos2 32767;
BA_ "GenSigStartValue" SG_ 104 AdPrimPSSGroupSafe8HeadingPos3 32767;
BA_ "GenSigStartValue" SG_ 104 AdPrimPSSGroupSafe8HeadingPos4 32767;
BA_ "GenSigStartValue" SG_ 104 AdPrimPSSGroupSafe8HeadingPos5 32767;
BA_ "GenSigStartValue" SG_ 104 AdPrimPSSGroupSafe8HeadingPos6 32767;
BA_ "GenSigDataID" SG_ 34 AdPrimWhlAgReqGroupSafeChks "0x1B2";
BA_ "GenSigFuncType" SG_ 34 AdPrimWhlAgReqGroupSafeChks 15;
BA_ "GenSigFuncType" SG_ 34 AdPrimWhlAgReqGroupSafeCntr 16;
BA_ "GenSigStartValue" SG_ 34 AdPrimWhlAgReqGroupSafeWhlAgReq 16194.000762;
BA_ "GenSigDataID" SG_ 60 AdPrimSafeStopReqSafeChks "0x202";
BA_ "GenSigFuncType" SG_ 60 AdPrimSafeStopReqSafeChks 15;
BA_ "GenSigFuncType" SG_ 60 AdPrimSafeStopReqSafeCntr 16;
BA_ "GenSigDataID" SG_ 60 SDSFltMgrStsSafeChks "0x746";
BA_ "GenSigFuncType" SG_ 60 SDSFltMgrStsSafeChks 15;
BA_ "GenSigFuncType" SG_ 60 SDSFltMgrStsSafeCntr 16;
BA_ "GenSigDataID" SG_ 40 PrimMonTiSyncMsgChks "0x71C";
BA_ "GenSigFuncType" SG_ 40 PrimMonTiSyncMsgChks 15;
BA_ "GenSigSendType" SG_ 40 PrimMonTiSyncMsgChks 1;
BA_ "GenSigFuncType" SG_ 40 PrimMonTiSyncMsgCntr 16;
BA_ "GenSigSendType" SG_ 40 PrimMonTiSyncMsgCntr 1;
BA_ "GenSigSendType" SG_ 40 PrimMonTiSyncMsgTiStampNanoSec 1;
BA_ "GenSigSendType" SG_ 40 PrimMonTiSyncMsgTiStampSec 1;
VAL_ 20 PinionSteerAg1Qf 0 "GenQf1_UndefindDataAccur" 1 "GenQf1_TmpUndefdData" 2 "GenQf1_DataAccurNotWithinSpcn" 3 "GenQf1_AccurData" ;
VAL_ 20 PinionSteerAgSpd1Qf 0 "GenQf1_UndefindDataAccur" 1 "GenQf1_TmpUndefdData" 2 "GenQf1_DataAccurNotWithinSpcn" 3 "GenQf1_AccurData" ;
VAL_ 43 AdPrimMotTqASILThrshldExcdThrshl 0 "OnOff1_Off" 1 "OnOff1_On" ;
VAL_ 43 PrimPoseMonSafeSafeQf 0 "SafeQf_Ukwn" 1 "SafeQf_NoIntgrty" 2 "SafeQf_IntgrtyCmprmd" 3 "SafeQf_DataIntgrtyOK" ;
VAL_ 32 AdPrimWhlAgEstimdGroupSafeQf1 0 "Qf1_DevOfDataUndefd" 1 "Qf1_DataTmpUndefdAndEvlnInProgs" 2 "Qf1_DevOfDataNotWithinRngAllwd" 3 "Qf1_DataCalcdWithDevDefd" ;
VAL_ 32 PrimALatDataRawSafeMinMaxQf 0 "SafeQf_Ukwn" 1 "SafeQf_NoIntgrty" 2 "SafeQf_IntgrtyCmprmd" 3 "SafeQf_DataIntgrtyOK" ;
VAL_ 32 PrimALatDataRawSafeNomQf 0 "GenQf1_UndefindDataAccur" 1 "GenQf1_TmpUndefdData" 2 "GenQf1_DataAccurNotWithinSpcn" 3 "GenQf1_AccurData" ;
VAL_ 32 PrimAxleSlipStsAndRelAgFrntAxle 0 "SlipSts_Err" 1 "SlipSts_NoInfo" 2 "SlipSts_NotSlip" 3 "SlipSts_Slip" ;
VAL_ 32 PrimAxleSlipStsAndRelAgIntvSts 0 "IntvSts_Err" 1 "IntvSts_NoInfo" 2 "IntvSts_NoIntv" 3 "IntvSts_Intv" ;
VAL_ 32 PrimAxleSlipStsAndRelAgReAxle 0 "SlipSts_Err" 1 "SlipSts_NoInfo" 2 "SlipSts_NotSlip" 3 "SlipSts_Slip" ;
VAL_ 32 PrimAxleSlipStsAndRelAgRelPitchQ 0 "Qly2_Flt" 1 "Qly2_NoInfo" 2 "Qly2_Vld" ;
VAL_ 32 PrimAxleSlipStsAndRelAgRelRolQf 0 "Qly2_Flt" 1 "Qly2_NoInfo" 2 "Qly2_Vld" ;
VAL_ 32 PrimVLatSafeMinMaxQf 0 "SafeQf_Ukwn" 1 "SafeQf_NoIntgrty" 2 "SafeQf_IntgrtyCmprmd" 3 "SafeQf_DataIntgrtyOK" ;
VAL_ 32 PrimVLatSafeNomQf 0 "GenQf1_UndefindDataAccur" 1 "GenQf1_TmpUndefdData" 2 "GenQf1_DataAccurNotWithinSpcn" 3 "GenQf1_AccurData" ;
VAL_ 32 PrimWhlRotDirReSafe1Le 0 "WhlRotlDirStd1_Undefd" 1 "WhlRotlDirStd1_StandStill" 2 "WhlRotlDirStd1_Fwd" 3 "WhlRotlDirStd1_Backw" ;
VAL_ 32 PrimWhlRotDirReSafe1LeQf 0 "Qf1_DevOfDataUndefd" 1 "Qf1_DataTmpUndefdAndEvlnInProgs" 2 "Qf1_DevOfDataNotWithinRngAllwd" 3 "Qf1_DataCalcdWithDevDefd" ;
VAL_ 32 PrimWhlRotDirReSafe1Ri 0 "WhlRotlDirStd1_Undefd" 1 "WhlRotlDirStd1_StandStill" 2 "WhlRotlDirStd1_Fwd" 3 "WhlRotlDirStd1_Backw" ;
VAL_ 32 PrimWhlRotDirReSafe1RiQf 0 "Qf1_DevOfDataUndefd" 1 "Qf1_DataTmpUndefdAndEvlnInProgs" 2 "Qf1_DevOfDataNotWithinRngAllwd" 3 "Qf1_DataCalcdWithDevDefd" ;
VAL_ 32 PrimWhlRotToothCntrWhlRotTo_0000 0 "GenQf1_UndefindDataAccur" 1 "GenQf1_TmpUndefdData" 2 "GenQf1_DataAccurNotWithinSpcn" 3 "GenQf1_AccurData" ;
VAL_ 32 PrimWhlRotToothCntrWhlRotTo_0002 0 "GenQf1_UndefindDataAccur" 1 "GenQf1_TmpUndefdData" 2 "GenQf1_DataAccurNotWithinSpcn" 3 "GenQf1_AccurData" ;
VAL_ 32 PrimWhlRotToothCntrWhlRotTo_0004 0 "GenQf1_UndefindDataAccur" 1 "GenQf1_TmpUndefdData" 2 "GenQf1_DataAccurNotWithinSpcn" 3 "GenQf1_AccurData" ;
VAL_ 32 PrimWhlRotToothCntrWhlRotTo_0006 0 "GenQf1_UndefindDataAccur" 1 "GenQf1_TmpUndefdData" 2 "GenQf1_DataAccurNotWithinSpcn" 3 "GenQf1_AccurData" ;
VAL_ 32 PrimYawRateSafeMinMaxQf 0 "SafeQf_Ukwn" 1 "SafeQf_NoIntgrty" 2 "SafeQf_IntgrtyCmprmd" 3 "SafeQf_DataIntgrtyOK" ;
VAL_ 32 PrimYawRateSafeNomQf 0 "GenQf1_UndefindDataAccur" 1 "GenQf1_TmpUndefdData" 2 "GenQf1_DataAccurNotWithinSpcn" 3 "GenQf1_AccurData" ;
VAL_ 21 PrimVehMSafeNomQf 0 "GenQf1_UndefindDataAccur" 1 "GenQf1_TmpUndefdData" 2 "GenQf1_DataAccurNotWithinSpcn" 3 "GenQf1_AccurData" ;
VAL_ 21 PrimVehMSafeSafeQf 0 "SafeQf_Ukwn" 1 "SafeQf_NoIntgrty" 2 "SafeQf_IntgrtyCmprmd" 3 "SafeQf_DataIntgrtyOK" ;
VAL_ 21 PrimWhlAgSpdFrntSafeLeQf 0 "GenQf1_UndefindDataAccur" 1 "GenQf1_TmpUndefdData" 2 "GenQf1_DataAccurNotWithinSpcn" 3 "GenQf1_AccurData" ;
VAL_ 21 PrimWhlAgSpdFrntSafeRiQf 0 "GenQf1_UndefindDataAccur" 1 "GenQf1_TmpUndefdData" 2 "GenQf1_DataAccurNotWithinSpcn" 3 "GenQf1_AccurData" ;
VAL_ 21 PrimWhlAgSpdReSafeLeQf 0 "GenQf1_UndefindDataAccur" 1 "GenQf1_TmpUndefdData" 2 "GenQf1_DataAccurNotWithinSpcn" 3 "GenQf1_AccurData" ;
VAL_ 21 PrimWhlAgSpdReSafeRiQf 0 "GenQf1_UndefindDataAccur" 1 "GenQf1_TmpUndefdData" 2 "GenQf1_DataAccurNotWithinSpcn" 3 "GenQf1_AccurData" ;
VAL_ 58 AdPrimSafeStopActvGroupSafePlatf 0 "NoYes1_No" 1 "NoYes1_Yes" ;
VAL_ 58 SSMDegradedssmdegraded 0 "SSMDegraded_SftyCritFlt" 1 "SSMDegraded_SftyCritLatentFlt" 2 "SSMDegraded_PSSFlt" 3 "SSMDegraded_NonSftyCritFlt" 4 "SSMDegraded_NoFlt" ;
VAL_ 257 SteerMechMonSts 0 "SteerMechMonSts_Unknown" 1 "SteerMechMonSts_WithinNomBounds" 2 "SteerMechMonSts_SmallOffset" 3 "SteerMechMonSts_LargeOffset" ;
VAL_ 60 AdPrimSafeStopReqSafeSafeStopReq 0 "NoYes1_No" 1 "NoYes1_Yes" ;
VAL_ 60 SDSFltMgrStsSafeSDSFltMgrSts 0 "SDSFltMgrSts_Nom" 1 "SDSFltMgrSts_Resd" 2 "SDSFltMgrSts_Mntn" 3 "SDSFltMgrSts_Resd1" 4 "SDSFltMgrSts_CmptRtrn" 5 "SDSFltMgrSts_Resd2" 6 "SDSFltMgrSts_SS" 7 "SDSFltMgrSts_Resd3" 8 "SDSFltMgrSts_SS1" 9 "SDSFltMgrSts_Resd4" 10 "SDSFltMgrSts_VIMSS" 11 "SDSFltMgrSts_Resd5" ;
SIG_GROUP_ 20 PinionSteerAg1Group 1 : PinionSteerAg1 PinionSteerAg1Qf;
SIG_GROUP_ 20 PinionSteerAgSpd1Group 1 : PinionSteerAgSpd1 PinionSteerAgSpd1Qf;
SIG_GROUP_ 43 AdPrimMotTqASILThrshldExcd 1 : AdPrimMotTqASILThrshldExcdChks AdPrimMotTqASILThrshldExcdCntr AdPrimMotTqASILThrshldExcdThrshl;
SIG_GROUP_ 43 PrimPoseMonSafe 1 : PrimPoseMonSafeChks PrimPoseMonSafeCntr PrimPoseMonSafeLatErr PrimPoseMonSafeLgtErr PrimPoseMonSafeSafeQf PrimPoseMonSafeYawErr;
SIG_GROUP_ 32 AdPrimWhlAgEstimdGroupSafe 1 : AdPrimWhlAgEstimdGroupSafeChks AdPrimWhlAgEstimdGroupSafeCntr AdPrimWhlAgEstimdGroupSafeQf1 AdPrimWhlAgEstimdGroupSafeWhlAg AdPrimWhlAgEstimdGroupSafeWhlAgR;
SIG_GROUP_ 32 PrimALatDataRawSafe 1 : PrimALatDataRawSafeChks PrimALatDataRawSafeCntr PrimALatDataRawSafeMax PrimALatDataRawSafeMin PrimALatDataRawSafeMinMaxQf PrimALatDataRawSafeNom PrimALatDataRawSafeNomQf;
SIG_GROUP_ 32 PrimAxleSlipStsAndRelAg 1 : PrimAxleSlipStsAndRelAgFrntAxle PrimAxleSlipStsAndRelAgIntvSts PrimAxleSlipStsAndRelAgReAxle PrimAxleSlipStsAndRelAgRelPitch PrimAxleSlipStsAndRelAgRelPitchQ PrimAxleSlipStsAndRelAgRelRoll PrimAxleSlipStsAndRelAgRelRolQf;
SIG_GROUP_ 32 PrimVLatSafe 1 : PrimVLatSafeChks PrimVLatSafeCntr PrimVLatSafeMax PrimVLatSafeMin PrimVLatSafeMinMaxQf PrimVLatSafeNom PrimVLatSafeNomQf;
SIG_GROUP_ 32 PrimWhlRotDirReSafe1 1 : PrimWhlRotDirReSafe1Chks PrimWhlRotDirReSafe1Cntr PrimWhlRotDirReSafe1Le PrimWhlRotDirReSafe1LeQf PrimWhlRotDirReSafe1Ri PrimWhlRotDirReSafe1RiQf;
SIG_GROUP_ 32 PrimWhlRotToothCntr 1 : PrimWhlRotToothCntrChks PrimWhlRotToothCntrCntr PrimWhlRotToothCntrWhlRotToothCn PrimWhlRotToothCntrWhlRotTo_0000 PrimWhlRotToothCntrWhlRotTo_0001 PrimWhlRotToothCntrWhlRotTo_0002 PrimWhlRotToothCntrWhlRotTo_0003 PrimWhlRotToothCntrWhlRotTo_0004 PrimWhlRotToothCntrWhlRotTo_0005 PrimWhlRotToothCntrWhlRotTo_0006;
SIG_GROUP_ 32 PrimYawRateSafe 1 : PrimYawRateSafeChks PrimYawRateSafeCntr PrimYawRateSafeMax PrimYawRateSafeMin PrimYawRateSafeMinMaxQf PrimYawRateSafeNom PrimYawRateSafeNomQf;
SIG_GROUP_ 21 PrimVehMSafe 1 : PrimVehMSafeChks PrimVehMSafeCntr PrimVehMSafeNomQf PrimVehMSafeSafeQf PrimVehMSafeVehMMax PrimVehMSafeVehMMin PrimVehMSafeVehMNom;
SIG_GROUP_ 21 PrimWhlAgSpdFrntSafe 1 : PrimWhlAgSpdFrntSafeChks PrimWhlAgSpdFrntSafeCntr PrimWhlAgSpdFrntSafeLe PrimWhlAgSpdFrntSafeLeQf PrimWhlAgSpdFrntSafeRi PrimWhlAgSpdFrntSafeRiQf;
SIG_GROUP_ 21 PrimWhlAgSpdReSafe 1 : PrimWhlAgSpdReSafeChks PrimWhlAgSpdReSafeCntr PrimWhlAgSpdReSafeLe PrimWhlAgSpdReSafeLeQf PrimWhlAgSpdReSafeRi PrimWhlAgSpdReSafeRiQf;
SIG_GROUP_ 52 AdPrimWhlAgRateLimEstimdSafe 1 : AdPrimWhlAgRateLimEstimdSafeAdWh AdPrimWhlAgRateLimEstimdSafeChks AdPrimWhlAgRateLimEstimdSafeCntr;
SIG_GROUP_ 52 PrimMaxALatEstimdGroup 1 : PrimMaxALatEstimdGroupAccelerati PrimMaxALatEstimdGroupJerk;
SIG_GROUP_ 58 AdPrimSafeStopActvGroupSafe 1 : AdPrimSafeStopActvGroupSafeChks AdPrimSafeStopActvGroupSafeCntr AdPrimSafeStopActvGroupSafePlatf;
SIG_GROUP_ 58 SSMDegraded 1 : SSMDegradedchks SSMDegradedcntr SSMDegradedssmdegraded;
SIG_GROUP_ 33 AdPrimPose 1 : AdPrimPoseAX AdPrimPoseAXConf AdPrimPoseAY AdPrimPoseAYConf AdPrimPoseAZ AdPrimPoseAZConf AdPrimPoseChks AdPrimPoseCntr AdPrimPoseDataID AdPrimPosePitch AdPrimPosePitchConf AdPrimPosePitchRate AdPrimPosePitchRateConf AdPrimPosePosX AdPrimPosePosXConf AdPrimPosePosY AdPrimPosePosYConf AdPrimPoseRoll AdPrimPoseRollConf AdPrimPoseRollRate AdPrimPoseRollRateConf AdPrimPoseTiStampNanoSec AdPrimPoseTiStampSec AdPrimPoseVX AdPrimPoseVXConf AdPrimPoseVY AdPrimPoseVYConf AdPrimPoseYaw AdPrimPoseYawConf AdPrimPoseYawRate AdPrimPoseYawRateConf;
SIG_GROUP_ 65 AdPrimPSSGroupSafe0 1 : AdPrimPSSGroupSafe0Chks AdPrimPSSGroupSafe0Cntr AdPrimPSSGroupSafe0DataID AdPrimPSSGroupSafe0DeltaTPos1 AdPrimPSSGroupSafe0DeltaTPos2 AdPrimPSSGroupSafe0DeltaXPos1 AdPrimPSSGroupSafe0DeltaXPos2 AdPrimPSSGroupSafe0DeltaYPos1 AdPrimPSSGroupSafe0DeltaYPos2 AdPrimPSSGroupSafe0HeadingPos1 AdPrimPSSGroupSafe0HeadingPos2 AdPrimPSSGroupSafe0InitHeading AdPrimPSSGroupSafe0InitPosX AdPrimPSSGroupSafe0InitPosY AdPrimPSSGroupSafe0TiStampNanoSe AdPrimPSSGroupSafe0TiStampSec AdPrimPSSGroupSafe0TrajectID;
SIG_GROUP_ 68 AdPrimPSSGroupSafe1 1 : AdPrimPSSGroupSafe1Chks AdPrimPSSGroupSafe1Cntr AdPrimPSSGroupSafe1DataID AdPrimPSSGroupSafe1DeltaTPos1 AdPrimPSSGroupSafe1DeltaTPos2 AdPrimPSSGroupSafe1DeltaTPos3 AdPrimPSSGroupSafe1DeltaTPos4 AdPrimPSSGroupSafe1DeltaTPos5 AdPrimPSSGroupSafe1DeltaTPos6 AdPrimPSSGroupSafe1DeltaXPos1 AdPrimPSSGroupSafe1DeltaXPos2 AdPrimPSSGroupSafe1DeltaXPos3 AdPrimPSSGroupSafe1DeltaXPos4 AdPrimPSSGroupSafe1DeltaXPos5 AdPrimPSSGroupSafe1DeltaXPos6 AdPrimPSSGroupSafe1DeltaYPos1 AdPrimPSSGroupSafe1DeltaYPos2 AdPrimPSSGroupSafe1DeltaYPos3 AdPrimPSSGroupSafe1DeltaYPos4 AdPrimPSSGroupSafe1DeltaYPos5 AdPrimPSSGroupSafe1DeltaYPos6 AdPrimPSSGroupSafe1HeadingPos1 AdPrimPSSGroupSafe1HeadingPos2 AdPrimPSSGroupSafe1HeadingPos3 AdPrimPSSGroupSafe1HeadingPos4 AdPrimPSSGroupSafe1HeadingPos5 AdPrimPSSGroupSafe1HeadingPos6 AdPrimPSSGroupSafe1TrajectID;
SIG_GROUP_ 72 AdPrimPSSGroupSafe2 1 : AdPrimPSSGroupSafe2Chks AdPrimPSSGroupSafe2Cntr AdPrimPSSGroupSafe2DataID AdPrimPSSGroupSafe2DeltaTPos1 AdPrimPSSGroupSafe2DeltaTPos2 AdPrimPSSGroupSafe2DeltaTPos3 AdPrimPSSGroupSafe2DeltaTPos4 AdPrimPSSGroupSafe2DeltaTPos5 AdPrimPSSGroupSafe2DeltaTPos6 AdPrimPSSGroupSafe2DeltaXPos1 AdPrimPSSGroupSafe2DeltaXPos2 AdPrimPSSGroupSafe2DeltaXPos3 AdPrimPSSGroupSafe2DeltaXPos4 AdPrimPSSGroupSafe2DeltaXPos5 AdPrimPSSGroupSafe2DeltaXPos6 AdPrimPSSGroupSafe2DeltaYPos1 AdPrimPSSGroupSafe2DeltaYPos2 AdPrimPSSGroupSafe2DeltaYPos3 AdPrimPSSGroupSafe2DeltaYPos4 AdPrimPSSGroupSafe2DeltaYPos5 AdPrimPSSGroupSafe2DeltaYPos6 AdPrimPSSGroupSafe2HeadingPos1 AdPrimPSSGroupSafe2HeadingPos2 AdPrimPSSGroupSafe2HeadingPos3 AdPrimPSSGroupSafe2HeadingPos4 AdPrimPSSGroupSafe2HeadingPos5 AdPrimPSSGroupSafe2HeadingPos6 AdPrimPSSGroupSafe2TrajectID;
SIG_GROUP_ 82 AdPrimPSSGroupSafe3 1 : AdPrimPSSGroupSafe3Chks AdPrimPSSGroupSafe3Cntr AdPrimPSSGroupSafe3DataID AdPrimPSSGroupSafe3DeltaTPos1 AdPrimPSSGroupSafe3DeltaTPos2 AdPrimPSSGroupSafe3DeltaTPos3 AdPrimPSSGroupSafe3DeltaTPos4 AdPrimPSSGroupSafe3DeltaTPos5 AdPrimPSSGroupSafe3DeltaTPos6 AdPrimPSSGroupSafe3DeltaXPos1 AdPrimPSSGroupSafe3DeltaXPos2 AdPrimPSSGroupSafe3DeltaXPos3 AdPrimPSSGroupSafe3DeltaXPos4 AdPrimPSSGroupSafe3DeltaXPos5 AdPrimPSSGroupSafe3DeltaXPos6 AdPrimPSSGroupSafe3DeltaYPos1 AdPrimPSSGroupSafe3DeltaYPos2 AdPrimPSSGroupSafe3DeltaYPos3 AdPrimPSSGroupSafe3DeltaYPos4 AdPrimPSSGroupSafe3DeltaYPos5 AdPrimPSSGroupSafe3DeltaYPos6 AdPrimPSSGroupSafe3HeadingPos1 AdPrimPSSGroupSafe3HeadingPos2 AdPrimPSSGroupSafe3HeadingPos3 AdPrimPSSGroupSafe3HeadingPos4 AdPrimPSSGroupSafe3HeadingPos5 AdPrimPSSGroupSafe3HeadingPos6 AdPrimPSSGroupSafe3TrajectID;
SIG_GROUP_ 84 AdPrimPSSGroupSafe4 1 : AdPrimPSSGroupSafe4Chks AdPrimPSSGroupSafe4Cntr AdPrimPSSGroupSafe4DataID AdPrimPSSGroupSafe4DeltaTPos1 AdPrimPSSGroupSafe4DeltaTPos2 AdPrimPSSGroupSafe4DeltaTPos3 AdPrimPSSGroupSafe4DeltaTPos4 AdPrimPSSGroupSafe4DeltaTPos5 AdPrimPSSGroupSafe4DeltaTPos6 AdPrimPSSGroupSafe4DeltaXPos1 AdPrimPSSGroupSafe4DeltaXPos2 AdPrimPSSGroupSafe4DeltaXPos3 AdPrimPSSGroupSafe4DeltaXPos4 AdPrimPSSGroupSafe4DeltaXPos5 AdPrimPSSGroupSafe4DeltaXPos6 AdPrimPSSGroupSafe4DeltaYPos1 AdPrimPSSGroupSafe4DeltaYPos2 AdPrimPSSGroupSafe4DeltaYPos3 AdPrimPSSGroupSafe4DeltaYPos4 AdPrimPSSGroupSafe4DeltaYPos5 AdPrimPSSGroupSafe4DeltaYPos6 AdPrimPSSGroupSafe4HeadingPos1 AdPrimPSSGroupSafe4HeadingPos2 AdPrimPSSGroupSafe4HeadingPos3 AdPrimPSSGroupSafe4HeadingPos4 AdPrimPSSGroupSafe4HeadingPos5 AdPrimPSSGroupSafe4HeadingPos6 AdPrimPSSGroupSafe4TrajectID;
SIG_GROUP_ 88 AdPrimPSSGroupSafe5 1 : AdPrimPSSGroupSafe5Chks AdPrimPSSGroupSafe5Cntr AdPrimPSSGroupSafe5DataID AdPrimPSSGroupSafe5DeltaTPos1 AdPrimPSSGroupSafe5DeltaTPos2 AdPrimPSSGroupSafe5DeltaTPos3 AdPrimPSSGroupSafe5DeltaTPos4 AdPrimPSSGroupSafe5DeltaTPos5 AdPrimPSSGroupSafe5DeltaTPos6 AdPrimPSSGroupSafe5DeltaXPos1 AdPrimPSSGroupSafe5DeltaXPos2 AdPrimPSSGroupSafe5DeltaXPos3 AdPrimPSSGroupSafe5DeltaXPos4 AdPrimPSSGroupSafe5DeltaXPos5 AdPrimPSSGroupSafe5DeltaXPos6 AdPrimPSSGroupSafe5DeltaYPos1 AdPrimPSSGroupSafe5DeltaYPos2 AdPrimPSSGroupSafe5DeltaYPos3 AdPrimPSSGroupSafe5DeltaYPos4 AdPrimPSSGroupSafe5DeltaYPos5 AdPrimPSSGroupSafe5DeltaYPos6 AdPrimPSSGroupSafe5HeadingPos1 AdPrimPSSGroupSafe5HeadingPos2 AdPrimPSSGroupSafe5HeadingPos3 AdPrimPSSGroupSafe5HeadingPos4 AdPrimPSSGroupSafe5HeadingPos5 AdPrimPSSGroupSafe5HeadingPos6 AdPrimPSSGroupSafe5TrajectID;
SIG_GROUP_ 98 AdPrimPSSGroupSafe6 1 : AdPrimPSSGroupSafe6Chks AdPrimPSSGroupSafe6Cntr AdPrimPSSGroupSafe6DataID AdPrimPSSGroupSafe6DeltaTPos1 AdPrimPSSGroupSafe6DeltaTPos2 AdPrimPSSGroupSafe6DeltaTPos3 AdPrimPSSGroupSafe6DeltaTPos4 AdPrimPSSGroupSafe6DeltaTPos5 AdPrimPSSGroupSafe6DeltaTPos6 AdPrimPSSGroupSafe6DeltaXPos1 AdPrimPSSGroupSafe6DeltaXPos2 AdPrimPSSGroupSafe6DeltaXPos3 AdPrimPSSGroupSafe6DeltaXPos4 AdPrimPSSGroupSafe6DeltaXPos5 AdPrimPSSGroupSafe6DeltaXPos6 AdPrimPSSGroupSafe6DeltaYPos1 AdPrimPSSGroupSafe6DeltaYPos2 AdPrimPSSGroupSafe6DeltaYPos3 AdPrimPSSGroupSafe6DeltaYPos4 AdPrimPSSGroupSafe6DeltaYPos5 AdPrimPSSGroupSafe6DeltaYPos6 AdPrimPSSGroupSafe6HeadingPos1 AdPrimPSSGroupSafe6HeadingPos2 AdPrimPSSGroupSafe6HeadingPos3 AdPrimPSSGroupSafe6HeadingPos4 AdPrimPSSGroupSafe6HeadingPos5 AdPrimPSSGroupSafe6HeadingPos6 AdPrimPSSGroupSafe6TrajectID;
SIG_GROUP_ 100 AdPrimPSSGroupSafe7 1 : AdPrimPSSGroupSafe7Chks AdPrimPSSGroupSafe7Cntr AdPrimPSSGroupSafe7DataID AdPrimPSSGroupSafe7DeltaTPos1 AdPrimPSSGroupSafe7DeltaTPos2 AdPrimPSSGroupSafe7DeltaTPos3 AdPrimPSSGroupSafe7DeltaTPos4 AdPrimPSSGroupSafe7DeltaTPos5 AdPrimPSSGroupSafe7DeltaTPos6 AdPrimPSSGroupSafe7DeltaXPos1 AdPrimPSSGroupSafe7DeltaXPos2 AdPrimPSSGroupSafe7DeltaXPos3 AdPrimPSSGroupSafe7DeltaXPos4 AdPrimPSSGroupSafe7DeltaXPos5 AdPrimPSSGroupSafe7DeltaXPos6 AdPrimPSSGroupSafe7DeltaYPos1 AdPrimPSSGroupSafe7DeltaYPos2 AdPrimPSSGroupSafe7DeltaYPos3 AdPrimPSSGroupSafe7DeltaYPos4 AdPrimPSSGroupSafe7DeltaYPos5 AdPrimPSSGroupSafe7DeltaYPos6 AdPrimPSSGroupSafe7HeadingPos1 AdPrimPSSGroupSafe7HeadingPos2 AdPrimPSSGroupSafe7HeadingPos3 AdPrimPSSGroupSafe7HeadingPos4 AdPrimPSSGroupSafe7HeadingPos5 AdPrimPSSGroupSafe7HeadingPos6 AdPrimPSSGroupSafe7TrajectID;
SIG_GROUP_ 104 AdPrimPSSGroupSafe8 1 : AdPrimPSSGroupSafe8Chks AdPrimPSSGroupSafe8Cntr AdPrimPSSGroupSafe8DataID AdPrimPSSGroupSafe8DeltaTPos1 AdPrimPSSGroupSafe8DeltaTPos2 AdPrimPSSGroupSafe8DeltaTPos3 AdPrimPSSGroupSafe8DeltaTPos4 AdPrimPSSGroupSafe8DeltaTPos5 AdPrimPSSGroupSafe8DeltaTPos6 AdPrimPSSGroupSafe8DeltaXPos1 AdPrimPSSGroupSafe8DeltaXPos2 AdPrimPSSGroupSafe8DeltaXPos3 AdPrimPSSGroupSafe8DeltaXPos4 AdPrimPSSGroupSafe8DeltaXPos5 AdPrimPSSGroupSafe8DeltaXPos6 AdPrimPSSGroupSafe8DeltaYPos1 AdPrimPSSGroupSafe8DeltaYPos2 AdPrimPSSGroupSafe8DeltaYPos3 AdPrimPSSGroupSafe8DeltaYPos4 AdPrimPSSGroupSafe8DeltaYPos5 AdPrimPSSGroupSafe8DeltaYPos6 AdPrimPSSGroupSafe8HeadingPos1 AdPrimPSSGroupSafe8HeadingPos2 AdPrimPSSGroupSafe8HeadingPos3 AdPrimPSSGroupSafe8HeadingPos4 AdPrimPSSGroupSafe8HeadingPos5 AdPrimPSSGroupSafe8HeadingPos6 AdPrimPSSGroupSafe8TrajectID;
SIG_GROUP_ 34 AdPrimWhlAgReqGroupSafe 1 : AdPrimWhlAgReqGroupSafeChks AdPrimWhlAgReqGroupSafeCntr AdPrimWhlAgReqGroupSafeWhlAgReq;
SIG_GROUP_ 60 AdPrimSafeStopReqSafe 1 : AdPrimSafeStopReqSafeChks AdPrimSafeStopReqSafeCntr AdPrimSafeStopReqSafeSafeStopReq;
SIG_GROUP_ 60 SDSFltMgrStsSafe 1 : SDSFltMgrStsSafeChks SDSFltMgrStsSafeCntr SDSFltMgrStsSafeSDSFltMgrSts;
SIG_GROUP_ 40 PrimMonTiSyncMsg 1 : PrimMonTiSyncMsgChks PrimMonTiSyncMsgCntr PrimMonTiSyncMsgTiStampNanoSec PrimMonTiSyncMsgTiStampSec;
